VERSION ""

NS_ :

BS_:

BU_: FBD_HL IPB_App1 FBD_HM FBD_HR FBD_Miko FBD_MM FBD_Trunk FBD_VL FBD_VM FBD_VR Diagnosetool_CAN_FD_IPB_41

BO_ 900 TPBLEParameter_FBD_VM_FBD_MM: 64 FBD_VM
 SG_ TPBLEParameter_FBD_VM_FBD_MM_Byt : 0|8@1+ (1.0,0) [0|255] "" FBD_MM
 SG_ TPBLEParameter_FBD_VM_FBD_MM_B_2 : 8|8@1+ (1.0,0) [0|255] "" FBD_MM
 SG_ TPBLEParameter_FBD_VM_FBD_MM_B_3 : 16|8@1+ (1.0,0) [0|255] "" FBD_MM
 SG_ TPBLEParameter_FBD_VM_FBD_MM_B_4 : 24|8@1+ (1.0,0) [0|255] "" FBD_MM
 SG_ TPBLEParameter_FBD_VM_FBD_MM_B_5 : 32|8@1+ (1.0,0) [0|255] "" FBD_MM
 SG_ TPBLEParameter_FBD_VM_FBD_MM_B_6 : 40|8@1+ (1.0,0) [0|255] "" FBD_MM
 SG_ TPBLEParameter_FBD_VM_FBD_MM_B_7 : 48|8@1+ (1.0,0) [0|255] "" FBD_MM
 SG_ TPBLEParameter_FBD_VM_FBD_MM_B_8 : 56|8@1+ (1.0,0) [0|255] "" FBD_MM
 SG_ TPBLEParameter_FBD_VM_FBD_MM_B_9 : 64|8@1+ (1.0,0) [0|255] "" FBD_MM
 SG_ TPBLEParameter_FBD_VM_FBD_MM__10 : 72|8@1+ (1.0,0) [0|255] "" FBD_MM
 SG_ TPBLEParameter_FBD_VM_FBD_MM__11 : 80|8@1+ (1.0,0) [0|255] "" FBD_MM
 SG_ TPBLEParameter_FBD_VM_FBD_MM__12 : 88|8@1+ (1.0,0) [0|255] "" FBD_MM
 SG_ TPBLEParameter_FBD_VM_FBD_MM__13 : 96|8@1+ (1.0,0) [0|255] "" FBD_MM
 SG_ TPBLEParameter_FBD_VM_FBD_MM__14 : 104|8@1+ (1.0,0) [0|255] "" FBD_MM
 SG_ TPBLEParameter_FBD_VM_FBD_MM__15 : 112|8@1+ (1.0,0) [0|255] "" FBD_MM
 SG_ TPBLEParameter_FBD_VM_FBD_MM__16 : 120|8@1+ (1.0,0) [0|255] "" FBD_MM
 SG_ TPBLEParameter_FBD_VM_FBD_MM__17 : 128|8@1+ (1.0,0) [0|255] "" FBD_MM
 SG_ TPBLEParameter_FBD_VM_FBD_MM__18 : 136|8@1+ (1.0,0) [0|255] "" FBD_MM
 SG_ TPBLEParameter_FBD_VM_FBD_MM__19 : 144|8@1+ (1.0,0) [0|255] "" FBD_MM
 SG_ TPBLEParameter_FBD_VM_FBD_MM__20 : 152|8@1+ (1.0,0) [0|255] "" FBD_MM
 SG_ TPBLEParameter_FBD_VM_FBD_MM__21 : 160|8@1+ (1.0,0) [0|255] "" FBD_MM
 SG_ TPBLEParameter_FBD_VM_FBD_MM__22 : 168|8@1+ (1.0,0) [0|255] "" FBD_MM
 SG_ TPBLEParameter_FBD_VM_FBD_MM__23 : 176|8@1+ (1.0,0) [0|255] "" FBD_MM
 SG_ TPBLEParameter_FBD_VM_FBD_MM__24 : 184|8@1+ (1.0,0) [0|255] "" FBD_MM
 SG_ TPBLEParameter_FBD_VM_FBD_MM__25 : 192|8@1+ (1.0,0) [0|255] "" FBD_MM
 SG_ TPBLEParameter_FBD_VM_FBD_MM__26 : 200|8@1+ (1.0,0) [0|255] "" FBD_MM
 SG_ TPBLEParameter_FBD_VM_FBD_MM__27 : 208|8@1+ (1.0,0) [0|255] "" FBD_MM
 SG_ TPBLEParameter_FBD_VM_FBD_MM__28 : 216|8@1+ (1.0,0) [0|255] "" FBD_MM
 SG_ TPBLEParameter_FBD_VM_FBD_MM__29 : 224|8@1+ (1.0,0) [0|255] "" FBD_MM
 SG_ TPBLEParameter_FBD_VM_FBD_MM__30 : 232|8@1+ (1.0,0) [0|255] "" FBD_MM
 SG_ TPBLEParameter_FBD_VM_FBD_MM__31 : 240|8@1+ (1.0,0) [0|255] "" FBD_MM
 SG_ TPBLEParameter_FBD_VM_FBD_MM__32 : 248|8@1+ (1.0,0) [0|255] "" FBD_MM
 SG_ TPBLEParameter_FBD_VM_FBD_MM__33 : 256|8@1+ (1.0,0) [0|255] "" FBD_MM
 SG_ TPBLEParameter_FBD_VM_FBD_MM__34 : 264|8@1+ (1.0,0) [0|255] "" FBD_MM
 SG_ TPBLEParameter_FBD_VM_FBD_MM__35 : 272|8@1+ (1.0,0) [0|255] "" FBD_MM
 SG_ TPBLEParameter_FBD_VM_FBD_MM__36 : 280|8@1+ (1.0,0) [0|255] "" FBD_MM
 SG_ TPBLEParameter_FBD_VM_FBD_MM__37 : 288|8@1+ (1.0,0) [0|255] "" FBD_MM
 SG_ TPBLEParameter_FBD_VM_FBD_MM__38 : 296|8@1+ (1.0,0) [0|255] "" FBD_MM
 SG_ TPBLEParameter_FBD_VM_FBD_MM__39 : 304|8@1+ (1.0,0) [0|255] "" FBD_MM
 SG_ TPBLEParameter_FBD_VM_FBD_MM__40 : 312|8@1+ (1.0,0) [0|255] "" FBD_MM
 SG_ TPBLEParameter_FBD_VM_FBD_MM__41 : 320|8@1+ (1.0,0) [0|255] "" FBD_MM
 SG_ TPBLEParameter_FBD_VM_FBD_MM__42 : 328|8@1+ (1.0,0) [0|255] "" FBD_MM
 SG_ TPBLEParameter_FBD_VM_FBD_MM__43 : 336|8@1+ (1.0,0) [0|255] "" FBD_MM
 SG_ TPBLEParameter_FBD_VM_FBD_MM__44 : 344|8@1+ (1.0,0) [0|255] "" FBD_MM
 SG_ TPBLEParameter_FBD_VM_FBD_MM__45 : 352|8@1+ (1.0,0) [0|255] "" FBD_MM
 SG_ TPBLEParameter_FBD_VM_FBD_MM__46 : 360|8@1+ (1.0,0) [0|255] "" FBD_MM
 SG_ TPBLEParameter_FBD_VM_FBD_MM__47 : 368|8@1+ (1.0,0) [0|255] "" FBD_MM
 SG_ TPBLEParameter_FBD_VM_FBD_MM__48 : 376|8@1+ (1.0,0) [0|255] "" FBD_MM
 SG_ TPBLEParameter_FBD_VM_FBD_MM__49 : 384|8@1+ (1.0,0) [0|255] "" FBD_MM
 SG_ TPBLEParameter_FBD_VM_FBD_MM__50 : 392|8@1+ (1.0,0) [0|255] "" FBD_MM
 SG_ TPBLEParameter_FBD_VM_FBD_MM__51 : 400|8@1+ (1.0,0) [0|255] "" FBD_MM
 SG_ TPBLEParameter_FBD_VM_FBD_MM__52 : 408|8@1+ (1.0,0) [0|255] "" FBD_MM
 SG_ TPBLEParameter_FBD_VM_FBD_MM__53 : 416|8@1+ (1.0,0) [0|255] "" FBD_MM
 SG_ TPBLEParameter_FBD_VM_FBD_MM__54 : 424|8@1+ (1.0,0) [0|255] "" FBD_MM
 SG_ TPBLEParameter_FBD_VM_FBD_MM__55 : 432|8@1+ (1.0,0) [0|255] "" FBD_MM
 SG_ TPBLEParameter_FBD_VM_FBD_MM__56 : 440|8@1+ (1.0,0) [0|255] "" FBD_MM
 SG_ TPBLEParameter_FBD_VM_FBD_MM__57 : 448|8@1+ (1.0,0) [0|255] "" FBD_MM
 SG_ TPBLEParameter_FBD_VM_FBD_MM__58 : 456|8@1+ (1.0,0) [0|255] "" FBD_MM
 SG_ TPBLEParameter_FBD_VM_FBD_MM__59 : 464|8@1+ (1.0,0) [0|255] "" FBD_MM
 SG_ TPBLEParameter_FBD_VM_FBD_MM__60 : 472|8@1+ (1.0,0) [0|255] "" FBD_MM
 SG_ TPBLEParameter_FBD_VM_FBD_MM__61 : 480|8@1+ (1.0,0) [0|255] "" FBD_MM
 SG_ TPBLEParameter_FBD_VM_FBD_MM__62 : 488|8@1+ (1.0,0) [0|255] "" FBD_MM
 SG_ TPBLEParameter_FBD_VM_FBD_MM__63 : 496|8@1+ (1.0,0) [0|255] "" FBD_MM
 SG_ TPBLEParameter_FBD_VM_FBD_MM__64 : 504|8@1+ (1.0,0) [0|255] "" FBD_MM

BO_ 903 TPBLEParameter_FBD_VM_FBD_Trunk: 64 FBD_VM
 SG_ TPBLEParameter_FBD_VM_FBD_Trunk_ : 0|8@1+ (1.0,0) [0|255] "" FBD_Trunk
 SG_ TPBLEParameter_FBD_VM_FBD_Trun_2 : 8|8@1+ (1.0,0) [0|255] "" FBD_Trunk
 SG_ TPBLEParameter_FBD_VM_FBD_Trun_3 : 16|8@1+ (1.0,0) [0|255] "" FBD_Trunk
 SG_ TPBLEParameter_FBD_VM_FBD_Trun_4 : 24|8@1+ (1.0,0) [0|255] "" FBD_Trunk
 SG_ TPBLEParameter_FBD_VM_FBD_Trun_5 : 32|8@1+ (1.0,0) [0|255] "" FBD_Trunk
 SG_ TPBLEParameter_FBD_VM_FBD_Trun_6 : 40|8@1+ (1.0,0) [0|255] "" FBD_Trunk
 SG_ TPBLEParameter_FBD_VM_FBD_Trun_7 : 48|8@1+ (1.0,0) [0|255] "" FBD_Trunk
 SG_ TPBLEParameter_FBD_VM_FBD_Trun_8 : 56|8@1+ (1.0,0) [0|255] "" FBD_Trunk
 SG_ TPBLEParameter_FBD_VM_FBD_Trun_9 : 64|8@1+ (1.0,0) [0|255] "" FBD_Trunk
 SG_ TPBLEParameter_FBD_VM_FBD_Tru_10 : 72|8@1+ (1.0,0) [0|255] "" FBD_Trunk
 SG_ TPBLEParameter_FBD_VM_FBD_Tru_11 : 80|8@1+ (1.0,0) [0|255] "" FBD_Trunk
 SG_ TPBLEParameter_FBD_VM_FBD_Tru_12 : 88|8@1+ (1.0,0) [0|255] "" FBD_Trunk
 SG_ TPBLEParameter_FBD_VM_FBD_Tru_13 : 96|8@1+ (1.0,0) [0|255] "" FBD_Trunk
 SG_ TPBLEParameter_FBD_VM_FBD_Tru_14 : 104|8@1+ (1.0,0) [0|255] "" FBD_Trunk
 SG_ TPBLEParameter_FBD_VM_FBD_Tru_15 : 112|8@1+ (1.0,0) [0|255] "" FBD_Trunk
 SG_ TPBLEParameter_FBD_VM_FBD_Tru_16 : 120|8@1+ (1.0,0) [0|255] "" FBD_Trunk
 SG_ TPBLEParameter_FBD_VM_FBD_Tru_17 : 128|8@1+ (1.0,0) [0|255] "" FBD_Trunk
 SG_ TPBLEParameter_FBD_VM_FBD_Tru_18 : 136|8@1+ (1.0,0) [0|255] "" FBD_Trunk
 SG_ TPBLEParameter_FBD_VM_FBD_Tru_19 : 144|8@1+ (1.0,0) [0|255] "" FBD_Trunk
 SG_ TPBLEParameter_FBD_VM_FBD_Tru_20 : 152|8@1+ (1.0,0) [0|255] "" FBD_Trunk
 SG_ TPBLEParameter_FBD_VM_FBD_Tru_21 : 160|8@1+ (1.0,0) [0|255] "" FBD_Trunk
 SG_ TPBLEParameter_FBD_VM_FBD_Tru_22 : 168|8@1+ (1.0,0) [0|255] "" FBD_Trunk
 SG_ TPBLEParameter_FBD_VM_FBD_Tru_23 : 176|8@1+ (1.0,0) [0|255] "" FBD_Trunk
 SG_ TPBLEParameter_FBD_VM_FBD_Tru_24 : 184|8@1+ (1.0,0) [0|255] "" FBD_Trunk
 SG_ TPBLEParameter_FBD_VM_FBD_Tru_25 : 192|8@1+ (1.0,0) [0|255] "" FBD_Trunk
 SG_ TPBLEParameter_FBD_VM_FBD_Tru_26 : 200|8@1+ (1.0,0) [0|255] "" FBD_Trunk
 SG_ TPBLEParameter_FBD_VM_FBD_Tru_27 : 208|8@1+ (1.0,0) [0|255] "" FBD_Trunk
 SG_ TPBLEParameter_FBD_VM_FBD_Tru_28 : 216|8@1+ (1.0,0) [0|255] "" FBD_Trunk
 SG_ TPBLEParameter_FBD_VM_FBD_Tru_29 : 224|8@1+ (1.0,0) [0|255] "" FBD_Trunk
 SG_ TPBLEParameter_FBD_VM_FBD_Tru_30 : 232|8@1+ (1.0,0) [0|255] "" FBD_Trunk
 SG_ TPBLEParameter_FBD_VM_FBD_Tru_31 : 240|8@1+ (1.0,0) [0|255] "" FBD_Trunk
 SG_ TPBLEParameter_FBD_VM_FBD_Tru_32 : 248|8@1+ (1.0,0) [0|255] "" FBD_Trunk
 SG_ TPBLEParameter_FBD_VM_FBD_Tru_33 : 256|8@1+ (1.0,0) [0|255] "" FBD_Trunk
 SG_ TPBLEParameter_FBD_VM_FBD_Tru_34 : 264|8@1+ (1.0,0) [0|255] "" FBD_Trunk
 SG_ TPBLEParameter_FBD_VM_FBD_Tru_35 : 272|8@1+ (1.0,0) [0|255] "" FBD_Trunk
 SG_ TPBLEParameter_FBD_VM_FBD_Tru_36 : 280|8@1+ (1.0,0) [0|255] "" FBD_Trunk
 SG_ TPBLEParameter_FBD_VM_FBD_Tru_37 : 288|8@1+ (1.0,0) [0|255] "" FBD_Trunk
 SG_ TPBLEParameter_FBD_VM_FBD_Tru_38 : 296|8@1+ (1.0,0) [0|255] "" FBD_Trunk
 SG_ TPBLEParameter_FBD_VM_FBD_Tru_39 : 304|8@1+ (1.0,0) [0|255] "" FBD_Trunk
 SG_ TPBLEParameter_FBD_VM_FBD_Tru_40 : 312|8@1+ (1.0,0) [0|255] "" FBD_Trunk
 SG_ TPBLEParameter_FBD_VM_FBD_Tru_41 : 320|8@1+ (1.0,0) [0|255] "" FBD_Trunk
 SG_ TPBLEParameter_FBD_VM_FBD_Tru_42 : 328|8@1+ (1.0,0) [0|255] "" FBD_Trunk
 SG_ TPBLEParameter_FBD_VM_FBD_Tru_43 : 336|8@1+ (1.0,0) [0|255] "" FBD_Trunk
 SG_ TPBLEParameter_FBD_VM_FBD_Tru_44 : 344|8@1+ (1.0,0) [0|255] "" FBD_Trunk
 SG_ TPBLEParameter_FBD_VM_FBD_Tru_45 : 352|8@1+ (1.0,0) [0|255] "" FBD_Trunk
 SG_ TPBLEParameter_FBD_VM_FBD_Tru_46 : 360|8@1+ (1.0,0) [0|255] "" FBD_Trunk
 SG_ TPBLEParameter_FBD_VM_FBD_Tru_47 : 368|8@1+ (1.0,0) [0|255] "" FBD_Trunk
 SG_ TPBLEParameter_FBD_VM_FBD_Tru_48 : 376|8@1+ (1.0,0) [0|255] "" FBD_Trunk
 SG_ TPBLEParameter_FBD_VM_FBD_Tru_49 : 384|8@1+ (1.0,0) [0|255] "" FBD_Trunk
 SG_ TPBLEParameter_FBD_VM_FBD_Tru_50 : 392|8@1+ (1.0,0) [0|255] "" FBD_Trunk
 SG_ TPBLEParameter_FBD_VM_FBD_Tru_51 : 400|8@1+ (1.0,0) [0|255] "" FBD_Trunk
 SG_ TPBLEParameter_FBD_VM_FBD_Tru_52 : 408|8@1+ (1.0,0) [0|255] "" FBD_Trunk
 SG_ TPBLEParameter_FBD_VM_FBD_Tru_53 : 416|8@1+ (1.0,0) [0|255] "" FBD_Trunk
 SG_ TPBLEParameter_FBD_VM_FBD_Tru_54 : 424|8@1+ (1.0,0) [0|255] "" FBD_Trunk
 SG_ TPBLEParameter_FBD_VM_FBD_Tru_55 : 432|8@1+ (1.0,0) [0|255] "" FBD_Trunk
 SG_ TPBLEParameter_FBD_VM_FBD_Tru_56 : 440|8@1+ (1.0,0) [0|255] "" FBD_Trunk
 SG_ TPBLEParameter_FBD_VM_FBD_Tru_57 : 448|8@1+ (1.0,0) [0|255] "" FBD_Trunk
 SG_ TPBLEParameter_FBD_VM_FBD_Tru_58 : 456|8@1+ (1.0,0) [0|255] "" FBD_Trunk
 SG_ TPBLEParameter_FBD_VM_FBD_Tru_59 : 464|8@1+ (1.0,0) [0|255] "" FBD_Trunk
 SG_ TPBLEParameter_FBD_VM_FBD_Tru_60 : 472|8@1+ (1.0,0) [0|255] "" FBD_Trunk
 SG_ TPBLEParameter_FBD_VM_FBD_Tru_61 : 480|8@1+ (1.0,0) [0|255] "" FBD_Trunk
 SG_ TPBLEParameter_FBD_VM_FBD_Tru_62 : 488|8@1+ (1.0,0) [0|255] "" FBD_Trunk
 SG_ TPBLEParameter_FBD_VM_FBD_Tru_63 : 496|8@1+ (1.0,0) [0|255] "" FBD_Trunk
 SG_ TPBLEParameter_FBD_VM_FBD_Tru_64 : 504|8@1+ (1.0,0) [0|255] "" FBD_Trunk

BO_ 904 TPBLEParameter_FBD_VM_FBD_VL: 64 FBD_VM
 SG_ TPBLEParameter_FBD_VM_FBD_VL_Byt : 0|8@1+ (1.0,0) [0|255] "" FBD_VL
 SG_ TPBLEParameter_FBD_VM_FBD_VL_B_2 : 8|8@1+ (1.0,0) [0|255] "" FBD_VL
 SG_ TPBLEParameter_FBD_VM_FBD_VL_B_3 : 16|8@1+ (1.0,0) [0|255] "" FBD_VL
 SG_ TPBLEParameter_FBD_VM_FBD_VL_B_4 : 24|8@1+ (1.0,0) [0|255] "" FBD_VL
 SG_ TPBLEParameter_FBD_VM_FBD_VL_B_5 : 32|8@1+ (1.0,0) [0|255] "" FBD_VL
 SG_ TPBLEParameter_FBD_VM_FBD_VL_B_6 : 40|8@1+ (1.0,0) [0|255] "" FBD_VL
 SG_ TPBLEParameter_FBD_VM_FBD_VL_B_7 : 48|8@1+ (1.0,0) [0|255] "" FBD_VL
 SG_ TPBLEParameter_FBD_VM_FBD_VL_B_8 : 56|8@1+ (1.0,0) [0|255] "" FBD_VL
 SG_ TPBLEParameter_FBD_VM_FBD_VL_B_9 : 64|8@1+ (1.0,0) [0|255] "" FBD_VL
 SG_ TPBLEParameter_FBD_VM_FBD_VL__10 : 72|8@1+ (1.0,0) [0|255] "" FBD_VL
 SG_ TPBLEParameter_FBD_VM_FBD_VL__11 : 80|8@1+ (1.0,0) [0|255] "" FBD_VL
 SG_ TPBLEParameter_FBD_VM_FBD_VL__12 : 88|8@1+ (1.0,0) [0|255] "" FBD_VL
 SG_ TPBLEParameter_FBD_VM_FBD_VL__13 : 96|8@1+ (1.0,0) [0|255] "" FBD_VL
 SG_ TPBLEParameter_FBD_VM_FBD_VL__14 : 104|8@1+ (1.0,0) [0|255] "" FBD_VL
 SG_ TPBLEParameter_FBD_VM_FBD_VL__15 : 112|8@1+ (1.0,0) [0|255] "" FBD_VL
 SG_ TPBLEParameter_FBD_VM_FBD_VL__16 : 120|8@1+ (1.0,0) [0|255] "" FBD_VL
 SG_ TPBLEParameter_FBD_VM_FBD_VL__17 : 128|8@1+ (1.0,0) [0|255] "" FBD_VL
 SG_ TPBLEParameter_FBD_VM_FBD_VL__18 : 136|8@1+ (1.0,0) [0|255] "" FBD_VL
 SG_ TPBLEParameter_FBD_VM_FBD_VL__19 : 144|8@1+ (1.0,0) [0|255] "" FBD_VL
 SG_ TPBLEParameter_FBD_VM_FBD_VL__20 : 152|8@1+ (1.0,0) [0|255] "" FBD_VL
 SG_ TPBLEParameter_FBD_VM_FBD_VL__21 : 160|8@1+ (1.0,0) [0|255] "" FBD_VL
 SG_ TPBLEParameter_FBD_VM_FBD_VL__22 : 168|8@1+ (1.0,0) [0|255] "" FBD_VL
 SG_ TPBLEParameter_FBD_VM_FBD_VL__23 : 176|8@1+ (1.0,0) [0|255] "" FBD_VL
 SG_ TPBLEParameter_FBD_VM_FBD_VL__24 : 184|8@1+ (1.0,0) [0|255] "" FBD_VL
 SG_ TPBLEParameter_FBD_VM_FBD_VL__25 : 192|8@1+ (1.0,0) [0|255] "" FBD_VL
 SG_ TPBLEParameter_FBD_VM_FBD_VL__26 : 200|8@1+ (1.0,0) [0|255] "" FBD_VL
 SG_ TPBLEParameter_FBD_VM_FBD_VL__27 : 208|8@1+ (1.0,0) [0|255] "" FBD_VL
 SG_ TPBLEParameter_FBD_VM_FBD_VL__28 : 216|8@1+ (1.0,0) [0|255] "" FBD_VL
 SG_ TPBLEParameter_FBD_VM_FBD_VL__29 : 224|8@1+ (1.0,0) [0|255] "" FBD_VL
 SG_ TPBLEParameter_FBD_VM_FBD_VL__30 : 232|8@1+ (1.0,0) [0|255] "" FBD_VL
 SG_ TPBLEParameter_FBD_VM_FBD_VL__31 : 240|8@1+ (1.0,0) [0|255] "" FBD_VL
 SG_ TPBLEParameter_FBD_VM_FBD_VL__32 : 248|8@1+ (1.0,0) [0|255] "" FBD_VL
 SG_ TPBLEParameter_FBD_VM_FBD_VL__33 : 256|8@1+ (1.0,0) [0|255] "" FBD_VL
 SG_ TPBLEParameter_FBD_VM_FBD_VL__34 : 264|8@1+ (1.0,0) [0|255] "" FBD_VL
 SG_ TPBLEParameter_FBD_VM_FBD_VL__35 : 272|8@1+ (1.0,0) [0|255] "" FBD_VL
 SG_ TPBLEParameter_FBD_VM_FBD_VL__36 : 280|8@1+ (1.0,0) [0|255] "" FBD_VL
 SG_ TPBLEParameter_FBD_VM_FBD_VL__37 : 288|8@1+ (1.0,0) [0|255] "" FBD_VL
 SG_ TPBLEParameter_FBD_VM_FBD_VL__38 : 296|8@1+ (1.0,0) [0|255] "" FBD_VL
 SG_ TPBLEParameter_FBD_VM_FBD_VL__39 : 304|8@1+ (1.0,0) [0|255] "" FBD_VL
 SG_ TPBLEParameter_FBD_VM_FBD_VL__40 : 312|8@1+ (1.0,0) [0|255] "" FBD_VL
 SG_ TPBLEParameter_FBD_VM_FBD_VL__41 : 320|8@1+ (1.0,0) [0|255] "" FBD_VL
 SG_ TPBLEParameter_FBD_VM_FBD_VL__42 : 328|8@1+ (1.0,0) [0|255] "" FBD_VL
 SG_ TPBLEParameter_FBD_VM_FBD_VL__43 : 336|8@1+ (1.0,0) [0|255] "" FBD_VL
 SG_ TPBLEParameter_FBD_VM_FBD_VL__44 : 344|8@1+ (1.0,0) [0|255] "" FBD_VL
 SG_ TPBLEParameter_FBD_VM_FBD_VL__45 : 352|8@1+ (1.0,0) [0|255] "" FBD_VL
 SG_ TPBLEParameter_FBD_VM_FBD_VL__46 : 360|8@1+ (1.0,0) [0|255] "" FBD_VL
 SG_ TPBLEParameter_FBD_VM_FBD_VL__47 : 368|8@1+ (1.0,0) [0|255] "" FBD_VL
 SG_ TPBLEParameter_FBD_VM_FBD_VL__48 : 376|8@1+ (1.0,0) [0|255] "" FBD_VL
 SG_ TPBLEParameter_FBD_VM_FBD_VL__49 : 384|8@1+ (1.0,0) [0|255] "" FBD_VL
 SG_ TPBLEParameter_FBD_VM_FBD_VL__50 : 392|8@1+ (1.0,0) [0|255] "" FBD_VL
 SG_ TPBLEParameter_FBD_VM_FBD_VL__51 : 400|8@1+ (1.0,0) [0|255] "" FBD_VL
 SG_ TPBLEParameter_FBD_VM_FBD_VL__52 : 408|8@1+ (1.0,0) [0|255] "" FBD_VL
 SG_ TPBLEParameter_FBD_VM_FBD_VL__53 : 416|8@1+ (1.0,0) [0|255] "" FBD_VL
 SG_ TPBLEParameter_FBD_VM_FBD_VL__54 : 424|8@1+ (1.0,0) [0|255] "" FBD_VL
 SG_ TPBLEParameter_FBD_VM_FBD_VL__55 : 432|8@1+ (1.0,0) [0|255] "" FBD_VL
 SG_ TPBLEParameter_FBD_VM_FBD_VL__56 : 440|8@1+ (1.0,0) [0|255] "" FBD_VL
 SG_ TPBLEParameter_FBD_VM_FBD_VL__57 : 448|8@1+ (1.0,0) [0|255] "" FBD_VL
 SG_ TPBLEParameter_FBD_VM_FBD_VL__58 : 456|8@1+ (1.0,0) [0|255] "" FBD_VL
 SG_ TPBLEParameter_FBD_VM_FBD_VL__59 : 464|8@1+ (1.0,0) [0|255] "" FBD_VL
 SG_ TPBLEParameter_FBD_VM_FBD_VL__60 : 472|8@1+ (1.0,0) [0|255] "" FBD_VL
 SG_ TPBLEParameter_FBD_VM_FBD_VL__61 : 480|8@1+ (1.0,0) [0|255] "" FBD_VL
 SG_ TPBLEParameter_FBD_VM_FBD_VL__62 : 488|8@1+ (1.0,0) [0|255] "" FBD_VL
 SG_ TPBLEParameter_FBD_VM_FBD_VL__63 : 496|8@1+ (1.0,0) [0|255] "" FBD_VL
 SG_ TPBLEParameter_FBD_VM_FBD_VL__64 : 504|8@1+ (1.0,0) [0|255] "" FBD_VL

BO_ 905 TPBLEParameter_FBD_VM_FBD_VR: 64 FBD_VM
 SG_ TPBLEParameter_FBD_VM_FBD_VR_Byt : 0|8@1+ (1.0,0) [0|255] "" FBD_VR
 SG_ TPBLEParameter_FBD_VM_FBD_VR_B_2 : 8|8@1+ (1.0,0) [0|255] "" FBD_VR
 SG_ TPBLEParameter_FBD_VM_FBD_VR_B_3 : 16|8@1+ (1.0,0) [0|255] "" FBD_VR
 SG_ TPBLEParameter_FBD_VM_FBD_VR_B_4 : 24|8@1+ (1.0,0) [0|255] "" FBD_VR
 SG_ TPBLEParameter_FBD_VM_FBD_VR_B_5 : 32|8@1+ (1.0,0) [0|255] "" FBD_VR
 SG_ TPBLEParameter_FBD_VM_FBD_VR_B_6 : 40|8@1+ (1.0,0) [0|255] "" FBD_VR
 SG_ TPBLEParameter_FBD_VM_FBD_VR_B_7 : 48|8@1+ (1.0,0) [0|255] "" FBD_VR
 SG_ TPBLEParameter_FBD_VM_FBD_VR_B_8 : 56|8@1+ (1.0,0) [0|255] "" FBD_VR
 SG_ TPBLEParameter_FBD_VM_FBD_VR_B_9 : 64|8@1+ (1.0,0) [0|255] "" FBD_VR
 SG_ TPBLEParameter_FBD_VM_FBD_VR__10 : 72|8@1+ (1.0,0) [0|255] "" FBD_VR
 SG_ TPBLEParameter_FBD_VM_FBD_VR__11 : 80|8@1+ (1.0,0) [0|255] "" FBD_VR
 SG_ TPBLEParameter_FBD_VM_FBD_VR__12 : 88|8@1+ (1.0,0) [0|255] "" FBD_VR
 SG_ TPBLEParameter_FBD_VM_FBD_VR__13 : 96|8@1+ (1.0,0) [0|255] "" FBD_VR
 SG_ TPBLEParameter_FBD_VM_FBD_VR__14 : 104|8@1+ (1.0,0) [0|255] "" FBD_VR
 SG_ TPBLEParameter_FBD_VM_FBD_VR__15 : 112|8@1+ (1.0,0) [0|255] "" FBD_VR
 SG_ TPBLEParameter_FBD_VM_FBD_VR__16 : 120|8@1+ (1.0,0) [0|255] "" FBD_VR
 SG_ TPBLEParameter_FBD_VM_FBD_VR__17 : 128|8@1+ (1.0,0) [0|255] "" FBD_VR
 SG_ TPBLEParameter_FBD_VM_FBD_VR__18 : 136|8@1+ (1.0,0) [0|255] "" FBD_VR
 SG_ TPBLEParameter_FBD_VM_FBD_VR__19 : 144|8@1+ (1.0,0) [0|255] "" FBD_VR
 SG_ TPBLEParameter_FBD_VM_FBD_VR__20 : 152|8@1+ (1.0,0) [0|255] "" FBD_VR
 SG_ TPBLEParameter_FBD_VM_FBD_VR__21 : 160|8@1+ (1.0,0) [0|255] "" FBD_VR
 SG_ TPBLEParameter_FBD_VM_FBD_VR__22 : 168|8@1+ (1.0,0) [0|255] "" FBD_VR
 SG_ TPBLEParameter_FBD_VM_FBD_VR__23 : 176|8@1+ (1.0,0) [0|255] "" FBD_VR
 SG_ TPBLEParameter_FBD_VM_FBD_VR__24 : 184|8@1+ (1.0,0) [0|255] "" FBD_VR
 SG_ TPBLEParameter_FBD_VM_FBD_VR__25 : 192|8@1+ (1.0,0) [0|255] "" FBD_VR
 SG_ TPBLEParameter_FBD_VM_FBD_VR__26 : 200|8@1+ (1.0,0) [0|255] "" FBD_VR
 SG_ TPBLEParameter_FBD_VM_FBD_VR__27 : 208|8@1+ (1.0,0) [0|255] "" FBD_VR
 SG_ TPBLEParameter_FBD_VM_FBD_VR__28 : 216|8@1+ (1.0,0) [0|255] "" FBD_VR
 SG_ TPBLEParameter_FBD_VM_FBD_VR__29 : 224|8@1+ (1.0,0) [0|255] "" FBD_VR
 SG_ TPBLEParameter_FBD_VM_FBD_VR__30 : 232|8@1+ (1.0,0) [0|255] "" FBD_VR
 SG_ TPBLEParameter_FBD_VM_FBD_VR__31 : 240|8@1+ (1.0,0) [0|255] "" FBD_VR
 SG_ TPBLEParameter_FBD_VM_FBD_VR__32 : 248|8@1+ (1.0,0) [0|255] "" FBD_VR
 SG_ TPBLEParameter_FBD_VM_FBD_VR__33 : 256|8@1+ (1.0,0) [0|255] "" FBD_VR
 SG_ TPBLEParameter_FBD_VM_FBD_VR__34 : 264|8@1+ (1.0,0) [0|255] "" FBD_VR
 SG_ TPBLEParameter_FBD_VM_FBD_VR__35 : 272|8@1+ (1.0,0) [0|255] "" FBD_VR
 SG_ TPBLEParameter_FBD_VM_FBD_VR__36 : 280|8@1+ (1.0,0) [0|255] "" FBD_VR
 SG_ TPBLEParameter_FBD_VM_FBD_VR__37 : 288|8@1+ (1.0,0) [0|255] "" FBD_VR
 SG_ TPBLEParameter_FBD_VM_FBD_VR__38 : 296|8@1+ (1.0,0) [0|255] "" FBD_VR
 SG_ TPBLEParameter_FBD_VM_FBD_VR__39 : 304|8@1+ (1.0,0) [0|255] "" FBD_VR
 SG_ TPBLEParameter_FBD_VM_FBD_VR__40 : 312|8@1+ (1.0,0) [0|255] "" FBD_VR
 SG_ TPBLEParameter_FBD_VM_FBD_VR__41 : 320|8@1+ (1.0,0) [0|255] "" FBD_VR
 SG_ TPBLEParameter_FBD_VM_FBD_VR__42 : 328|8@1+ (1.0,0) [0|255] "" FBD_VR
 SG_ TPBLEParameter_FBD_VM_FBD_VR__43 : 336|8@1+ (1.0,0) [0|255] "" FBD_VR
 SG_ TPBLEParameter_FBD_VM_FBD_VR__44 : 344|8@1+ (1.0,0) [0|255] "" FBD_VR
 SG_ TPBLEParameter_FBD_VM_FBD_VR__45 : 352|8@1+ (1.0,0) [0|255] "" FBD_VR
 SG_ TPBLEParameter_FBD_VM_FBD_VR__46 : 360|8@1+ (1.0,0) [0|255] "" FBD_VR
 SG_ TPBLEParameter_FBD_VM_FBD_VR__47 : 368|8@1+ (1.0,0) [0|255] "" FBD_VR
 SG_ TPBLEParameter_FBD_VM_FBD_VR__48 : 376|8@1+ (1.0,0) [0|255] "" FBD_VR
 SG_ TPBLEParameter_FBD_VM_FBD_VR__49 : 384|8@1+ (1.0,0) [0|255] "" FBD_VR
 SG_ TPBLEParameter_FBD_VM_FBD_VR__50 : 392|8@1+ (1.0,0) [0|255] "" FBD_VR
 SG_ TPBLEParameter_FBD_VM_FBD_VR__51 : 400|8@1+ (1.0,0) [0|255] "" FBD_VR
 SG_ TPBLEParameter_FBD_VM_FBD_VR__52 : 408|8@1+ (1.0,0) [0|255] "" FBD_VR
 SG_ TPBLEParameter_FBD_VM_FBD_VR__53 : 416|8@1+ (1.0,0) [0|255] "" FBD_VR
 SG_ TPBLEParameter_FBD_VM_FBD_VR__54 : 424|8@1+ (1.0,0) [0|255] "" FBD_VR
 SG_ TPBLEParameter_FBD_VM_FBD_VR__55 : 432|8@1+ (1.0,0) [0|255] "" FBD_VR
 SG_ TPBLEParameter_FBD_VM_FBD_VR__56 : 440|8@1+ (1.0,0) [0|255] "" FBD_VR
 SG_ TPBLEParameter_FBD_VM_FBD_VR__57 : 448|8@1+ (1.0,0) [0|255] "" FBD_VR
 SG_ TPBLEParameter_FBD_VM_FBD_VR__58 : 456|8@1+ (1.0,0) [0|255] "" FBD_VR
 SG_ TPBLEParameter_FBD_VM_FBD_VR__59 : 464|8@1+ (1.0,0) [0|255] "" FBD_VR
 SG_ TPBLEParameter_FBD_VM_FBD_VR__60 : 472|8@1+ (1.0,0) [0|255] "" FBD_VR
 SG_ TPBLEParameter_FBD_VM_FBD_VR__61 : 480|8@1+ (1.0,0) [0|255] "" FBD_VR
 SG_ TPBLEParameter_FBD_VM_FBD_VR__62 : 488|8@1+ (1.0,0) [0|255] "" FBD_VR
 SG_ TPBLEParameter_FBD_VM_FBD_VR__63 : 496|8@1+ (1.0,0) [0|255] "" FBD_VR
 SG_ TPBLEParameter_FBD_VM_FBD_VR__64 : 504|8@1+ (1.0,0) [0|255] "" FBD_VR

BO_ 915 TPBLEParameter_FBD_VR_FBD_VM: 64 FBD_VR
 SG_ TPBLEParameter_FBD_VR_FBD_VM_Byt : 0|8@1+ (1.0,0) [0|255] "" FBD_VM
 SG_ TPBLEParameter_FBD_VR_FBD_VM_B_2 : 8|8@1+ (1.0,0) [0|255] "" FBD_VM
 SG_ TPBLEParameter_FBD_VR_FBD_VM_B_3 : 16|8@1+ (1.0,0) [0|255] "" FBD_VM
 SG_ TPBLEParameter_FBD_VR_FBD_VM_B_4 : 24|8@1+ (1.0,0) [0|255] "" FBD_VM
 SG_ TPBLEParameter_FBD_VR_FBD_VM_B_5 : 32|8@1+ (1.0,0) [0|255] "" FBD_VM
 SG_ TPBLEParameter_FBD_VR_FBD_VM_B_6 : 40|8@1+ (1.0,0) [0|255] "" FBD_VM
 SG_ TPBLEParameter_FBD_VR_FBD_VM_B_7 : 48|8@1+ (1.0,0) [0|255] "" FBD_VM
 SG_ TPBLEParameter_FBD_VR_FBD_VM_B_8 : 56|8@1+ (1.0,0) [0|255] "" FBD_VM
 SG_ TPBLEParameter_FBD_VR_FBD_VM_B_9 : 64|8@1+ (1.0,0) [0|255] "" FBD_VM
 SG_ TPBLEParameter_FBD_VR_FBD_VM__10 : 72|8@1+ (1.0,0) [0|255] "" FBD_VM
 SG_ TPBLEParameter_FBD_VR_FBD_VM__11 : 80|8@1+ (1.0,0) [0|255] "" FBD_VM
 SG_ TPBLEParameter_FBD_VR_FBD_VM__12 : 88|8@1+ (1.0,0) [0|255] "" FBD_VM
 SG_ TPBLEParameter_FBD_VR_FBD_VM__13 : 96|8@1+ (1.0,0) [0|255] "" FBD_VM
 SG_ TPBLEParameter_FBD_VR_FBD_VM__14 : 104|8@1+ (1.0,0) [0|255] "" FBD_VM
 SG_ TPBLEParameter_FBD_VR_FBD_VM__15 : 112|8@1+ (1.0,0) [0|255] "" FBD_VM
 SG_ TPBLEParameter_FBD_VR_FBD_VM__16 : 120|8@1+ (1.0,0) [0|255] "" FBD_VM
 SG_ TPBLEParameter_FBD_VR_FBD_VM__17 : 128|8@1+ (1.0,0) [0|255] "" FBD_VM
 SG_ TPBLEParameter_FBD_VR_FBD_VM__18 : 136|8@1+ (1.0,0) [0|255] "" FBD_VM
 SG_ TPBLEParameter_FBD_VR_FBD_VM__19 : 144|8@1+ (1.0,0) [0|255] "" FBD_VM
 SG_ TPBLEParameter_FBD_VR_FBD_VM__20 : 152|8@1+ (1.0,0) [0|255] "" FBD_VM
 SG_ TPBLEParameter_FBD_VR_FBD_VM__21 : 160|8@1+ (1.0,0) [0|255] "" FBD_VM
 SG_ TPBLEParameter_FBD_VR_FBD_VM__22 : 168|8@1+ (1.0,0) [0|255] "" FBD_VM
 SG_ TPBLEParameter_FBD_VR_FBD_VM__23 : 176|8@1+ (1.0,0) [0|255] "" FBD_VM
 SG_ TPBLEParameter_FBD_VR_FBD_VM__24 : 184|8@1+ (1.0,0) [0|255] "" FBD_VM
 SG_ TPBLEParameter_FBD_VR_FBD_VM__25 : 192|8@1+ (1.0,0) [0|255] "" FBD_VM
 SG_ TPBLEParameter_FBD_VR_FBD_VM__26 : 200|8@1+ (1.0,0) [0|255] "" FBD_VM
 SG_ TPBLEParameter_FBD_VR_FBD_VM__27 : 208|8@1+ (1.0,0) [0|255] "" FBD_VM
 SG_ TPBLEParameter_FBD_VR_FBD_VM__28 : 216|8@1+ (1.0,0) [0|255] "" FBD_VM
 SG_ TPBLEParameter_FBD_VR_FBD_VM__29 : 224|8@1+ (1.0,0) [0|255] "" FBD_VM
 SG_ TPBLEParameter_FBD_VR_FBD_VM__30 : 232|8@1+ (1.0,0) [0|255] "" FBD_VM
 SG_ TPBLEParameter_FBD_VR_FBD_VM__31 : 240|8@1+ (1.0,0) [0|255] "" FBD_VM
 SG_ TPBLEParameter_FBD_VR_FBD_VM__32 : 248|8@1+ (1.0,0) [0|255] "" FBD_VM
 SG_ TPBLEParameter_FBD_VR_FBD_VM__33 : 256|8@1+ (1.0,0) [0|255] "" FBD_VM
 SG_ TPBLEParameter_FBD_VR_FBD_VM__34 : 264|8@1+ (1.0,0) [0|255] "" FBD_VM
 SG_ TPBLEParameter_FBD_VR_FBD_VM__35 : 272|8@1+ (1.0,0) [0|255] "" FBD_VM
 SG_ TPBLEParameter_FBD_VR_FBD_VM__36 : 280|8@1+ (1.0,0) [0|255] "" FBD_VM
 SG_ TPBLEParameter_FBD_VR_FBD_VM__37 : 288|8@1+ (1.0,0) [0|255] "" FBD_VM
 SG_ TPBLEParameter_FBD_VR_FBD_VM__38 : 296|8@1+ (1.0,0) [0|255] "" FBD_VM
 SG_ TPBLEParameter_FBD_VR_FBD_VM__39 : 304|8@1+ (1.0,0) [0|255] "" FBD_VM
 SG_ TPBLEParameter_FBD_VR_FBD_VM__40 : 312|8@1+ (1.0,0) [0|255] "" FBD_VM
 SG_ TPBLEParameter_FBD_VR_FBD_VM__41 : 320|8@1+ (1.0,0) [0|255] "" FBD_VM
 SG_ TPBLEParameter_FBD_VR_FBD_VM__42 : 328|8@1+ (1.0,0) [0|255] "" FBD_VM
 SG_ TPBLEParameter_FBD_VR_FBD_VM__43 : 336|8@1+ (1.0,0) [0|255] "" FBD_VM
 SG_ TPBLEParameter_FBD_VR_FBD_VM__44 : 344|8@1+ (1.0,0) [0|255] "" FBD_VM
 SG_ TPBLEParameter_FBD_VR_FBD_VM__45 : 352|8@1+ (1.0,0) [0|255] "" FBD_VM
 SG_ TPBLEParameter_FBD_VR_FBD_VM__46 : 360|8@1+ (1.0,0) [0|255] "" FBD_VM
 SG_ TPBLEParameter_FBD_VR_FBD_VM__47 : 368|8@1+ (1.0,0) [0|255] "" FBD_VM
 SG_ TPBLEParameter_FBD_VR_FBD_VM__48 : 376|8@1+ (1.0,0) [0|255] "" FBD_VM
 SG_ TPBLEParameter_FBD_VR_FBD_VM__49 : 384|8@1+ (1.0,0) [0|255] "" FBD_VM
 SG_ TPBLEParameter_FBD_VR_FBD_VM__50 : 392|8@1+ (1.0,0) [0|255] "" FBD_VM
 SG_ TPBLEParameter_FBD_VR_FBD_VM__51 : 400|8@1+ (1.0,0) [0|255] "" FBD_VM
 SG_ TPBLEParameter_FBD_VR_FBD_VM__52 : 408|8@1+ (1.0,0) [0|255] "" FBD_VM
 SG_ TPBLEParameter_FBD_VR_FBD_VM__53 : 416|8@1+ (1.0,0) [0|255] "" FBD_VM
 SG_ TPBLEParameter_FBD_VR_FBD_VM__54 : 424|8@1+ (1.0,0) [0|255] "" FBD_VM
 SG_ TPBLEParameter_FBD_VR_FBD_VM__55 : 432|8@1+ (1.0,0) [0|255] "" FBD_VM
 SG_ TPBLEParameter_FBD_VR_FBD_VM__56 : 440|8@1+ (1.0,0) [0|255] "" FBD_VM
 SG_ TPBLEParameter_FBD_VR_FBD_VM__57 : 448|8@1+ (1.0,0) [0|255] "" FBD_VM
 SG_ TPBLEParameter_FBD_VR_FBD_VM__58 : 456|8@1+ (1.0,0) [0|255] "" FBD_VM
 SG_ TPBLEParameter_FBD_VR_FBD_VM__59 : 464|8@1+ (1.0,0) [0|255] "" FBD_VM
 SG_ TPBLEParameter_FBD_VR_FBD_VM__60 : 472|8@1+ (1.0,0) [0|255] "" FBD_VM
 SG_ TPBLEParameter_FBD_VR_FBD_VM__61 : 480|8@1+ (1.0,0) [0|255] "" FBD_VM
 SG_ TPBLEParameter_FBD_VR_FBD_VM__62 : 488|8@1+ (1.0,0) [0|255] "" FBD_VM
 SG_ TPBLEParameter_FBD_VR_FBD_VM__63 : 496|8@1+ (1.0,0) [0|255] "" FBD_VM
 SG_ TPBLEParameter_FBD_VR_FBD_VM__64 : 504|8@1+ (1.0,0) [0|255] "" FBD_VM

BO_ 716 TPDiagnosisFlash_FBD_HL_IPB: 64 FBD_HL
 SG_ TPDiagnosisFlashFBD_HLIPB_Byte00 : 0|8@1+ (1.0,0) [0|252] "" IPB_App1
 SG_ TPDiagnosisFlashFBD_HLIPB_Byte01 : 8|8@1+ (1.0,0) [0|252] "" IPB_App1
 SG_ TPDiagnosisFlashFBD_HLIPB_Byte02 : 16|8@1+ (1.0,0) [0|252] "" IPB_App1
 SG_ TPDiagnosisFlashFBD_HLIPB_Byte03 : 24|8@1+ (1.0,0) [0|252] "" IPB_App1
 SG_ TPDiagnosisFlashFBD_HLIPB_Byte04 : 32|8@1+ (1.0,0) [0|252] "" IPB_App1
 SG_ TPDiagnosisFlashFBD_HLIPB_Byte05 : 40|8@1+ (1.0,0) [0|252] "" IPB_App1
 SG_ TPDiagnosisFlashFBD_HLIPB_Byte06 : 48|8@1+ (1.0,0) [0|252] "" IPB_App1
 SG_ TPDiagnosisFlashFBD_HLIPB_Byte07 : 56|8@1+ (1.0,0) [0|252] "" IPB_App1
 SG_ TPDiagnosisFlashFBD_HLIPB_Byte08 : 64|8@1+ (1.0,0) [0|252] "" IPB_App1
 SG_ TPDiagnosisFlashFBD_HLIPB_Byte09 : 72|8@1+ (1.0,0) [0|252] "" IPB_App1
 SG_ TPDiagnosisFlashFBD_HLIPB_Byte10 : 80|8@1+ (1.0,0) [0|252] "" IPB_App1
 SG_ TPDiagnosisFlashFBD_HLIPB_Byte11 : 88|8@1+ (1.0,0) [0|252] "" IPB_App1
 SG_ TPDiagnosisFlashFBD_HLIPB_Byte12 : 96|8@1+ (1.0,0) [0|252] "" IPB_App1
 SG_ TPDiagnosisFlashFBD_HLIPB_Byte13 : 104|8@1+ (1.0,0) [0|252] "" IPB_App1
 SG_ TPDiagnosisFlashFBD_HLIPB_Byte14 : 112|8@1+ (1.0,0) [0|252] "" IPB_App1
 SG_ TPDiagnosisFlashFBD_HLIPB_Byte15 : 120|8@1+ (1.0,0) [0|252] "" IPB_App1
 SG_ TPDiagnosisFlashFBD_HLIPB_Byte16 : 128|8@1+ (1.0,0) [0|252] "" IPB_App1
 SG_ TPDiagnosisFlashFBD_HLIPB_Byte17 : 136|8@1+ (1.0,0) [0|252] "" IPB_App1
 SG_ TPDiagnosisFlashFBD_HLIPB_Byte18 : 144|8@1+ (1.0,0) [0|252] "" IPB_App1
 SG_ TPDiagnosisFlashFBD_HLIPB_Byte19 : 152|8@1+ (1.0,0) [0|252] "" IPB_App1
 SG_ TPDiagnosisFlashFBD_HLIPB_Byte20 : 160|8@1+ (1.0,0) [0|252] "" IPB_App1
 SG_ TPDiagnosisFlashFBD_HLIPB_Byte21 : 168|8@1+ (1.0,0) [0|252] "" IPB_App1
 SG_ TPDiagnosisFlashFBD_HLIPB_Byte22 : 176|8@1+ (1.0,0) [0|252] "" IPB_App1
 SG_ TPDiagnosisFlashFBD_HLIPB_Byte23 : 184|8@1+ (1.0,0) [0|252] "" IPB_App1
 SG_ TPDiagnosisFlashFBD_HLIPB_Byte24 : 192|8@1+ (1.0,0) [0|252] "" IPB_App1
 SG_ TPDiagnosisFlashFBD_HLIPB_Byte25 : 200|8@1+ (1.0,0) [0|252] "" IPB_App1
 SG_ TPDiagnosisFlashFBD_HLIPB_Byte26 : 208|8@1+ (1.0,0) [0|252] "" IPB_App1
 SG_ TPDiagnosisFlashFBD_HLIPB_Byte27 : 216|8@1+ (1.0,0) [0|252] "" IPB_App1
 SG_ TPDiagnosisFlashFBD_HLIPB_Byte28 : 224|8@1+ (1.0,0) [0|252] "" IPB_App1
 SG_ TPDiagnosisFlashFBD_HLIPB_Byte29 : 232|8@1+ (1.0,0) [0|252] "" IPB_App1
 SG_ TPDiagnosisFlashFBD_HLIPB_Byte30 : 240|8@1+ (1.0,0) [0|252] "" IPB_App1
 SG_ TPDiagnosisFlashFBD_HLIPB_Byte31 : 248|8@1+ (1.0,0) [0|252] "" IPB_App1
 SG_ TPDiagnosisFlashFBD_HLIPB_Byte32 : 256|8@1+ (1.0,0) [0|252] "" IPB_App1
 SG_ TPDiagnosisFlashFBD_HLIPB_Byte33 : 264|8@1+ (1.0,0) [0|252] "" IPB_App1
 SG_ TPDiagnosisFlashFBD_HLIPB_Byte34 : 272|8@1+ (1.0,0) [0|252] "" IPB_App1
 SG_ TPDiagnosisFlashFBD_HLIPB_Byte35 : 280|8@1+ (1.0,0) [0|252] "" IPB_App1
 SG_ TPDiagnosisFlashFBD_HLIPB_Byte36 : 288|8@1+ (1.0,0) [0|252] "" IPB_App1
 SG_ TPDiagnosisFlashFBD_HLIPB_Byte37 : 296|8@1+ (1.0,0) [0|252] "" IPB_App1
 SG_ TPDiagnosisFlashFBD_HLIPB_Byte38 : 304|8@1+ (1.0,0) [0|252] "" IPB_App1
 SG_ TPDiagnosisFlashFBD_HLIPB_Byte39 : 312|8@1+ (1.0,0) [0|252] "" IPB_App1
 SG_ TPDiagnosisFlashFBD_HLIPB_Byte40 : 320|8@1+ (1.0,0) [0|252] "" IPB_App1
 SG_ TPDiagnosisFlashFBD_HLIPB_Byte41 : 328|8@1+ (1.0,0) [0|252] "" IPB_App1
 SG_ TPDiagnosisFlashFBD_HLIPB_Byte42 : 336|8@1+ (1.0,0) [0|252] "" IPB_App1
 SG_ TPDiagnosisFlashFBD_HLIPB_Byte43 : 344|8@1+ (1.0,0) [0|252] "" IPB_App1
 SG_ TPDiagnosisFlashFBD_HLIPB_Byte44 : 352|8@1+ (1.0,0) [0|252] "" IPB_App1
 SG_ TPDiagnosisFlashFBD_HLIPB_Byte45 : 360|8@1+ (1.0,0) [0|252] "" IPB_App1
 SG_ TPDiagnosisFlashFBD_HLIPB_Byte46 : 368|8@1+ (1.0,0) [0|252] "" IPB_App1
 SG_ TPDiagnosisFlashFBD_HLIPB_Byte47 : 376|8@1+ (1.0,0) [0|252] "" IPB_App1
 SG_ TPDiagnosisFlashFBD_HLIPB_Byte48 : 384|8@1+ (1.0,0) [0|252] "" IPB_App1
 SG_ TPDiagnosisFlashFBD_HLIPB_Byte49 : 392|8@1+ (1.0,0) [0|252] "" IPB_App1
 SG_ TPDiagnosisFlashFBD_HLIPB_Byte50 : 400|8@1+ (1.0,0) [0|252] "" IPB_App1
 SG_ TPDiagnosisFlashFBD_HLIPB_Byte51 : 408|8@1+ (1.0,0) [0|252] "" IPB_App1
 SG_ TPDiagnosisFlashFBD_HLIPB_Byte52 : 416|8@1+ (1.0,0) [0|252] "" IPB_App1
 SG_ TPDiagnosisFlashFBD_HLIPB_Byte53 : 424|8@1+ (1.0,0) [0|252] "" IPB_App1
 SG_ TPDiagnosisFlashFBD_HLIPB_Byte54 : 432|8@1+ (1.0,0) [0|252] "" IPB_App1
 SG_ TPDiagnosisFlashFBD_HLIPB_Byte55 : 440|8@1+ (1.0,0) [0|252] "" IPB_App1
 SG_ TPDiagnosisFlashFBD_HLIPB_Byte56 : 448|8@1+ (1.0,0) [0|252] "" IPB_App1
 SG_ TPDiagnosisFlashFBD_HLIPB_Byte57 : 456|8@1+ (1.0,0) [0|252] "" IPB_App1
 SG_ TPDiagnosisFlashFBD_HLIPB_Byte58 : 464|8@1+ (1.0,0) [0|252] "" IPB_App1
 SG_ TPDiagnosisFlashFBD_HLIPB_Byte59 : 472|8@1+ (1.0,0) [0|252] "" IPB_App1
 SG_ TPDiagnosisFlashFBD_HLIPB_Byte60 : 480|8@1+ (1.0,0) [0|252] "" IPB_App1
 SG_ TPDiagnosisFlashFBD_HLIPB_Byte61 : 488|8@1+ (1.0,0) [0|252] "" IPB_App1
 SG_ TPDiagnosisFlashFBD_HLIPB_Byte62 : 496|8@1+ (1.0,0) [0|252] "" IPB_App1
 SG_ TPDiagnosisFlashFBD_HLIPB_Byte63 : 504|8@1+ (1.0,0) [0|252] "" IPB_App1

BO_ 711 TPDiagnosisFlash_FBD_HM_IPB: 64 FBD_HM
 SG_ TPDiagnosisFlashFBD_HMIPB_Byte00 : 0|8@1+ (1.0,0) [0|252] "" IPB_App1
 SG_ TPDiagnosisFlashFBD_HMIPB_Byte01 : 8|8@1+ (1.0,0) [0|252] "" IPB_App1
 SG_ TPDiagnosisFlashFBD_HMIPB_Byte02 : 16|8@1+ (1.0,0) [0|252] "" IPB_App1
 SG_ TPDiagnosisFlashFBD_HMIPB_Byte03 : 24|8@1+ (1.0,0) [0|252] "" IPB_App1
 SG_ TPDiagnosisFlashFBD_HMIPB_Byte04 : 32|8@1+ (1.0,0) [0|252] "" IPB_App1
 SG_ TPDiagnosisFlashFBD_HMIPB_Byte05 : 40|8@1+ (1.0,0) [0|252] "" IPB_App1
 SG_ TPDiagnosisFlashFBD_HMIPB_Byte06 : 48|8@1+ (1.0,0) [0|252] "" IPB_App1
 SG_ TPDiagnosisFlashFBD_HMIPB_Byte07 : 56|8@1+ (1.0,0) [0|252] "" IPB_App1
 SG_ TPDiagnosisFlashFBD_HMIPB_Byte08 : 64|8@1+ (1.0,0) [0|252] "" IPB_App1
 SG_ TPDiagnosisFlashFBD_HMIPB_Byte09 : 72|8@1+ (1.0,0) [0|252] "" IPB_App1
 SG_ TPDiagnosisFlashFBD_HMIPB_Byte10 : 80|8@1+ (1.0,0) [0|252] "" IPB_App1
 SG_ TPDiagnosisFlashFBD_HMIPB_Byte11 : 88|8@1+ (1.0,0) [0|252] "" IPB_App1
 SG_ TPDiagnosisFlashFBD_HMIPB_Byte12 : 96|8@1+ (1.0,0) [0|252] "" IPB_App1
 SG_ TPDiagnosisFlashFBD_HMIPB_Byte13 : 104|8@1+ (1.0,0) [0|252] "" IPB_App1
 SG_ TPDiagnosisFlashFBD_HMIPB_Byte14 : 112|8@1+ (1.0,0) [0|252] "" IPB_App1
 SG_ TPDiagnosisFlashFBD_HMIPB_Byte15 : 120|8@1+ (1.0,0) [0|252] "" IPB_App1
 SG_ TPDiagnosisFlashFBD_HMIPB_Byte16 : 128|8@1+ (1.0,0) [0|252] "" IPB_App1
 SG_ TPDiagnosisFlashFBD_HMIPB_Byte17 : 136|8@1+ (1.0,0) [0|252] "" IPB_App1
 SG_ TPDiagnosisFlashFBD_HMIPB_Byte18 : 144|8@1+ (1.0,0) [0|252] "" IPB_App1
 SG_ TPDiagnosisFlashFBD_HMIPB_Byte19 : 152|8@1+ (1.0,0) [0|252] "" IPB_App1
 SG_ TPDiagnosisFlashFBD_HMIPB_Byte20 : 160|8@1+ (1.0,0) [0|252] "" IPB_App1
 SG_ TPDiagnosisFlashFBD_HMIPB_Byte21 : 168|8@1+ (1.0,0) [0|252] "" IPB_App1
 SG_ TPDiagnosisFlashFBD_HMIPB_Byte22 : 176|8@1+ (1.0,0) [0|252] "" IPB_App1
 SG_ TPDiagnosisFlashFBD_HMIPB_Byte23 : 184|8@1+ (1.0,0) [0|252] "" IPB_App1
 SG_ TPDiagnosisFlashFBD_HMIPB_Byte24 : 192|8@1+ (1.0,0) [0|252] "" IPB_App1
 SG_ TPDiagnosisFlashFBD_HMIPB_Byte25 : 200|8@1+ (1.0,0) [0|252] "" IPB_App1
 SG_ TPDiagnosisFlashFBD_HMIPB_Byte26 : 208|8@1+ (1.0,0) [0|252] "" IPB_App1
 SG_ TPDiagnosisFlashFBD_HMIPB_Byte27 : 216|8@1+ (1.0,0) [0|252] "" IPB_App1
 SG_ TPDiagnosisFlashFBD_HMIPB_Byte28 : 224|8@1+ (1.0,0) [0|252] "" IPB_App1
 SG_ TPDiagnosisFlashFBD_HMIPB_Byte29 : 232|8@1+ (1.0,0) [0|252] "" IPB_App1
 SG_ TPDiagnosisFlashFBD_HMIPB_Byte30 : 240|8@1+ (1.0,0) [0|252] "" IPB_App1
 SG_ TPDiagnosisFlashFBD_HMIPB_Byte31 : 248|8@1+ (1.0,0) [0|252] "" IPB_App1
 SG_ TPDiagnosisFlashFBD_HMIPB_Byte32 : 256|8@1+ (1.0,0) [0|252] "" IPB_App1
 SG_ TPDiagnosisFlashFBD_HMIPB_Byte33 : 264|8@1+ (1.0,0) [0|252] "" IPB_App1
 SG_ TPDiagnosisFlashFBD_HMIPB_Byte34 : 272|8@1+ (1.0,0) [0|252] "" IPB_App1
 SG_ TPDiagnosisFlashFBD_HMIPB_Byte35 : 280|8@1+ (1.0,0) [0|252] "" IPB_App1
 SG_ TPDiagnosisFlashFBD_HMIPB_Byte36 : 288|8@1+ (1.0,0) [0|252] "" IPB_App1
 SG_ TPDiagnosisFlashFBD_HMIPB_Byte37 : 296|8@1+ (1.0,0) [0|252] "" IPB_App1
 SG_ TPDiagnosisFlashFBD_HMIPB_Byte38 : 304|8@1+ (1.0,0) [0|252] "" IPB_App1
 SG_ TPDiagnosisFlashFBD_HMIPB_Byte39 : 312|8@1+ (1.0,0) [0|252] "" IPB_App1
 SG_ TPDiagnosisFlashFBD_HMIPB_Byte40 : 320|8@1+ (1.0,0) [0|252] "" IPB_App1
 SG_ TPDiagnosisFlashFBD_HMIPB_Byte41 : 328|8@1+ (1.0,0) [0|252] "" IPB_App1
 SG_ TPDiagnosisFlashFBD_HMIPB_Byte42 : 336|8@1+ (1.0,0) [0|252] "" IPB_App1
 SG_ TPDiagnosisFlashFBD_HMIPB_Byte43 : 344|8@1+ (1.0,0) [0|252] "" IPB_App1
 SG_ TPDiagnosisFlashFBD_HMIPB_Byte44 : 352|8@1+ (1.0,0) [0|252] "" IPB_App1
 SG_ TPDiagnosisFlashFBD_HMIPB_Byte45 : 360|8@1+ (1.0,0) [0|252] "" IPB_App1
 SG_ TPDiagnosisFlashFBD_HMIPB_Byte46 : 368|8@1+ (1.0,0) [0|252] "" IPB_App1
 SG_ TPDiagnosisFlashFBD_HMIPB_Byte47 : 376|8@1+ (1.0,0) [0|252] "" IPB_App1
 SG_ TPDiagnosisFlashFBD_HMIPB_Byte48 : 384|8@1+ (1.0,0) [0|252] "" IPB_App1
 SG_ TPDiagnosisFlashFBD_HMIPB_Byte49 : 392|8@1+ (1.0,0) [0|252] "" IPB_App1
 SG_ TPDiagnosisFlashFBD_HMIPB_Byte50 : 400|8@1+ (1.0,0) [0|252] "" IPB_App1
 SG_ TPDiagnosisFlashFBD_HMIPB_Byte51 : 408|8@1+ (1.0,0) [0|252] "" IPB_App1
 SG_ TPDiagnosisFlashFBD_HMIPB_Byte52 : 416|8@1+ (1.0,0) [0|252] "" IPB_App1
 SG_ TPDiagnosisFlashFBD_HMIPB_Byte53 : 424|8@1+ (1.0,0) [0|252] "" IPB_App1
 SG_ TPDiagnosisFlashFBD_HMIPB_Byte54 : 432|8@1+ (1.0,0) [0|252] "" IPB_App1
 SG_ TPDiagnosisFlashFBD_HMIPB_Byte55 : 440|8@1+ (1.0,0) [0|252] "" IPB_App1
 SG_ TPDiagnosisFlashFBD_HMIPB_Byte56 : 448|8@1+ (1.0,0) [0|252] "" IPB_App1
 SG_ TPDiagnosisFlashFBD_HMIPB_Byte57 : 456|8@1+ (1.0,0) [0|252] "" IPB_App1
 SG_ TPDiagnosisFlashFBD_HMIPB_Byte58 : 464|8@1+ (1.0,0) [0|252] "" IPB_App1
 SG_ TPDiagnosisFlashFBD_HMIPB_Byte59 : 472|8@1+ (1.0,0) [0|252] "" IPB_App1
 SG_ TPDiagnosisFlashFBD_HMIPB_Byte60 : 480|8@1+ (1.0,0) [0|252] "" IPB_App1
 SG_ TPDiagnosisFlashFBD_HMIPB_Byte61 : 488|8@1+ (1.0,0) [0|252] "" IPB_App1
 SG_ TPDiagnosisFlashFBD_HMIPB_Byte62 : 496|8@1+ (1.0,0) [0|252] "" IPB_App1
 SG_ TPDiagnosisFlashFBD_HMIPB_Byte63 : 504|8@1+ (1.0,0) [0|252] "" IPB_App1

BO_ 717 TPDiagnosisFlash_FBD_HR_IPB: 64 FBD_HR
 SG_ TPDiagnosisFlashFBD_HRIPB_Byte00 : 0|8@1+ (1.0,0) [0|252] "" IPB_App1
 SG_ TPDiagnosisFlashFBD_HRIPB_Byte01 : 8|8@1+ (1.0,0) [0|252] "" IPB_App1
 SG_ TPDiagnosisFlashFBD_HRIPB_Byte02 : 16|8@1+ (1.0,0) [0|252] "" IPB_App1
 SG_ TPDiagnosisFlashFBD_HRIPB_Byte03 : 24|8@1+ (1.0,0) [0|252] "" IPB_App1
 SG_ TPDiagnosisFlashFBD_HRIPB_Byte04 : 32|8@1+ (1.0,0) [0|252] "" IPB_App1
 SG_ TPDiagnosisFlashFBD_HRIPB_Byte05 : 40|8@1+ (1.0,0) [0|252] "" IPB_App1
 SG_ TPDiagnosisFlashFBD_HRIPB_Byte06 : 48|8@1+ (1.0,0) [0|252] "" IPB_App1
 SG_ TPDiagnosisFlashFBD_HRIPB_Byte07 : 56|8@1+ (1.0,0) [0|252] "" IPB_App1
 SG_ TPDiagnosisFlashFBD_HRIPB_Byte08 : 64|8@1+ (1.0,0) [0|252] "" IPB_App1
 SG_ TPDiagnosisFlashFBD_HRIPB_Byte09 : 72|8@1+ (1.0,0) [0|252] "" IPB_App1
 SG_ TPDiagnosisFlashFBD_HRIPB_Byte10 : 80|8@1+ (1.0,0) [0|252] "" IPB_App1
 SG_ TPDiagnosisFlashFBD_HRIPB_Byte11 : 88|8@1+ (1.0,0) [0|252] "" IPB_App1
 SG_ TPDiagnosisFlashFBD_HRIPB_Byte12 : 96|8@1+ (1.0,0) [0|252] "" IPB_App1
 SG_ TPDiagnosisFlashFBD_HRIPB_Byte13 : 104|8@1+ (1.0,0) [0|252] "" IPB_App1
 SG_ TPDiagnosisFlashFBD_HRIPB_Byte14 : 112|8@1+ (1.0,0) [0|252] "" IPB_App1
 SG_ TPDiagnosisFlashFBD_HRIPB_Byte15 : 120|8@1+ (1.0,0) [0|252] "" IPB_App1
 SG_ TPDiagnosisFlashFBD_HRIPB_Byte16 : 128|8@1+ (1.0,0) [0|252] "" IPB_App1
 SG_ TPDiagnosisFlashFBD_HRIPB_Byte17 : 136|8@1+ (1.0,0) [0|252] "" IPB_App1
 SG_ TPDiagnosisFlashFBD_HRIPB_Byte18 : 144|8@1+ (1.0,0) [0|252] "" IPB_App1
 SG_ TPDiagnosisFlashFBD_HRIPB_Byte19 : 152|8@1+ (1.0,0) [0|252] "" IPB_App1
 SG_ TPDiagnosisFlashFBD_HRIPB_Byte20 : 160|8@1+ (1.0,0) [0|252] "" IPB_App1
 SG_ TPDiagnosisFlashFBD_HRIPB_Byte21 : 168|8@1+ (1.0,0) [0|252] "" IPB_App1
 SG_ TPDiagnosisFlashFBD_HRIPB_Byte22 : 176|8@1+ (1.0,0) [0|252] "" IPB_App1
 SG_ TPDiagnosisFlashFBD_HRIPB_Byte23 : 184|8@1+ (1.0,0) [0|252] "" IPB_App1
 SG_ TPDiagnosisFlashFBD_HRIPB_Byte24 : 192|8@1+ (1.0,0) [0|252] "" IPB_App1
 SG_ TPDiagnosisFlashFBD_HRIPB_Byte25 : 200|8@1+ (1.0,0) [0|252] "" IPB_App1
 SG_ TPDiagnosisFlashFBD_HRIPB_Byte26 : 208|8@1+ (1.0,0) [0|252] "" IPB_App1
 SG_ TPDiagnosisFlashFBD_HRIPB_Byte27 : 216|8@1+ (1.0,0) [0|252] "" IPB_App1
 SG_ TPDiagnosisFlashFBD_HRIPB_Byte28 : 224|8@1+ (1.0,0) [0|252] "" IPB_App1
 SG_ TPDiagnosisFlashFBD_HRIPB_Byte29 : 232|8@1+ (1.0,0) [0|252] "" IPB_App1
 SG_ TPDiagnosisFlashFBD_HRIPB_Byte30 : 240|8@1+ (1.0,0) [0|252] "" IPB_App1
 SG_ TPDiagnosisFlashFBD_HRIPB_Byte31 : 248|8@1+ (1.0,0) [0|252] "" IPB_App1
 SG_ TPDiagnosisFlashFBD_HRIPB_Byte32 : 256|8@1+ (1.0,0) [0|252] "" IPB_App1
 SG_ TPDiagnosisFlashFBD_HRIPB_Byte33 : 264|8@1+ (1.0,0) [0|252] "" IPB_App1
 SG_ TPDiagnosisFlashFBD_HRIPB_Byte34 : 272|8@1+ (1.0,0) [0|252] "" IPB_App1
 SG_ TPDiagnosisFlashFBD_HRIPB_Byte35 : 280|8@1+ (1.0,0) [0|252] "" IPB_App1
 SG_ TPDiagnosisFlashFBD_HRIPB_Byte36 : 288|8@1+ (1.0,0) [0|252] "" IPB_App1
 SG_ TPDiagnosisFlashFBD_HRIPB_Byte37 : 296|8@1+ (1.0,0) [0|252] "" IPB_App1
 SG_ TPDiagnosisFlashFBD_HRIPB_Byte38 : 304|8@1+ (1.0,0) [0|252] "" IPB_App1
 SG_ TPDiagnosisFlashFBD_HRIPB_Byte39 : 312|8@1+ (1.0,0) [0|252] "" IPB_App1
 SG_ TPDiagnosisFlashFBD_HRIPB_Byte40 : 320|8@1+ (1.0,0) [0|252] "" IPB_App1
 SG_ TPDiagnosisFlashFBD_HRIPB_Byte41 : 328|8@1+ (1.0,0) [0|252] "" IPB_App1
 SG_ TPDiagnosisFlashFBD_HRIPB_Byte42 : 336|8@1+ (1.0,0) [0|252] "" IPB_App1
 SG_ TPDiagnosisFlashFBD_HRIPB_Byte43 : 344|8@1+ (1.0,0) [0|252] "" IPB_App1
 SG_ TPDiagnosisFlashFBD_HRIPB_Byte44 : 352|8@1+ (1.0,0) [0|252] "" IPB_App1
 SG_ TPDiagnosisFlashFBD_HRIPB_Byte45 : 360|8@1+ (1.0,0) [0|252] "" IPB_App1
 SG_ TPDiagnosisFlashFBD_HRIPB_Byte46 : 368|8@1+ (1.0,0) [0|252] "" IPB_App1
 SG_ TPDiagnosisFlashFBD_HRIPB_Byte47 : 376|8@1+ (1.0,0) [0|252] "" IPB_App1
 SG_ TPDiagnosisFlashFBD_HRIPB_Byte48 : 384|8@1+ (1.0,0) [0|252] "" IPB_App1
 SG_ TPDiagnosisFlashFBD_HRIPB_Byte49 : 392|8@1+ (1.0,0) [0|252] "" IPB_App1
 SG_ TPDiagnosisFlashFBD_HRIPB_Byte50 : 400|8@1+ (1.0,0) [0|252] "" IPB_App1
 SG_ TPDiagnosisFlashFBD_HRIPB_Byte51 : 408|8@1+ (1.0,0) [0|252] "" IPB_App1
 SG_ TPDiagnosisFlashFBD_HRIPB_Byte52 : 416|8@1+ (1.0,0) [0|252] "" IPB_App1
 SG_ TPDiagnosisFlashFBD_HRIPB_Byte53 : 424|8@1+ (1.0,0) [0|252] "" IPB_App1
 SG_ TPDiagnosisFlashFBD_HRIPB_Byte54 : 432|8@1+ (1.0,0) [0|252] "" IPB_App1
 SG_ TPDiagnosisFlashFBD_HRIPB_Byte55 : 440|8@1+ (1.0,0) [0|252] "" IPB_App1
 SG_ TPDiagnosisFlashFBD_HRIPB_Byte56 : 448|8@1+ (1.0,0) [0|252] "" IPB_App1
 SG_ TPDiagnosisFlashFBD_HRIPB_Byte57 : 456|8@1+ (1.0,0) [0|252] "" IPB_App1
 SG_ TPDiagnosisFlashFBD_HRIPB_Byte58 : 464|8@1+ (1.0,0) [0|252] "" IPB_App1
 SG_ TPDiagnosisFlashFBD_HRIPB_Byte59 : 472|8@1+ (1.0,0) [0|252] "" IPB_App1
 SG_ TPDiagnosisFlashFBD_HRIPB_Byte60 : 480|8@1+ (1.0,0) [0|252] "" IPB_App1
 SG_ TPDiagnosisFlashFBD_HRIPB_Byte61 : 488|8@1+ (1.0,0) [0|252] "" IPB_App1
 SG_ TPDiagnosisFlashFBD_HRIPB_Byte62 : 496|8@1+ (1.0,0) [0|252] "" IPB_App1
 SG_ TPDiagnosisFlashFBD_HRIPB_Byte63 : 504|8@1+ (1.0,0) [0|252] "" IPB_App1

BO_ 712 TPDiagnosisFlash_FBD_Miko_IPB: 64 FBD_Miko
 SG_ TPDiagnosisFlashFBD_MikoIPB_Byte : 0|8@1+ (1.0,0) [0|252] "" IPB_App1
 SG_ TPDiagnosisFlashFBD_MikoIPB_By_2 : 8|8@1+ (1.0,0) [0|252] "" IPB_App1
 SG_ TPDiagnosisFlashFBD_MikoIPB_By_3 : 16|8@1+ (1.0,0) [0|252] "" IPB_App1
 SG_ TPDiagnosisFlashFBD_MikoIPB_By_4 : 24|8@1+ (1.0,0) [0|252] "" IPB_App1
 SG_ TPDiagnosisFlashFBD_MikoIPB_By_5 : 32|8@1+ (1.0,0) [0|252] "" IPB_App1
 SG_ TPDiagnosisFlashFBD_MikoIPB_By_6 : 40|8@1+ (1.0,0) [0|252] "" IPB_App1
 SG_ TPDiagnosisFlashFBD_MikoIPB_By_7 : 48|8@1+ (1.0,0) [0|252] "" IPB_App1
 SG_ TPDiagnosisFlashFBD_MikoIPB_By_8 : 56|8@1+ (1.0,0) [0|252] "" IPB_App1
 SG_ TPDiagnosisFlashFBD_MikoIPB_By_9 : 64|8@1+ (1.0,0) [0|252] "" IPB_App1
 SG_ TPDiagnosisFlashFBD_MikoIPB_B_10 : 72|8@1+ (1.0,0) [0|252] "" IPB_App1
 SG_ TPDiagnosisFlashFBD_MikoIPB_B_11 : 80|8@1+ (1.0,0) [0|252] "" IPB_App1
 SG_ TPDiagnosisFlashFBD_MikoIPB_B_12 : 88|8@1+ (1.0,0) [0|252] "" IPB_App1
 SG_ TPDiagnosisFlashFBD_MikoIPB_B_13 : 96|8@1+ (1.0,0) [0|252] "" IPB_App1
 SG_ TPDiagnosisFlashFBD_MikoIPB_B_14 : 104|8@1+ (1.0,0) [0|252] "" IPB_App1
 SG_ TPDiagnosisFlashFBD_MikoIPB_B_15 : 112|8@1+ (1.0,0) [0|252] "" IPB_App1
 SG_ TPDiagnosisFlashFBD_MikoIPB_B_16 : 120|8@1+ (1.0,0) [0|252] "" IPB_App1
 SG_ TPDiagnosisFlashFBD_MikoIPB_B_17 : 128|8@1+ (1.0,0) [0|252] "" IPB_App1
 SG_ TPDiagnosisFlashFBD_MikoIPB_B_18 : 136|8@1+ (1.0,0) [0|252] "" IPB_App1
 SG_ TPDiagnosisFlashFBD_MikoIPB_B_19 : 144|8@1+ (1.0,0) [0|252] "" IPB_App1
 SG_ TPDiagnosisFlashFBD_MikoIPB_B_20 : 152|8@1+ (1.0,0) [0|252] "" IPB_App1
 SG_ TPDiagnosisFlashFBD_MikoIPB_B_21 : 160|8@1+ (1.0,0) [0|252] "" IPB_App1
 SG_ TPDiagnosisFlashFBD_MikoIPB_B_22 : 168|8@1+ (1.0,0) [0|252] "" IPB_App1
 SG_ TPDiagnosisFlashFBD_MikoIPB_B_23 : 176|8@1+ (1.0,0) [0|252] "" IPB_App1
 SG_ TPDiagnosisFlashFBD_MikoIPB_B_24 : 184|8@1+ (1.0,0) [0|252] "" IPB_App1
 SG_ TPDiagnosisFlashFBD_MikoIPB_B_25 : 192|8@1+ (1.0,0) [0|252] "" IPB_App1
 SG_ TPDiagnosisFlashFBD_MikoIPB_B_26 : 200|8@1+ (1.0,0) [0|252] "" IPB_App1
 SG_ TPDiagnosisFlashFBD_MikoIPB_B_27 : 208|8@1+ (1.0,0) [0|252] "" IPB_App1
 SG_ TPDiagnosisFlashFBD_MikoIPB_B_28 : 216|8@1+ (1.0,0) [0|252] "" IPB_App1
 SG_ TPDiagnosisFlashFBD_MikoIPB_B_29 : 224|8@1+ (1.0,0) [0|252] "" IPB_App1
 SG_ TPDiagnosisFlashFBD_MikoIPB_B_30 : 232|8@1+ (1.0,0) [0|252] "" IPB_App1
 SG_ TPDiagnosisFlashFBD_MikoIPB_B_31 : 240|8@1+ (1.0,0) [0|252] "" IPB_App1
 SG_ TPDiagnosisFlashFBD_MikoIPB_B_32 : 248|8@1+ (1.0,0) [0|252] "" IPB_App1
 SG_ TPDiagnosisFlashFBD_MikoIPB_B_33 : 256|8@1+ (1.0,0) [0|252] "" IPB_App1
 SG_ TPDiagnosisFlashFBD_MikoIPB_B_34 : 264|8@1+ (1.0,0) [0|252] "" IPB_App1
 SG_ TPDiagnosisFlashFBD_MikoIPB_B_35 : 272|8@1+ (1.0,0) [0|252] "" IPB_App1
 SG_ TPDiagnosisFlashFBD_MikoIPB_B_36 : 280|8@1+ (1.0,0) [0|252] "" IPB_App1
 SG_ TPDiagnosisFlashFBD_MikoIPB_B_37 : 288|8@1+ (1.0,0) [0|252] "" IPB_App1
 SG_ TPDiagnosisFlashFBD_MikoIPB_B_38 : 296|8@1+ (1.0,0) [0|252] "" IPB_App1
 SG_ TPDiagnosisFlashFBD_MikoIPB_B_39 : 304|8@1+ (1.0,0) [0|252] "" IPB_App1
 SG_ TPDiagnosisFlashFBD_MikoIPB_B_40 : 312|8@1+ (1.0,0) [0|252] "" IPB_App1
 SG_ TPDiagnosisFlashFBD_MikoIPB_B_41 : 320|8@1+ (1.0,0) [0|252] "" IPB_App1
 SG_ TPDiagnosisFlashFBD_MikoIPB_B_42 : 328|8@1+ (1.0,0) [0|252] "" IPB_App1
 SG_ TPDiagnosisFlashFBD_MikoIPB_B_43 : 336|8@1+ (1.0,0) [0|252] "" IPB_App1
 SG_ TPDiagnosisFlashFBD_MikoIPB_B_44 : 344|8@1+ (1.0,0) [0|252] "" IPB_App1
 SG_ TPDiagnosisFlashFBD_MikoIPB_B_45 : 352|8@1+ (1.0,0) [0|252] "" IPB_App1
 SG_ TPDiagnosisFlashFBD_MikoIPB_B_46 : 360|8@1+ (1.0,0) [0|252] "" IPB_App1
 SG_ TPDiagnosisFlashFBD_MikoIPB_B_47 : 368|8@1+ (1.0,0) [0|252] "" IPB_App1
 SG_ TPDiagnosisFlashFBD_MikoIPB_B_48 : 376|8@1+ (1.0,0) [0|252] "" IPB_App1
 SG_ TPDiagnosisFlashFBD_MikoIPB_B_49 : 384|8@1+ (1.0,0) [0|252] "" IPB_App1
 SG_ TPDiagnosisFlashFBD_MikoIPB_B_50 : 392|8@1+ (1.0,0) [0|252] "" IPB_App1
 SG_ TPDiagnosisFlashFBD_MikoIPB_B_51 : 400|8@1+ (1.0,0) [0|252] "" IPB_App1
 SG_ TPDiagnosisFlashFBD_MikoIPB_B_52 : 408|8@1+ (1.0,0) [0|252] "" IPB_App1
 SG_ TPDiagnosisFlashFBD_MikoIPB_B_53 : 416|8@1+ (1.0,0) [0|252] "" IPB_App1
 SG_ TPDiagnosisFlashFBD_MikoIPB_B_54 : 424|8@1+ (1.0,0) [0|252] "" IPB_App1
 SG_ TPDiagnosisFlashFBD_MikoIPB_B_55 : 432|8@1+ (1.0,0) [0|252] "" IPB_App1
 SG_ TPDiagnosisFlashFBD_MikoIPB_B_56 : 440|8@1+ (1.0,0) [0|252] "" IPB_App1
 SG_ TPDiagnosisFlashFBD_MikoIPB_B_57 : 448|8@1+ (1.0,0) [0|252] "" IPB_App1
 SG_ TPDiagnosisFlashFBD_MikoIPB_B_58 : 456|8@1+ (1.0,0) [0|252] "" IPB_App1
 SG_ TPDiagnosisFlashFBD_MikoIPB_B_59 : 464|8@1+ (1.0,0) [0|252] "" IPB_App1
 SG_ TPDiagnosisFlashFBD_MikoIPB_B_60 : 472|8@1+ (1.0,0) [0|252] "" IPB_App1
 SG_ TPDiagnosisFlashFBD_MikoIPB_B_61 : 480|8@1+ (1.0,0) [0|252] "" IPB_App1
 SG_ TPDiagnosisFlashFBD_MikoIPB_B_62 : 488|8@1+ (1.0,0) [0|252] "" IPB_App1
 SG_ TPDiagnosisFlashFBD_MikoIPB_B_63 : 496|8@1+ (1.0,0) [0|252] "" IPB_App1
 SG_ TPDiagnosisFlashFBD_MikoIPB_B_64 : 504|8@1+ (1.0,0) [0|252] "" IPB_App1

BO_ 870 TPDiagnosisFlash_FBD_MM_IPB: 64 FBD_MM
 SG_ TPDiagnosisFlashFBD_MMIPB_Byte00 : 0|8@1+ (1.0,0) [0|252] "" IPB_App1
 SG_ TPDiagnosisFlashFBD_MMIPB_Byte01 : 8|8@1+ (1.0,0) [0|252] "" IPB_App1
 SG_ TPDiagnosisFlashFBD_MMIPB_Byte02 : 16|8@1+ (1.0,0) [0|252] "" IPB_App1
 SG_ TPDiagnosisFlashFBD_MMIPB_Byte03 : 24|8@1+ (1.0,0) [0|252] "" IPB_App1
 SG_ TPDiagnosisFlashFBD_MMIPB_Byte04 : 32|8@1+ (1.0,0) [0|252] "" IPB_App1
 SG_ TPDiagnosisFlashFBD_MMIPB_Byte05 : 40|8@1+ (1.0,0) [0|252] "" IPB_App1
 SG_ TPDiagnosisFlashFBD_MMIPB_Byte06 : 48|8@1+ (1.0,0) [0|252] "" IPB_App1
 SG_ TPDiagnosisFlashFBD_MMIPB_Byte07 : 56|8@1+ (1.0,0) [0|252] "" IPB_App1
 SG_ TPDiagnosisFlashFBD_MMIPB_Byte08 : 64|8@1+ (1.0,0) [0|252] "" IPB_App1
 SG_ TPDiagnosisFlashFBD_MMIPB_Byte09 : 72|8@1+ (1.0,0) [0|252] "" IPB_App1
 SG_ TPDiagnosisFlashFBD_MMIPB_Byte10 : 80|8@1+ (1.0,0) [0|252] "" IPB_App1
 SG_ TPDiagnosisFlashFBD_MMIPB_Byte11 : 88|8@1+ (1.0,0) [0|252] "" IPB_App1
 SG_ TPDiagnosisFlashFBD_MMIPB_Byte12 : 96|8@1+ (1.0,0) [0|252] "" IPB_App1
 SG_ TPDiagnosisFlashFBD_MMIPB_Byte13 : 104|8@1+ (1.0,0) [0|252] "" IPB_App1
 SG_ TPDiagnosisFlashFBD_MMIPB_Byte14 : 112|8@1+ (1.0,0) [0|252] "" IPB_App1
 SG_ TPDiagnosisFlashFBD_MMIPB_Byte15 : 120|8@1+ (1.0,0) [0|252] "" IPB_App1
 SG_ TPDiagnosisFlashFBD_MMIPB_Byte16 : 128|8@1+ (1.0,0) [0|252] "" IPB_App1
 SG_ TPDiagnosisFlashFBD_MMIPB_Byte17 : 136|8@1+ (1.0,0) [0|252] "" IPB_App1
 SG_ TPDiagnosisFlashFBD_MMIPB_Byte18 : 144|8@1+ (1.0,0) [0|252] "" IPB_App1
 SG_ TPDiagnosisFlashFBD_MMIPB_Byte19 : 152|8@1+ (1.0,0) [0|252] "" IPB_App1
 SG_ TPDiagnosisFlashFBD_MMIPB_Byte20 : 160|8@1+ (1.0,0) [0|252] "" IPB_App1
 SG_ TPDiagnosisFlashFBD_MMIPB_Byte21 : 168|8@1+ (1.0,0) [0|252] "" IPB_App1
 SG_ TPDiagnosisFlashFBD_MMIPB_Byte22 : 176|8@1+ (1.0,0) [0|252] "" IPB_App1
 SG_ TPDiagnosisFlashFBD_MMIPB_Byte23 : 184|8@1+ (1.0,0) [0|252] "" IPB_App1
 SG_ TPDiagnosisFlashFBD_MMIPB_Byte24 : 192|8@1+ (1.0,0) [0|252] "" IPB_App1
 SG_ TPDiagnosisFlashFBD_MMIPB_Byte25 : 200|8@1+ (1.0,0) [0|252] "" IPB_App1
 SG_ TPDiagnosisFlashFBD_MMIPB_Byte26 : 208|8@1+ (1.0,0) [0|252] "" IPB_App1
 SG_ TPDiagnosisFlashFBD_MMIPB_Byte27 : 216|8@1+ (1.0,0) [0|252] "" IPB_App1
 SG_ TPDiagnosisFlashFBD_MMIPB_Byte28 : 224|8@1+ (1.0,0) [0|252] "" IPB_App1
 SG_ TPDiagnosisFlashFBD_MMIPB_Byte29 : 232|8@1+ (1.0,0) [0|252] "" IPB_App1
 SG_ TPDiagnosisFlashFBD_MMIPB_Byte30 : 240|8@1+ (1.0,0) [0|252] "" IPB_App1
 SG_ TPDiagnosisFlashFBD_MMIPB_Byte31 : 248|8@1+ (1.0,0) [0|252] "" IPB_App1
 SG_ TPDiagnosisFlashFBD_MMIPB_Byte32 : 256|8@1+ (1.0,0) [0|252] "" IPB_App1
 SG_ TPDiagnosisFlashFBD_MMIPB_Byte33 : 264|8@1+ (1.0,0) [0|252] "" IPB_App1
 SG_ TPDiagnosisFlashFBD_MMIPB_Byte34 : 272|8@1+ (1.0,0) [0|252] "" IPB_App1
 SG_ TPDiagnosisFlashFBD_MMIPB_Byte35 : 280|8@1+ (1.0,0) [0|252] "" IPB_App1
 SG_ TPDiagnosisFlashFBD_MMIPB_Byte36 : 288|8@1+ (1.0,0) [0|252] "" IPB_App1
 SG_ TPDiagnosisFlashFBD_MMIPB_Byte37 : 296|8@1+ (1.0,0) [0|252] "" IPB_App1
 SG_ TPDiagnosisFlashFBD_MMIPB_Byte38 : 304|8@1+ (1.0,0) [0|252] "" IPB_App1
 SG_ TPDiagnosisFlashFBD_MMIPB_Byte39 : 312|8@1+ (1.0,0) [0|252] "" IPB_App1
 SG_ TPDiagnosisFlashFBD_MMIPB_Byte40 : 320|8@1+ (1.0,0) [0|252] "" IPB_App1
 SG_ TPDiagnosisFlashFBD_MMIPB_Byte41 : 328|8@1+ (1.0,0) [0|252] "" IPB_App1
 SG_ TPDiagnosisFlashFBD_MMIPB_Byte42 : 336|8@1+ (1.0,0) [0|252] "" IPB_App1
 SG_ TPDiagnosisFlashFBD_MMIPB_Byte43 : 344|8@1+ (1.0,0) [0|252] "" IPB_App1
 SG_ TPDiagnosisFlashFBD_MMIPB_Byte44 : 352|8@1+ (1.0,0) [0|252] "" IPB_App1
 SG_ TPDiagnosisFlashFBD_MMIPB_Byte45 : 360|8@1+ (1.0,0) [0|252] "" IPB_App1
 SG_ TPDiagnosisFlashFBD_MMIPB_Byte46 : 368|8@1+ (1.0,0) [0|252] "" IPB_App1
 SG_ TPDiagnosisFlashFBD_MMIPB_Byte47 : 376|8@1+ (1.0,0) [0|252] "" IPB_App1
 SG_ TPDiagnosisFlashFBD_MMIPB_Byte48 : 384|8@1+ (1.0,0) [0|252] "" IPB_App1
 SG_ TPDiagnosisFlashFBD_MMIPB_Byte49 : 392|8@1+ (1.0,0) [0|252] "" IPB_App1
 SG_ TPDiagnosisFlashFBD_MMIPB_Byte50 : 400|8@1+ (1.0,0) [0|252] "" IPB_App1
 SG_ TPDiagnosisFlashFBD_MMIPB_Byte51 : 408|8@1+ (1.0,0) [0|252] "" IPB_App1
 SG_ TPDiagnosisFlashFBD_MMIPB_Byte52 : 416|8@1+ (1.0,0) [0|252] "" IPB_App1
 SG_ TPDiagnosisFlashFBD_MMIPB_Byte53 : 424|8@1+ (1.0,0) [0|252] "" IPB_App1
 SG_ TPDiagnosisFlashFBD_MMIPB_Byte54 : 432|8@1+ (1.0,0) [0|252] "" IPB_App1
 SG_ TPDiagnosisFlashFBD_MMIPB_Byte55 : 440|8@1+ (1.0,0) [0|252] "" IPB_App1
 SG_ TPDiagnosisFlashFBD_MMIPB_Byte56 : 448|8@1+ (1.0,0) [0|252] "" IPB_App1
 SG_ TPDiagnosisFlashFBD_MMIPB_Byte57 : 456|8@1+ (1.0,0) [0|252] "" IPB_App1
 SG_ TPDiagnosisFlashFBD_MMIPB_Byte58 : 464|8@1+ (1.0,0) [0|252] "" IPB_App1
 SG_ TPDiagnosisFlashFBD_MMIPB_Byte59 : 472|8@1+ (1.0,0) [0|252] "" IPB_App1
 SG_ TPDiagnosisFlashFBD_MMIPB_Byte60 : 480|8@1+ (1.0,0) [0|252] "" IPB_App1
 SG_ TPDiagnosisFlashFBD_MMIPB_Byte61 : 488|8@1+ (1.0,0) [0|252] "" IPB_App1
 SG_ TPDiagnosisFlashFBD_MMIPB_Byte62 : 496|8@1+ (1.0,0) [0|252] "" IPB_App1
 SG_ TPDiagnosisFlashFBD_MMIPB_Byte63 : 504|8@1+ (1.0,0) [0|252] "" IPB_App1

BO_ 713 TPDiagnosisFlash_FBD_Trunk_IPB: 64 FBD_Trunk
 SG_ TPDiagnosisFlashFBD_TrunkIPB_Byt : 0|8@1+ (1.0,0) [0|252] "" IPB_App1
 SG_ TPDiagnosisFlashFBD_TrunkIPB_B_2 : 8|8@1+ (1.0,0) [0|252] "" IPB_App1
 SG_ TPDiagnosisFlashFBD_TrunkIPB_B_3 : 16|8@1+ (1.0,0) [0|252] "" IPB_App1
 SG_ TPDiagnosisFlashFBD_TrunkIPB_B_4 : 24|8@1+ (1.0,0) [0|252] "" IPB_App1
 SG_ TPDiagnosisFlashFBD_TrunkIPB_B_5 : 32|8@1+ (1.0,0) [0|252] "" IPB_App1
 SG_ TPDiagnosisFlashFBD_TrunkIPB_B_6 : 40|8@1+ (1.0,0) [0|252] "" IPB_App1
 SG_ TPDiagnosisFlashFBD_TrunkIPB_B_7 : 48|8@1+ (1.0,0) [0|252] "" IPB_App1
 SG_ TPDiagnosisFlashFBD_TrunkIPB_B_8 : 56|8@1+ (1.0,0) [0|252] "" IPB_App1
 SG_ TPDiagnosisFlashFBD_TrunkIPB_B_9 : 64|8@1+ (1.0,0) [0|252] "" IPB_App1
 SG_ TPDiagnosisFlashFBD_TrunkIPB__10 : 72|8@1+ (1.0,0) [0|252] "" IPB_App1
 SG_ TPDiagnosisFlashFBD_TrunkIPB__11 : 80|8@1+ (1.0,0) [0|252] "" IPB_App1
 SG_ TPDiagnosisFlashFBD_TrunkIPB__12 : 88|8@1+ (1.0,0) [0|252] "" IPB_App1
 SG_ TPDiagnosisFlashFBD_TrunkIPB__13 : 96|8@1+ (1.0,0) [0|252] "" IPB_App1
 SG_ TPDiagnosisFlashFBD_TrunkIPB__14 : 104|8@1+ (1.0,0) [0|252] "" IPB_App1
 SG_ TPDiagnosisFlashFBD_TrunkIPB__15 : 112|8@1+ (1.0,0) [0|252] "" IPB_App1
 SG_ TPDiagnosisFlashFBD_TrunkIPB__16 : 120|8@1+ (1.0,0) [0|252] "" IPB_App1
 SG_ TPDiagnosisFlashFBD_TrunkIPB__17 : 128|8@1+ (1.0,0) [0|252] "" IPB_App1
 SG_ TPDiagnosisFlashFBD_TrunkIPB__18 : 136|8@1+ (1.0,0) [0|252] "" IPB_App1
 SG_ TPDiagnosisFlashFBD_TrunkIPB__19 : 144|8@1+ (1.0,0) [0|252] "" IPB_App1
 SG_ TPDiagnosisFlashFBD_TrunkIPB__20 : 152|8@1+ (1.0,0) [0|252] "" IPB_App1
 SG_ TPDiagnosisFlashFBD_TrunkIPB__21 : 160|8@1+ (1.0,0) [0|252] "" IPB_App1
 SG_ TPDiagnosisFlashFBD_TrunkIPB__22 : 168|8@1+ (1.0,0) [0|252] "" IPB_App1
 SG_ TPDiagnosisFlashFBD_TrunkIPB__23 : 176|8@1+ (1.0,0) [0|252] "" IPB_App1
 SG_ TPDiagnosisFlashFBD_TrunkIPB__24 : 184|8@1+ (1.0,0) [0|252] "" IPB_App1
 SG_ TPDiagnosisFlashFBD_TrunkIPB__25 : 192|8@1+ (1.0,0) [0|252] "" IPB_App1
 SG_ TPDiagnosisFlashFBD_TrunkIPB__26 : 200|8@1+ (1.0,0) [0|252] "" IPB_App1
 SG_ TPDiagnosisFlashFBD_TrunkIPB__27 : 208|8@1+ (1.0,0) [0|252] "" IPB_App1
 SG_ TPDiagnosisFlashFBD_TrunkIPB__28 : 216|8@1+ (1.0,0) [0|252] "" IPB_App1
 SG_ TPDiagnosisFlashFBD_TrunkIPB__29 : 224|8@1+ (1.0,0) [0|252] "" IPB_App1
 SG_ TPDiagnosisFlashFBD_TrunkIPB__30 : 232|8@1+ (1.0,0) [0|252] "" IPB_App1
 SG_ TPDiagnosisFlashFBD_TrunkIPB__31 : 240|8@1+ (1.0,0) [0|252] "" IPB_App1
 SG_ TPDiagnosisFlashFBD_TrunkIPB__32 : 248|8@1+ (1.0,0) [0|252] "" IPB_App1
 SG_ TPDiagnosisFlashFBD_TrunkIPB__33 : 256|8@1+ (1.0,0) [0|252] "" IPB_App1
 SG_ TPDiagnosisFlashFBD_TrunkIPB__34 : 264|8@1+ (1.0,0) [0|252] "" IPB_App1
 SG_ TPDiagnosisFlashFBD_TrunkIPB__35 : 272|8@1+ (1.0,0) [0|252] "" IPB_App1
 SG_ TPDiagnosisFlashFBD_TrunkIPB__36 : 280|8@1+ (1.0,0) [0|252] "" IPB_App1
 SG_ TPDiagnosisFlashFBD_TrunkIPB__37 : 288|8@1+ (1.0,0) [0|252] "" IPB_App1
 SG_ TPDiagnosisFlashFBD_TrunkIPB__38 : 296|8@1+ (1.0,0) [0|252] "" IPB_App1
 SG_ TPDiagnosisFlashFBD_TrunkIPB__39 : 304|8@1+ (1.0,0) [0|252] "" IPB_App1
 SG_ TPDiagnosisFlashFBD_TrunkIPB__40 : 312|8@1+ (1.0,0) [0|252] "" IPB_App1
 SG_ TPDiagnosisFlashFBD_TrunkIPB__41 : 320|8@1+ (1.0,0) [0|252] "" IPB_App1
 SG_ TPDiagnosisFlashFBD_TrunkIPB__42 : 328|8@1+ (1.0,0) [0|252] "" IPB_App1
 SG_ TPDiagnosisFlashFBD_TrunkIPB__43 : 336|8@1+ (1.0,0) [0|252] "" IPB_App1
 SG_ TPDiagnosisFlashFBD_TrunkIPB__44 : 344|8@1+ (1.0,0) [0|252] "" IPB_App1
 SG_ TPDiagnosisFlashFBD_TrunkIPB__45 : 352|8@1+ (1.0,0) [0|252] "" IPB_App1
 SG_ TPDiagnosisFlashFBD_TrunkIPB__46 : 360|8@1+ (1.0,0) [0|252] "" IPB_App1
 SG_ TPDiagnosisFlashFBD_TrunkIPB__47 : 368|8@1+ (1.0,0) [0|252] "" IPB_App1
 SG_ TPDiagnosisFlashFBD_TrunkIPB__48 : 376|8@1+ (1.0,0) [0|252] "" IPB_App1
 SG_ TPDiagnosisFlashFBD_TrunkIPB__49 : 384|8@1+ (1.0,0) [0|252] "" IPB_App1
 SG_ TPDiagnosisFlashFBD_TrunkIPB__50 : 392|8@1+ (1.0,0) [0|252] "" IPB_App1
 SG_ TPDiagnosisFlashFBD_TrunkIPB__51 : 400|8@1+ (1.0,0) [0|252] "" IPB_App1
 SG_ TPDiagnosisFlashFBD_TrunkIPB__52 : 408|8@1+ (1.0,0) [0|252] "" IPB_App1
 SG_ TPDiagnosisFlashFBD_TrunkIPB__53 : 416|8@1+ (1.0,0) [0|252] "" IPB_App1
 SG_ TPDiagnosisFlashFBD_TrunkIPB__54 : 424|8@1+ (1.0,0) [0|252] "" IPB_App1
 SG_ TPDiagnosisFlashFBD_TrunkIPB__55 : 432|8@1+ (1.0,0) [0|252] "" IPB_App1
 SG_ TPDiagnosisFlashFBD_TrunkIPB__56 : 440|8@1+ (1.0,0) [0|252] "" IPB_App1
 SG_ TPDiagnosisFlashFBD_TrunkIPB__57 : 448|8@1+ (1.0,0) [0|252] "" IPB_App1
 SG_ TPDiagnosisFlashFBD_TrunkIPB__58 : 456|8@1+ (1.0,0) [0|252] "" IPB_App1
 SG_ TPDiagnosisFlashFBD_TrunkIPB__59 : 464|8@1+ (1.0,0) [0|252] "" IPB_App1
 SG_ TPDiagnosisFlashFBD_TrunkIPB__60 : 472|8@1+ (1.0,0) [0|252] "" IPB_App1
 SG_ TPDiagnosisFlashFBD_TrunkIPB__61 : 480|8@1+ (1.0,0) [0|252] "" IPB_App1
 SG_ TPDiagnosisFlashFBD_TrunkIPB__62 : 488|8@1+ (1.0,0) [0|252] "" IPB_App1
 SG_ TPDiagnosisFlashFBD_TrunkIPB__63 : 496|8@1+ (1.0,0) [0|252] "" IPB_App1
 SG_ TPDiagnosisFlashFBD_TrunkIPB__64 : 504|8@1+ (1.0,0) [0|252] "" IPB_App1

BO_ 714 TPDiagnosisFlash_FBD_VL_IPB: 64 FBD_VL
 SG_ TPDiagnosisFlashFBD_VLIPB_Byte00 : 0|8@1+ (1.0,0) [0|252] "" IPB_App1
 SG_ TPDiagnosisFlashFBD_VLIPB_Byte01 : 8|8@1+ (1.0,0) [0|252] "" IPB_App1
 SG_ TPDiagnosisFlashFBD_VLIPB_Byte02 : 16|8@1+ (1.0,0) [0|252] "" IPB_App1
 SG_ TPDiagnosisFlashFBD_VLIPB_Byte03 : 24|8@1+ (1.0,0) [0|252] "" IPB_App1
 SG_ TPDiagnosisFlashFBD_VLIPB_Byte04 : 32|8@1+ (1.0,0) [0|252] "" IPB_App1
 SG_ TPDiagnosisFlashFBD_VLIPB_Byte05 : 40|8@1+ (1.0,0) [0|252] "" IPB_App1
 SG_ TPDiagnosisFlashFBD_VLIPB_Byte06 : 48|8@1+ (1.0,0) [0|252] "" IPB_App1
 SG_ TPDiagnosisFlashFBD_VLIPB_Byte07 : 56|8@1+ (1.0,0) [0|252] "" IPB_App1
 SG_ TPDiagnosisFlashFBD_VLIPB_Byte08 : 64|8@1+ (1.0,0) [0|252] "" IPB_App1
 SG_ TPDiagnosisFlashFBD_VLIPB_Byte09 : 72|8@1+ (1.0,0) [0|252] "" IPB_App1
 SG_ TPDiagnosisFlashFBD_VLIPB_Byte10 : 80|8@1+ (1.0,0) [0|252] "" IPB_App1
 SG_ TPDiagnosisFlashFBD_VLIPB_Byte11 : 88|8@1+ (1.0,0) [0|252] "" IPB_App1
 SG_ TPDiagnosisFlashFBD_VLIPB_Byte12 : 96|8@1+ (1.0,0) [0|252] "" IPB_App1
 SG_ TPDiagnosisFlashFBD_VLIPB_Byte13 : 104|8@1+ (1.0,0) [0|252] "" IPB_App1
 SG_ TPDiagnosisFlashFBD_VLIPB_Byte14 : 112|8@1+ (1.0,0) [0|252] "" IPB_App1
 SG_ TPDiagnosisFlashFBD_VLIPB_Byte15 : 120|8@1+ (1.0,0) [0|252] "" IPB_App1
 SG_ TPDiagnosisFlashFBD_VLIPB_Byte16 : 128|8@1+ (1.0,0) [0|252] "" IPB_App1
 SG_ TPDiagnosisFlashFBD_VLIPB_Byte17 : 136|8@1+ (1.0,0) [0|252] "" IPB_App1
 SG_ TPDiagnosisFlashFBD_VLIPB_Byte18 : 144|8@1+ (1.0,0) [0|252] "" IPB_App1
 SG_ TPDiagnosisFlashFBD_VLIPB_Byte19 : 152|8@1+ (1.0,0) [0|252] "" IPB_App1
 SG_ TPDiagnosisFlashFBD_VLIPB_Byte20 : 160|8@1+ (1.0,0) [0|252] "" IPB_App1
 SG_ TPDiagnosisFlashFBD_VLIPB_Byte21 : 168|8@1+ (1.0,0) [0|252] "" IPB_App1
 SG_ TPDiagnosisFlashFBD_VLIPB_Byte22 : 176|8@1+ (1.0,0) [0|252] "" IPB_App1
 SG_ TPDiagnosisFlashFBD_VLIPB_Byte23 : 184|8@1+ (1.0,0) [0|252] "" IPB_App1
 SG_ TPDiagnosisFlashFBD_VLIPB_Byte24 : 192|8@1+ (1.0,0) [0|252] "" IPB_App1
 SG_ TPDiagnosisFlashFBD_VLIPB_Byte25 : 200|8@1+ (1.0,0) [0|252] "" IPB_App1
 SG_ TPDiagnosisFlashFBD_VLIPB_Byte26 : 208|8@1+ (1.0,0) [0|252] "" IPB_App1
 SG_ TPDiagnosisFlashFBD_VLIPB_Byte27 : 216|8@1+ (1.0,0) [0|252] "" IPB_App1
 SG_ TPDiagnosisFlashFBD_VLIPB_Byte28 : 224|8@1+ (1.0,0) [0|252] "" IPB_App1
 SG_ TPDiagnosisFlashFBD_VLIPB_Byte29 : 232|8@1+ (1.0,0) [0|252] "" IPB_App1
 SG_ TPDiagnosisFlashFBD_VLIPB_Byte30 : 240|8@1+ (1.0,0) [0|252] "" IPB_App1
 SG_ TPDiagnosisFlashFBD_VLIPB_Byte31 : 248|8@1+ (1.0,0) [0|252] "" IPB_App1
 SG_ TPDiagnosisFlashFBD_VLIPB_Byte32 : 256|8@1+ (1.0,0) [0|252] "" IPB_App1
 SG_ TPDiagnosisFlashFBD_VLIPB_Byte33 : 264|8@1+ (1.0,0) [0|252] "" IPB_App1
 SG_ TPDiagnosisFlashFBD_VLIPB_Byte34 : 272|8@1+ (1.0,0) [0|252] "" IPB_App1
 SG_ TPDiagnosisFlashFBD_VLIPB_Byte35 : 280|8@1+ (1.0,0) [0|252] "" IPB_App1
 SG_ TPDiagnosisFlashFBD_VLIPB_Byte36 : 288|8@1+ (1.0,0) [0|252] "" IPB_App1
 SG_ TPDiagnosisFlashFBD_VLIPB_Byte37 : 296|8@1+ (1.0,0) [0|252] "" IPB_App1
 SG_ TPDiagnosisFlashFBD_VLIPB_Byte38 : 304|8@1+ (1.0,0) [0|252] "" IPB_App1
 SG_ TPDiagnosisFlashFBD_VLIPB_Byte39 : 312|8@1+ (1.0,0) [0|252] "" IPB_App1
 SG_ TPDiagnosisFlashFBD_VLIPB_Byte40 : 320|8@1+ (1.0,0) [0|252] "" IPB_App1
 SG_ TPDiagnosisFlashFBD_VLIPB_Byte41 : 328|8@1+ (1.0,0) [0|252] "" IPB_App1
 SG_ TPDiagnosisFlashFBD_VLIPB_Byte42 : 336|8@1+ (1.0,0) [0|252] "" IPB_App1
 SG_ TPDiagnosisFlashFBD_VLIPB_Byte43 : 344|8@1+ (1.0,0) [0|252] "" IPB_App1
 SG_ TPDiagnosisFlashFBD_VLIPB_Byte44 : 352|8@1+ (1.0,0) [0|252] "" IPB_App1
 SG_ TPDiagnosisFlashFBD_VLIPB_Byte45 : 360|8@1+ (1.0,0) [0|252] "" IPB_App1
 SG_ TPDiagnosisFlashFBD_VLIPB_Byte46 : 368|8@1+ (1.0,0) [0|252] "" IPB_App1
 SG_ TPDiagnosisFlashFBD_VLIPB_Byte47 : 376|8@1+ (1.0,0) [0|252] "" IPB_App1
 SG_ TPDiagnosisFlashFBD_VLIPB_Byte48 : 384|8@1+ (1.0,0) [0|252] "" IPB_App1
 SG_ TPDiagnosisFlashFBD_VLIPB_Byte49 : 392|8@1+ (1.0,0) [0|252] "" IPB_App1
 SG_ TPDiagnosisFlashFBD_VLIPB_Byte50 : 400|8@1+ (1.0,0) [0|252] "" IPB_App1
 SG_ TPDiagnosisFlashFBD_VLIPB_Byte51 : 408|8@1+ (1.0,0) [0|252] "" IPB_App1
 SG_ TPDiagnosisFlashFBD_VLIPB_Byte52 : 416|8@1+ (1.0,0) [0|252] "" IPB_App1
 SG_ TPDiagnosisFlashFBD_VLIPB_Byte53 : 424|8@1+ (1.0,0) [0|252] "" IPB_App1
 SG_ TPDiagnosisFlashFBD_VLIPB_Byte54 : 432|8@1+ (1.0,0) [0|252] "" IPB_App1
 SG_ TPDiagnosisFlashFBD_VLIPB_Byte55 : 440|8@1+ (1.0,0) [0|252] "" IPB_App1
 SG_ TPDiagnosisFlashFBD_VLIPB_Byte56 : 448|8@1+ (1.0,0) [0|252] "" IPB_App1
 SG_ TPDiagnosisFlashFBD_VLIPB_Byte57 : 456|8@1+ (1.0,0) [0|252] "" IPB_App1
 SG_ TPDiagnosisFlashFBD_VLIPB_Byte58 : 464|8@1+ (1.0,0) [0|252] "" IPB_App1
 SG_ TPDiagnosisFlashFBD_VLIPB_Byte59 : 472|8@1+ (1.0,0) [0|252] "" IPB_App1
 SG_ TPDiagnosisFlashFBD_VLIPB_Byte60 : 480|8@1+ (1.0,0) [0|252] "" IPB_App1
 SG_ TPDiagnosisFlashFBD_VLIPB_Byte61 : 488|8@1+ (1.0,0) [0|252] "" IPB_App1
 SG_ TPDiagnosisFlashFBD_VLIPB_Byte62 : 496|8@1+ (1.0,0) [0|252] "" IPB_App1
 SG_ TPDiagnosisFlashFBD_VLIPB_Byte63 : 504|8@1+ (1.0,0) [0|252] "" IPB_App1

BO_ 710 TPDiagnosisFlash_FBD_VM_IPB: 64 FBD_VM
 SG_ TPDiagnosisFlashFBD_VMIPB_Byte00 : 0|8@1+ (1.0,0) [0|252] "" IPB_App1
 SG_ TPDiagnosisFlashFBD_VMIPB_Byte01 : 8|8@1+ (1.0,0) [0|252] "" IPB_App1
 SG_ TPDiagnosisFlashFBD_VMIPB_Byte02 : 16|8@1+ (1.0,0) [0|252] "" IPB_App1
 SG_ TPDiagnosisFlashFBD_VMIPB_Byte03 : 24|8@1+ (1.0,0) [0|252] "" IPB_App1
 SG_ TPDiagnosisFlashFBD_VMIPB_Byte04 : 32|8@1+ (1.0,0) [0|252] "" IPB_App1
 SG_ TPDiagnosisFlashFBD_VMIPB_Byte05 : 40|8@1+ (1.0,0) [0|252] "" IPB_App1
 SG_ TPDiagnosisFlashFBD_VMIPB_Byte06 : 48|8@1+ (1.0,0) [0|252] "" IPB_App1
 SG_ TPDiagnosisFlashFBD_VMIPB_Byte07 : 56|8@1+ (1.0,0) [0|252] "" IPB_App1
 SG_ TPDiagnosisFlashFBD_VMIPB_Byte08 : 64|8@1+ (1.0,0) [0|252] "" IPB_App1
 SG_ TPDiagnosisFlashFBD_VMIPB_Byte09 : 72|8@1+ (1.0,0) [0|252] "" IPB_App1
 SG_ TPDiagnosisFlashFBD_VMIPB_Byte10 : 80|8@1+ (1.0,0) [0|252] "" IPB_App1
 SG_ TPDiagnosisFlashFBD_VMIPB_Byte11 : 88|8@1+ (1.0,0) [0|252] "" IPB_App1
 SG_ TPDiagnosisFlashFBD_VMIPB_Byte12 : 96|8@1+ (1.0,0) [0|252] "" IPB_App1
 SG_ TPDiagnosisFlashFBD_VMIPB_Byte13 : 104|8@1+ (1.0,0) [0|252] "" IPB_App1
 SG_ TPDiagnosisFlashFBD_VMIPB_Byte14 : 112|8@1+ (1.0,0) [0|252] "" IPB_App1
 SG_ TPDiagnosisFlashFBD_VMIPB_Byte15 : 120|8@1+ (1.0,0) [0|252] "" IPB_App1
 SG_ TPDiagnosisFlashFBD_VMIPB_Byte16 : 128|8@1+ (1.0,0) [0|252] "" IPB_App1
 SG_ TPDiagnosisFlashFBD_VMIPB_Byte17 : 136|8@1+ (1.0,0) [0|252] "" IPB_App1
 SG_ TPDiagnosisFlashFBD_VMIPB_Byte18 : 144|8@1+ (1.0,0) [0|252] "" IPB_App1
 SG_ TPDiagnosisFlashFBD_VMIPB_Byte19 : 152|8@1+ (1.0,0) [0|252] "" IPB_App1
 SG_ TPDiagnosisFlashFBD_VMIPB_Byte20 : 160|8@1+ (1.0,0) [0|252] "" IPB_App1
 SG_ TPDiagnosisFlashFBD_VMIPB_Byte21 : 168|8@1+ (1.0,0) [0|252] "" IPB_App1
 SG_ TPDiagnosisFlashFBD_VMIPB_Byte22 : 176|8@1+ (1.0,0) [0|252] "" IPB_App1
 SG_ TPDiagnosisFlashFBD_VMIPB_Byte23 : 184|8@1+ (1.0,0) [0|252] "" IPB_App1
 SG_ TPDiagnosisFlashFBD_VMIPB_Byte24 : 192|8@1+ (1.0,0) [0|252] "" IPB_App1
 SG_ TPDiagnosisFlashFBD_VMIPB_Byte25 : 200|8@1+ (1.0,0) [0|252] "" IPB_App1
 SG_ TPDiagnosisFlashFBD_VMIPB_Byte26 : 208|8@1+ (1.0,0) [0|252] "" IPB_App1
 SG_ TPDiagnosisFlashFBD_VMIPB_Byte27 : 216|8@1+ (1.0,0) [0|252] "" IPB_App1
 SG_ TPDiagnosisFlashFBD_VMIPB_Byte28 : 224|8@1+ (1.0,0) [0|252] "" IPB_App1
 SG_ TPDiagnosisFlashFBD_VMIPB_Byte29 : 232|8@1+ (1.0,0) [0|252] "" IPB_App1
 SG_ TPDiagnosisFlashFBD_VMIPB_Byte30 : 240|8@1+ (1.0,0) [0|252] "" IPB_App1
 SG_ TPDiagnosisFlashFBD_VMIPB_Byte31 : 248|8@1+ (1.0,0) [0|252] "" IPB_App1
 SG_ TPDiagnosisFlashFBD_VMIPB_Byte32 : 256|8@1+ (1.0,0) [0|252] "" IPB_App1
 SG_ TPDiagnosisFlashFBD_VMIPB_Byte33 : 264|8@1+ (1.0,0) [0|252] "" IPB_App1
 SG_ TPDiagnosisFlashFBD_VMIPB_Byte34 : 272|8@1+ (1.0,0) [0|252] "" IPB_App1
 SG_ TPDiagnosisFlashFBD_VMIPB_Byte35 : 280|8@1+ (1.0,0) [0|252] "" IPB_App1
 SG_ TPDiagnosisFlashFBD_VMIPB_Byte36 : 288|8@1+ (1.0,0) [0|252] "" IPB_App1
 SG_ TPDiagnosisFlashFBD_VMIPB_Byte37 : 296|8@1+ (1.0,0) [0|252] "" IPB_App1
 SG_ TPDiagnosisFlashFBD_VMIPB_Byte38 : 304|8@1+ (1.0,0) [0|252] "" IPB_App1
 SG_ TPDiagnosisFlashFBD_VMIPB_Byte39 : 312|8@1+ (1.0,0) [0|252] "" IPB_App1
 SG_ TPDiagnosisFlashFBD_VMIPB_Byte40 : 320|8@1+ (1.0,0) [0|252] "" IPB_App1
 SG_ TPDiagnosisFlashFBD_VMIPB_Byte41 : 328|8@1+ (1.0,0) [0|252] "" IPB_App1
 SG_ TPDiagnosisFlashFBD_VMIPB_Byte42 : 336|8@1+ (1.0,0) [0|252] "" IPB_App1
 SG_ TPDiagnosisFlashFBD_VMIPB_Byte43 : 344|8@1+ (1.0,0) [0|252] "" IPB_App1
 SG_ TPDiagnosisFlashFBD_VMIPB_Byte44 : 352|8@1+ (1.0,0) [0|252] "" IPB_App1
 SG_ TPDiagnosisFlashFBD_VMIPB_Byte45 : 360|8@1+ (1.0,0) [0|252] "" IPB_App1
 SG_ TPDiagnosisFlashFBD_VMIPB_Byte46 : 368|8@1+ (1.0,0) [0|252] "" IPB_App1
 SG_ TPDiagnosisFlashFBD_VMIPB_Byte47 : 376|8@1+ (1.0,0) [0|252] "" IPB_App1
 SG_ TPDiagnosisFlashFBD_VMIPB_Byte48 : 384|8@1+ (1.0,0) [0|252] "" IPB_App1
 SG_ TPDiagnosisFlashFBD_VMIPB_Byte49 : 392|8@1+ (1.0,0) [0|252] "" IPB_App1
 SG_ TPDiagnosisFlashFBD_VMIPB_Byte50 : 400|8@1+ (1.0,0) [0|252] "" IPB_App1
 SG_ TPDiagnosisFlashFBD_VMIPB_Byte51 : 408|8@1+ (1.0,0) [0|252] "" IPB_App1
 SG_ TPDiagnosisFlashFBD_VMIPB_Byte52 : 416|8@1+ (1.0,0) [0|252] "" IPB_App1
 SG_ TPDiagnosisFlashFBD_VMIPB_Byte53 : 424|8@1+ (1.0,0) [0|252] "" IPB_App1
 SG_ TPDiagnosisFlashFBD_VMIPB_Byte54 : 432|8@1+ (1.0,0) [0|252] "" IPB_App1
 SG_ TPDiagnosisFlashFBD_VMIPB_Byte55 : 440|8@1+ (1.0,0) [0|252] "" IPB_App1
 SG_ TPDiagnosisFlashFBD_VMIPB_Byte56 : 448|8@1+ (1.0,0) [0|252] "" IPB_App1
 SG_ TPDiagnosisFlashFBD_VMIPB_Byte57 : 456|8@1+ (1.0,0) [0|252] "" IPB_App1
 SG_ TPDiagnosisFlashFBD_VMIPB_Byte58 : 464|8@1+ (1.0,0) [0|252] "" IPB_App1
 SG_ TPDiagnosisFlashFBD_VMIPB_Byte59 : 472|8@1+ (1.0,0) [0|252] "" IPB_App1
 SG_ TPDiagnosisFlashFBD_VMIPB_Byte60 : 480|8@1+ (1.0,0) [0|252] "" IPB_App1
 SG_ TPDiagnosisFlashFBD_VMIPB_Byte61 : 488|8@1+ (1.0,0) [0|252] "" IPB_App1
 SG_ TPDiagnosisFlashFBD_VMIPB_Byte62 : 496|8@1+ (1.0,0) [0|252] "" IPB_App1
 SG_ TPDiagnosisFlashFBD_VMIPB_Byte63 : 504|8@1+ (1.0,0) [0|252] "" IPB_App1

BO_ 715 TPDiagnosisFlash_FBD_VR_IPB: 64 FBD_VR
 SG_ TPDiagnosisFlashFBD_VRIPB_Byte00 : 0|8@1+ (1.0,0) [0|252] "" IPB_App1
 SG_ TPDiagnosisFlashFBD_VRIPB_Byte01 : 8|8@1+ (1.0,0) [0|252] "" IPB_App1
 SG_ TPDiagnosisFlashFBD_VRIPB_Byte02 : 16|8@1+ (1.0,0) [0|252] "" IPB_App1
 SG_ TPDiagnosisFlashFBD_VRIPB_Byte03 : 24|8@1+ (1.0,0) [0|252] "" IPB_App1
 SG_ TPDiagnosisFlashFBD_VRIPB_Byte04 : 32|8@1+ (1.0,0) [0|252] "" IPB_App1
 SG_ TPDiagnosisFlashFBD_VRIPB_Byte05 : 40|8@1+ (1.0,0) [0|252] "" IPB_App1
 SG_ TPDiagnosisFlashFBD_VRIPB_Byte06 : 48|8@1+ (1.0,0) [0|252] "" IPB_App1
 SG_ TPDiagnosisFlashFBD_VRIPB_Byte07 : 56|8@1+ (1.0,0) [0|252] "" IPB_App1
 SG_ TPDiagnosisFlashFBD_VRIPB_Byte08 : 64|8@1+ (1.0,0) [0|252] "" IPB_App1
 SG_ TPDiagnosisFlashFBD_VRIPB_Byte09 : 72|8@1+ (1.0,0) [0|252] "" IPB_App1
 SG_ TPDiagnosisFlashFBD_VRIPB_Byte10 : 80|8@1+ (1.0,0) [0|252] "" IPB_App1
 SG_ TPDiagnosisFlashFBD_VRIPB_Byte11 : 88|8@1+ (1.0,0) [0|252] "" IPB_App1
 SG_ TPDiagnosisFlashFBD_VRIPB_Byte12 : 96|8@1+ (1.0,0) [0|252] "" IPB_App1
 SG_ TPDiagnosisFlashFBD_VRIPB_Byte13 : 104|8@1+ (1.0,0) [0|252] "" IPB_App1
 SG_ TPDiagnosisFlashFBD_VRIPB_Byte14 : 112|8@1+ (1.0,0) [0|252] "" IPB_App1
 SG_ TPDiagnosisFlashFBD_VRIPB_Byte15 : 120|8@1+ (1.0,0) [0|252] "" IPB_App1
 SG_ TPDiagnosisFlashFBD_VRIPB_Byte16 : 128|8@1+ (1.0,0) [0|252] "" IPB_App1
 SG_ TPDiagnosisFlashFBD_VRIPB_Byte17 : 136|8@1+ (1.0,0) [0|252] "" IPB_App1
 SG_ TPDiagnosisFlashFBD_VRIPB_Byte18 : 144|8@1+ (1.0,0) [0|252] "" IPB_App1
 SG_ TPDiagnosisFlashFBD_VRIPB_Byte19 : 152|8@1+ (1.0,0) [0|252] "" IPB_App1
 SG_ TPDiagnosisFlashFBD_VRIPB_Byte20 : 160|8@1+ (1.0,0) [0|252] "" IPB_App1
 SG_ TPDiagnosisFlashFBD_VRIPB_Byte21 : 168|8@1+ (1.0,0) [0|252] "" IPB_App1
 SG_ TPDiagnosisFlashFBD_VRIPB_Byte22 : 176|8@1+ (1.0,0) [0|252] "" IPB_App1
 SG_ TPDiagnosisFlashFBD_VRIPB_Byte23 : 184|8@1+ (1.0,0) [0|252] "" IPB_App1
 SG_ TPDiagnosisFlashFBD_VRIPB_Byte24 : 192|8@1+ (1.0,0) [0|252] "" IPB_App1
 SG_ TPDiagnosisFlashFBD_VRIPB_Byte25 : 200|8@1+ (1.0,0) [0|252] "" IPB_App1
 SG_ TPDiagnosisFlashFBD_VRIPB_Byte26 : 208|8@1+ (1.0,0) [0|252] "" IPB_App1
 SG_ TPDiagnosisFlashFBD_VRIPB_Byte27 : 216|8@1+ (1.0,0) [0|252] "" IPB_App1
 SG_ TPDiagnosisFlashFBD_VRIPB_Byte28 : 224|8@1+ (1.0,0) [0|252] "" IPB_App1
 SG_ TPDiagnosisFlashFBD_VRIPB_Byte29 : 232|8@1+ (1.0,0) [0|252] "" IPB_App1
 SG_ TPDiagnosisFlashFBD_VRIPB_Byte30 : 240|8@1+ (1.0,0) [0|252] "" IPB_App1
 SG_ TPDiagnosisFlashFBD_VRIPB_Byte31 : 248|8@1+ (1.0,0) [0|252] "" IPB_App1
 SG_ TPDiagnosisFlashFBD_VRIPB_Byte32 : 256|8@1+ (1.0,0) [0|252] "" IPB_App1
 SG_ TPDiagnosisFlashFBD_VRIPB_Byte33 : 264|8@1+ (1.0,0) [0|252] "" IPB_App1
 SG_ TPDiagnosisFlashFBD_VRIPB_Byte34 : 272|8@1+ (1.0,0) [0|252] "" IPB_App1
 SG_ TPDiagnosisFlashFBD_VRIPB_Byte35 : 280|8@1+ (1.0,0) [0|252] "" IPB_App1
 SG_ TPDiagnosisFlashFBD_VRIPB_Byte36 : 288|8@1+ (1.0,0) [0|252] "" IPB_App1
 SG_ TPDiagnosisFlashFBD_VRIPB_Byte37 : 296|8@1+ (1.0,0) [0|252] "" IPB_App1
 SG_ TPDiagnosisFlashFBD_VRIPB_Byte38 : 304|8@1+ (1.0,0) [0|252] "" IPB_App1
 SG_ TPDiagnosisFlashFBD_VRIPB_Byte39 : 312|8@1+ (1.0,0) [0|252] "" IPB_App1
 SG_ TPDiagnosisFlashFBD_VRIPB_Byte40 : 320|8@1+ (1.0,0) [0|252] "" IPB_App1
 SG_ TPDiagnosisFlashFBD_VRIPB_Byte41 : 328|8@1+ (1.0,0) [0|252] "" IPB_App1
 SG_ TPDiagnosisFlashFBD_VRIPB_Byte42 : 336|8@1+ (1.0,0) [0|252] "" IPB_App1
 SG_ TPDiagnosisFlashFBD_VRIPB_Byte43 : 344|8@1+ (1.0,0) [0|252] "" IPB_App1
 SG_ TPDiagnosisFlashFBD_VRIPB_Byte44 : 352|8@1+ (1.0,0) [0|252] "" IPB_App1
 SG_ TPDiagnosisFlashFBD_VRIPB_Byte45 : 360|8@1+ (1.0,0) [0|252] "" IPB_App1
 SG_ TPDiagnosisFlashFBD_VRIPB_Byte46 : 368|8@1+ (1.0,0) [0|252] "" IPB_App1
 SG_ TPDiagnosisFlashFBD_VRIPB_Byte47 : 376|8@1+ (1.0,0) [0|252] "" IPB_App1
 SG_ TPDiagnosisFlashFBD_VRIPB_Byte48 : 384|8@1+ (1.0,0) [0|252] "" IPB_App1
 SG_ TPDiagnosisFlashFBD_VRIPB_Byte49 : 392|8@1+ (1.0,0) [0|252] "" IPB_App1
 SG_ TPDiagnosisFlashFBD_VRIPB_Byte50 : 400|8@1+ (1.0,0) [0|252] "" IPB_App1
 SG_ TPDiagnosisFlashFBD_VRIPB_Byte51 : 408|8@1+ (1.0,0) [0|252] "" IPB_App1
 SG_ TPDiagnosisFlashFBD_VRIPB_Byte52 : 416|8@1+ (1.0,0) [0|252] "" IPB_App1
 SG_ TPDiagnosisFlashFBD_VRIPB_Byte53 : 424|8@1+ (1.0,0) [0|252] "" IPB_App1
 SG_ TPDiagnosisFlashFBD_VRIPB_Byte54 : 432|8@1+ (1.0,0) [0|252] "" IPB_App1
 SG_ TPDiagnosisFlashFBD_VRIPB_Byte55 : 440|8@1+ (1.0,0) [0|252] "" IPB_App1
 SG_ TPDiagnosisFlashFBD_VRIPB_Byte56 : 448|8@1+ (1.0,0) [0|252] "" IPB_App1
 SG_ TPDiagnosisFlashFBD_VRIPB_Byte57 : 456|8@1+ (1.0,0) [0|252] "" IPB_App1
 SG_ TPDiagnosisFlashFBD_VRIPB_Byte58 : 464|8@1+ (1.0,0) [0|252] "" IPB_App1
 SG_ TPDiagnosisFlashFBD_VRIPB_Byte59 : 472|8@1+ (1.0,0) [0|252] "" IPB_App1
 SG_ TPDiagnosisFlashFBD_VRIPB_Byte60 : 480|8@1+ (1.0,0) [0|252] "" IPB_App1
 SG_ TPDiagnosisFlashFBD_VRIPB_Byte61 : 488|8@1+ (1.0,0) [0|252] "" IPB_App1
 SG_ TPDiagnosisFlashFBD_VRIPB_Byte62 : 496|8@1+ (1.0,0) [0|252] "" IPB_App1
 SG_ TPDiagnosisFlashFBD_VRIPB_Byte63 : 504|8@1+ (1.0,0) [0|252] "" IPB_App1

BO_ 706 TPDiagnosisFlash_IPB_FBD_HL: 64 IPB_App1
 SG_ TPDiagnosisFlashIPBFBD_HL_Byte00 : 0|8@1+ (1.0,0) [0|252] "" FBD_HL
 SG_ TPDiagnosisFlashIPBFBD_HL_Byte01 : 8|8@1+ (1.0,0) [0|252] "" FBD_HL
 SG_ TPDiagnosisFlashIPBFBD_HL_Byte02 : 16|8@1+ (1.0,0) [0|252] "" FBD_HL
 SG_ TPDiagnosisFlashIPBFBD_HL_Byte03 : 24|8@1+ (1.0,0) [0|252] "" FBD_HL
 SG_ TPDiagnosisFlashIPBFBD_HL_Byte04 : 32|8@1+ (1.0,0) [0|252] "" FBD_HL
 SG_ TPDiagnosisFlashIPBFBD_HL_Byte05 : 40|8@1+ (1.0,0) [0|252] "" FBD_HL
 SG_ TPDiagnosisFlashIPBFBD_HL_Byte06 : 48|8@1+ (1.0,0) [0|252] "" FBD_HL
 SG_ TPDiagnosisFlashIPBFBD_HL_Byte07 : 56|8@1+ (1.0,0) [0|252] "" FBD_HL
 SG_ TPDiagnosisFlashIPBFBD_HL_Byte08 : 64|8@1+ (1.0,0) [0|252] "" FBD_HL
 SG_ TPDiagnosisFlashIPBFBD_HL_Byte09 : 72|8@1+ (1.0,0) [0|252] "" FBD_HL
 SG_ TPDiagnosisFlashIPBFBD_HL_Byte10 : 80|8@1+ (1.0,0) [0|252] "" FBD_HL
 SG_ TPDiagnosisFlashIPBFBD_HL_Byte11 : 88|8@1+ (1.0,0) [0|252] "" FBD_HL
 SG_ TPDiagnosisFlashIPBFBD_HL_Byte12 : 96|8@1+ (1.0,0) [0|252] "" FBD_HL
 SG_ TPDiagnosisFlashIPBFBD_HL_Byte13 : 104|8@1+ (1.0,0) [0|252] "" FBD_HL
 SG_ TPDiagnosisFlashIPBFBD_HL_Byte14 : 112|8@1+ (1.0,0) [0|252] "" FBD_HL
 SG_ TPDiagnosisFlashIPBFBD_HL_Byte15 : 120|8@1+ (1.0,0) [0|252] "" FBD_HL
 SG_ TPDiagnosisFlashIPBFBD_HL_Byte16 : 128|8@1+ (1.0,0) [0|252] "" FBD_HL
 SG_ TPDiagnosisFlashIPBFBD_HL_Byte17 : 136|8@1+ (1.0,0) [0|252] "" FBD_HL
 SG_ TPDiagnosisFlashIPBFBD_HL_Byte18 : 144|8@1+ (1.0,0) [0|252] "" FBD_HL
 SG_ TPDiagnosisFlashIPBFBD_HL_Byte19 : 152|8@1+ (1.0,0) [0|252] "" FBD_HL
 SG_ TPDiagnosisFlashIPBFBD_HL_Byte20 : 160|8@1+ (1.0,0) [0|252] "" FBD_HL
 SG_ TPDiagnosisFlashIPBFBD_HL_Byte21 : 168|8@1+ (1.0,0) [0|252] "" FBD_HL
 SG_ TPDiagnosisFlashIPBFBD_HL_Byte22 : 176|8@1+ (1.0,0) [0|252] "" FBD_HL
 SG_ TPDiagnosisFlashIPBFBD_HL_Byte23 : 184|8@1+ (1.0,0) [0|252] "" FBD_HL
 SG_ TPDiagnosisFlashIPBFBD_HL_Byte24 : 192|8@1+ (1.0,0) [0|252] "" FBD_HL
 SG_ TPDiagnosisFlashIPBFBD_HL_Byte25 : 200|8@1+ (1.0,0) [0|252] "" FBD_HL
 SG_ TPDiagnosisFlashIPBFBD_HL_Byte26 : 208|8@1+ (1.0,0) [0|252] "" FBD_HL
 SG_ TPDiagnosisFlashIPBFBD_HL_Byte27 : 216|8@1+ (1.0,0) [0|252] "" FBD_HL
 SG_ TPDiagnosisFlashIPBFBD_HL_Byte28 : 224|8@1+ (1.0,0) [0|252] "" FBD_HL
 SG_ TPDiagnosisFlashIPBFBD_HL_Byte29 : 232|8@1+ (1.0,0) [0|252] "" FBD_HL
 SG_ TPDiagnosisFlashIPBFBD_HL_Byte30 : 240|8@1+ (1.0,0) [0|252] "" FBD_HL
 SG_ TPDiagnosisFlashIPBFBD_HL_Byte31 : 248|8@1+ (1.0,0) [0|252] "" FBD_HL
 SG_ TPDiagnosisFlashIPBFBD_HL_Byte32 : 256|8@1+ (1.0,0) [0|252] "" FBD_HL
 SG_ TPDiagnosisFlashIPBFBD_HL_Byte33 : 264|8@1+ (1.0,0) [0|252] "" FBD_HL
 SG_ TPDiagnosisFlashIPBFBD_HL_Byte34 : 272|8@1+ (1.0,0) [0|252] "" FBD_HL
 SG_ TPDiagnosisFlashIPBFBD_HL_Byte35 : 280|8@1+ (1.0,0) [0|252] "" FBD_HL
 SG_ TPDiagnosisFlashIPBFBD_HL_Byte36 : 288|8@1+ (1.0,0) [0|252] "" FBD_HL
 SG_ TPDiagnosisFlashIPBFBD_HL_Byte37 : 296|8@1+ (1.0,0) [0|252] "" FBD_HL
 SG_ TPDiagnosisFlashIPBFBD_HL_Byte38 : 304|8@1+ (1.0,0) [0|252] "" FBD_HL
 SG_ TPDiagnosisFlashIPBFBD_HL_Byte39 : 312|8@1+ (1.0,0) [0|252] "" FBD_HL
 SG_ TPDiagnosisFlashIPBFBD_HL_Byte40 : 320|8@1+ (1.0,0) [0|252] "" FBD_HL
 SG_ TPDiagnosisFlashIPBFBD_HL_Byte41 : 328|8@1+ (1.0,0) [0|252] "" FBD_HL
 SG_ TPDiagnosisFlashIPBFBD_HL_Byte42 : 336|8@1+ (1.0,0) [0|252] "" FBD_HL
 SG_ TPDiagnosisFlashIPBFBD_HL_Byte43 : 344|8@1+ (1.0,0) [0|252] "" FBD_HL
 SG_ TPDiagnosisFlashIPBFBD_HL_Byte44 : 352|8@1+ (1.0,0) [0|252] "" FBD_HL
 SG_ TPDiagnosisFlashIPBFBD_HL_Byte45 : 360|8@1+ (1.0,0) [0|252] "" FBD_HL
 SG_ TPDiagnosisFlashIPBFBD_HL_Byte46 : 368|8@1+ (1.0,0) [0|252] "" FBD_HL
 SG_ TPDiagnosisFlashIPBFBD_HL_Byte47 : 376|8@1+ (1.0,0) [0|252] "" FBD_HL
 SG_ TPDiagnosisFlashIPBFBD_HL_Byte48 : 384|8@1+ (1.0,0) [0|252] "" FBD_HL
 SG_ TPDiagnosisFlashIPBFBD_HL_Byte49 : 392|8@1+ (1.0,0) [0|252] "" FBD_HL
 SG_ TPDiagnosisFlashIPBFBD_HL_Byte50 : 400|8@1+ (1.0,0) [0|252] "" FBD_HL
 SG_ TPDiagnosisFlashIPBFBD_HL_Byte51 : 408|8@1+ (1.0,0) [0|252] "" FBD_HL
 SG_ TPDiagnosisFlashIPBFBD_HL_Byte52 : 416|8@1+ (1.0,0) [0|252] "" FBD_HL
 SG_ TPDiagnosisFlashIPBFBD_HL_Byte53 : 424|8@1+ (1.0,0) [0|252] "" FBD_HL
 SG_ TPDiagnosisFlashIPBFBD_HL_Byte54 : 432|8@1+ (1.0,0) [0|252] "" FBD_HL
 SG_ TPDiagnosisFlashIPBFBD_HL_Byte55 : 440|8@1+ (1.0,0) [0|252] "" FBD_HL
 SG_ TPDiagnosisFlashIPBFBD_HL_Byte56 : 448|8@1+ (1.0,0) [0|252] "" FBD_HL
 SG_ TPDiagnosisFlashIPBFBD_HL_Byte57 : 456|8@1+ (1.0,0) [0|252] "" FBD_HL
 SG_ TPDiagnosisFlashIPBFBD_HL_Byte58 : 464|8@1+ (1.0,0) [0|252] "" FBD_HL
 SG_ TPDiagnosisFlashIPBFBD_HL_Byte59 : 472|8@1+ (1.0,0) [0|252] "" FBD_HL
 SG_ TPDiagnosisFlashIPBFBD_HL_Byte60 : 480|8@1+ (1.0,0) [0|252] "" FBD_HL
 SG_ TPDiagnosisFlashIPBFBD_HL_Byte61 : 488|8@1+ (1.0,0) [0|252] "" FBD_HL
 SG_ TPDiagnosisFlashIPBFBD_HL_Byte62 : 496|8@1+ (1.0,0) [0|252] "" FBD_HL
 SG_ TPDiagnosisFlashIPBFBD_HL_Byte63 : 504|8@1+ (1.0,0) [0|252] "" FBD_HL

BO_ 701 TPDiagnosisFlash_IPB_FBD_HM: 64 IPB_App1
 SG_ TPDiagnosisFlashIPBFBD_HM_Byte00 : 0|8@1+ (1.0,0) [0|252] "" FBD_HM
 SG_ TPDiagnosisFlashIPBFBD_HM_Byte01 : 8|8@1+ (1.0,0) [0|252] "" FBD_HM
 SG_ TPDiagnosisFlashIPBFBD_HM_Byte02 : 16|8@1+ (1.0,0) [0|252] "" FBD_HM
 SG_ TPDiagnosisFlashIPBFBD_HM_Byte03 : 24|8@1+ (1.0,0) [0|252] "" FBD_HM
 SG_ TPDiagnosisFlashIPBFBD_HM_Byte04 : 32|8@1+ (1.0,0) [0|252] "" FBD_HM
 SG_ TPDiagnosisFlashIPBFBD_HM_Byte05 : 40|8@1+ (1.0,0) [0|252] "" FBD_HM
 SG_ TPDiagnosisFlashIPBFBD_HM_Byte06 : 48|8@1+ (1.0,0) [0|252] "" FBD_HM
 SG_ TPDiagnosisFlashIPBFBD_HM_Byte07 : 56|8@1+ (1.0,0) [0|252] "" FBD_HM
 SG_ TPDiagnosisFlashIPBFBD_HM_Byte08 : 64|8@1+ (1.0,0) [0|252] "" FBD_HM
 SG_ TPDiagnosisFlashIPBFBD_HM_Byte09 : 72|8@1+ (1.0,0) [0|252] "" FBD_HM
 SG_ TPDiagnosisFlashIPBFBD_HM_Byte10 : 80|8@1+ (1.0,0) [0|252] "" FBD_HM
 SG_ TPDiagnosisFlashIPBFBD_HM_Byte11 : 88|8@1+ (1.0,0) [0|252] "" FBD_HM
 SG_ TPDiagnosisFlashIPBFBD_HM_Byte12 : 96|8@1+ (1.0,0) [0|252] "" FBD_HM
 SG_ TPDiagnosisFlashIPBFBD_HM_Byte13 : 104|8@1+ (1.0,0) [0|252] "" FBD_HM
 SG_ TPDiagnosisFlashIPBFBD_HM_Byte14 : 112|8@1+ (1.0,0) [0|252] "" FBD_HM
 SG_ TPDiagnosisFlashIPBFBD_HM_Byte15 : 120|8@1+ (1.0,0) [0|252] "" FBD_HM
 SG_ TPDiagnosisFlashIPBFBD_HM_Byte16 : 128|8@1+ (1.0,0) [0|252] "" FBD_HM
 SG_ TPDiagnosisFlashIPBFBD_HM_Byte17 : 136|8@1+ (1.0,0) [0|252] "" FBD_HM
 SG_ TPDiagnosisFlashIPBFBD_HM_Byte18 : 144|8@1+ (1.0,0) [0|252] "" FBD_HM
 SG_ TPDiagnosisFlashIPBFBD_HM_Byte19 : 152|8@1+ (1.0,0) [0|252] "" FBD_HM
 SG_ TPDiagnosisFlashIPBFBD_HM_Byte20 : 160|8@1+ (1.0,0) [0|252] "" FBD_HM
 SG_ TPDiagnosisFlashIPBFBD_HM_Byte21 : 168|8@1+ (1.0,0) [0|252] "" FBD_HM
 SG_ TPDiagnosisFlashIPBFBD_HM_Byte22 : 176|8@1+ (1.0,0) [0|252] "" FBD_HM
 SG_ TPDiagnosisFlashIPBFBD_HM_Byte23 : 184|8@1+ (1.0,0) [0|252] "" FBD_HM
 SG_ TPDiagnosisFlashIPBFBD_HM_Byte24 : 192|8@1+ (1.0,0) [0|252] "" FBD_HM
 SG_ TPDiagnosisFlashIPBFBD_HM_Byte25 : 200|8@1+ (1.0,0) [0|252] "" FBD_HM
 SG_ TPDiagnosisFlashIPBFBD_HM_Byte26 : 208|8@1+ (1.0,0) [0|252] "" FBD_HM
 SG_ TPDiagnosisFlashIPBFBD_HM_Byte27 : 216|8@1+ (1.0,0) [0|252] "" FBD_HM
 SG_ TPDiagnosisFlashIPBFBD_HM_Byte28 : 224|8@1+ (1.0,0) [0|252] "" FBD_HM
 SG_ TPDiagnosisFlashIPBFBD_HM_Byte29 : 232|8@1+ (1.0,0) [0|252] "" FBD_HM
 SG_ TPDiagnosisFlashIPBFBD_HM_Byte30 : 240|8@1+ (1.0,0) [0|252] "" FBD_HM
 SG_ TPDiagnosisFlashIPBFBD_HM_Byte31 : 248|8@1+ (1.0,0) [0|252] "" FBD_HM
 SG_ TPDiagnosisFlashIPBFBD_HM_Byte32 : 256|8@1+ (1.0,0) [0|252] "" FBD_HM
 SG_ TPDiagnosisFlashIPBFBD_HM_Byte33 : 264|8@1+ (1.0,0) [0|252] "" FBD_HM
 SG_ TPDiagnosisFlashIPBFBD_HM_Byte34 : 272|8@1+ (1.0,0) [0|252] "" FBD_HM
 SG_ TPDiagnosisFlashIPBFBD_HM_Byte35 : 280|8@1+ (1.0,0) [0|252] "" FBD_HM
 SG_ TPDiagnosisFlashIPBFBD_HM_Byte36 : 288|8@1+ (1.0,0) [0|252] "" FBD_HM
 SG_ TPDiagnosisFlashIPBFBD_HM_Byte37 : 296|8@1+ (1.0,0) [0|252] "" FBD_HM
 SG_ TPDiagnosisFlashIPBFBD_HM_Byte38 : 304|8@1+ (1.0,0) [0|252] "" FBD_HM
 SG_ TPDiagnosisFlashIPBFBD_HM_Byte39 : 312|8@1+ (1.0,0) [0|252] "" FBD_HM
 SG_ TPDiagnosisFlashIPBFBD_HM_Byte40 : 320|8@1+ (1.0,0) [0|252] "" FBD_HM
 SG_ TPDiagnosisFlashIPBFBD_HM_Byte41 : 328|8@1+ (1.0,0) [0|252] "" FBD_HM
 SG_ TPDiagnosisFlashIPBFBD_HM_Byte42 : 336|8@1+ (1.0,0) [0|252] "" FBD_HM
 SG_ TPDiagnosisFlashIPBFBD_HM_Byte43 : 344|8@1+ (1.0,0) [0|252] "" FBD_HM
 SG_ TPDiagnosisFlashIPBFBD_HM_Byte44 : 352|8@1+ (1.0,0) [0|252] "" FBD_HM
 SG_ TPDiagnosisFlashIPBFBD_HM_Byte45 : 360|8@1+ (1.0,0) [0|252] "" FBD_HM
 SG_ TPDiagnosisFlashIPBFBD_HM_Byte46 : 368|8@1+ (1.0,0) [0|252] "" FBD_HM
 SG_ TPDiagnosisFlashIPBFBD_HM_Byte47 : 376|8@1+ (1.0,0) [0|252] "" FBD_HM
 SG_ TPDiagnosisFlashIPBFBD_HM_Byte48 : 384|8@1+ (1.0,0) [0|252] "" FBD_HM
 SG_ TPDiagnosisFlashIPBFBD_HM_Byte49 : 392|8@1+ (1.0,0) [0|252] "" FBD_HM
 SG_ TPDiagnosisFlashIPBFBD_HM_Byte50 : 400|8@1+ (1.0,0) [0|252] "" FBD_HM
 SG_ TPDiagnosisFlashIPBFBD_HM_Byte51 : 408|8@1+ (1.0,0) [0|252] "" FBD_HM
 SG_ TPDiagnosisFlashIPBFBD_HM_Byte52 : 416|8@1+ (1.0,0) [0|252] "" FBD_HM
 SG_ TPDiagnosisFlashIPBFBD_HM_Byte53 : 424|8@1+ (1.0,0) [0|252] "" FBD_HM
 SG_ TPDiagnosisFlashIPBFBD_HM_Byte54 : 432|8@1+ (1.0,0) [0|252] "" FBD_HM
 SG_ TPDiagnosisFlashIPBFBD_HM_Byte55 : 440|8@1+ (1.0,0) [0|252] "" FBD_HM
 SG_ TPDiagnosisFlashIPBFBD_HM_Byte56 : 448|8@1+ (1.0,0) [0|252] "" FBD_HM
 SG_ TPDiagnosisFlashIPBFBD_HM_Byte57 : 456|8@1+ (1.0,0) [0|252] "" FBD_HM
 SG_ TPDiagnosisFlashIPBFBD_HM_Byte58 : 464|8@1+ (1.0,0) [0|252] "" FBD_HM
 SG_ TPDiagnosisFlashIPBFBD_HM_Byte59 : 472|8@1+ (1.0,0) [0|252] "" FBD_HM
 SG_ TPDiagnosisFlashIPBFBD_HM_Byte60 : 480|8@1+ (1.0,0) [0|252] "" FBD_HM
 SG_ TPDiagnosisFlashIPBFBD_HM_Byte61 : 488|8@1+ (1.0,0) [0|252] "" FBD_HM
 SG_ TPDiagnosisFlashIPBFBD_HM_Byte62 : 496|8@1+ (1.0,0) [0|252] "" FBD_HM
 SG_ TPDiagnosisFlashIPBFBD_HM_Byte63 : 504|8@1+ (1.0,0) [0|252] "" FBD_HM

BO_ 707 TPDiagnosisFlash_IPB_FBD_HR: 64 IPB_App1
 SG_ TPDiagnosisFlashIPBFBD_HR_Byte00 : 0|8@1+ (1.0,0) [0|252] "" FBD_HR
 SG_ TPDiagnosisFlashIPBFBD_HR_Byte01 : 8|8@1+ (1.0,0) [0|252] "" FBD_HR
 SG_ TPDiagnosisFlashIPBFBD_HR_Byte02 : 16|8@1+ (1.0,0) [0|252] "" FBD_HR
 SG_ TPDiagnosisFlashIPBFBD_HR_Byte03 : 24|8@1+ (1.0,0) [0|252] "" FBD_HR
 SG_ TPDiagnosisFlashIPBFBD_HR_Byte04 : 32|8@1+ (1.0,0) [0|252] "" FBD_HR
 SG_ TPDiagnosisFlashIPBFBD_HR_Byte05 : 40|8@1+ (1.0,0) [0|252] "" FBD_HR
 SG_ TPDiagnosisFlashIPBFBD_HR_Byte06 : 48|8@1+ (1.0,0) [0|252] "" FBD_HR
 SG_ TPDiagnosisFlashIPBFBD_HR_Byte07 : 56|8@1+ (1.0,0) [0|252] "" FBD_HR
 SG_ TPDiagnosisFlashIPBFBD_HR_Byte08 : 64|8@1+ (1.0,0) [0|252] "" FBD_HR
 SG_ TPDiagnosisFlashIPBFBD_HR_Byte09 : 72|8@1+ (1.0,0) [0|252] "" FBD_HR
 SG_ TPDiagnosisFlashIPBFBD_HR_Byte10 : 80|8@1+ (1.0,0) [0|252] "" FBD_HR
 SG_ TPDiagnosisFlashIPBFBD_HR_Byte11 : 88|8@1+ (1.0,0) [0|252] "" FBD_HR
 SG_ TPDiagnosisFlashIPBFBD_HR_Byte12 : 96|8@1+ (1.0,0) [0|252] "" FBD_HR
 SG_ TPDiagnosisFlashIPBFBD_HR_Byte13 : 104|8@1+ (1.0,0) [0|252] "" FBD_HR
 SG_ TPDiagnosisFlashIPBFBD_HR_Byte14 : 112|8@1+ (1.0,0) [0|252] "" FBD_HR
 SG_ TPDiagnosisFlashIPBFBD_HR_Byte15 : 120|8@1+ (1.0,0) [0|252] "" FBD_HR
 SG_ TPDiagnosisFlashIPBFBD_HR_Byte16 : 128|8@1+ (1.0,0) [0|252] "" FBD_HR
 SG_ TPDiagnosisFlashIPBFBD_HR_Byte17 : 136|8@1+ (1.0,0) [0|252] "" FBD_HR
 SG_ TPDiagnosisFlashIPBFBD_HR_Byte18 : 144|8@1+ (1.0,0) [0|252] "" FBD_HR
 SG_ TPDiagnosisFlashIPBFBD_HR_Byte19 : 152|8@1+ (1.0,0) [0|252] "" FBD_HR
 SG_ TPDiagnosisFlashIPBFBD_HR_Byte20 : 160|8@1+ (1.0,0) [0|252] "" FBD_HR
 SG_ TPDiagnosisFlashIPBFBD_HR_Byte21 : 168|8@1+ (1.0,0) [0|252] "" FBD_HR
 SG_ TPDiagnosisFlashIPBFBD_HR_Byte22 : 176|8@1+ (1.0,0) [0|252] "" FBD_HR
 SG_ TPDiagnosisFlashIPBFBD_HR_Byte23 : 184|8@1+ (1.0,0) [0|252] "" FBD_HR
 SG_ TPDiagnosisFlashIPBFBD_HR_Byte24 : 192|8@1+ (1.0,0) [0|252] "" FBD_HR
 SG_ TPDiagnosisFlashIPBFBD_HR_Byte25 : 200|8@1+ (1.0,0) [0|252] "" FBD_HR
 SG_ TPDiagnosisFlashIPBFBD_HR_Byte26 : 208|8@1+ (1.0,0) [0|252] "" FBD_HR
 SG_ TPDiagnosisFlashIPBFBD_HR_Byte27 : 216|8@1+ (1.0,0) [0|252] "" FBD_HR
 SG_ TPDiagnosisFlashIPBFBD_HR_Byte28 : 224|8@1+ (1.0,0) [0|252] "" FBD_HR
 SG_ TPDiagnosisFlashIPBFBD_HR_Byte29 : 232|8@1+ (1.0,0) [0|252] "" FBD_HR
 SG_ TPDiagnosisFlashIPBFBD_HR_Byte30 : 240|8@1+ (1.0,0) [0|252] "" FBD_HR
 SG_ TPDiagnosisFlashIPBFBD_HR_Byte31 : 248|8@1+ (1.0,0) [0|252] "" FBD_HR
 SG_ TPDiagnosisFlashIPBFBD_HR_Byte32 : 256|8@1+ (1.0,0) [0|252] "" FBD_HR
 SG_ TPDiagnosisFlashIPBFBD_HR_Byte33 : 264|8@1+ (1.0,0) [0|252] "" FBD_HR
 SG_ TPDiagnosisFlashIPBFBD_HR_Byte34 : 272|8@1+ (1.0,0) [0|252] "" FBD_HR
 SG_ TPDiagnosisFlashIPBFBD_HR_Byte35 : 280|8@1+ (1.0,0) [0|252] "" FBD_HR
 SG_ TPDiagnosisFlashIPBFBD_HR_Byte36 : 288|8@1+ (1.0,0) [0|252] "" FBD_HR
 SG_ TPDiagnosisFlashIPBFBD_HR_Byte37 : 296|8@1+ (1.0,0) [0|252] "" FBD_HR
 SG_ TPDiagnosisFlashIPBFBD_HR_Byte38 : 304|8@1+ (1.0,0) [0|252] "" FBD_HR
 SG_ TPDiagnosisFlashIPBFBD_HR_Byte39 : 312|8@1+ (1.0,0) [0|252] "" FBD_HR
 SG_ TPDiagnosisFlashIPBFBD_HR_Byte40 : 320|8@1+ (1.0,0) [0|252] "" FBD_HR
 SG_ TPDiagnosisFlashIPBFBD_HR_Byte41 : 328|8@1+ (1.0,0) [0|252] "" FBD_HR
 SG_ TPDiagnosisFlashIPBFBD_HR_Byte42 : 336|8@1+ (1.0,0) [0|252] "" FBD_HR
 SG_ TPDiagnosisFlashIPBFBD_HR_Byte43 : 344|8@1+ (1.0,0) [0|252] "" FBD_HR
 SG_ TPDiagnosisFlashIPBFBD_HR_Byte44 : 352|8@1+ (1.0,0) [0|252] "" FBD_HR
 SG_ TPDiagnosisFlashIPBFBD_HR_Byte45 : 360|8@1+ (1.0,0) [0|252] "" FBD_HR
 SG_ TPDiagnosisFlashIPBFBD_HR_Byte46 : 368|8@1+ (1.0,0) [0|252] "" FBD_HR
 SG_ TPDiagnosisFlashIPBFBD_HR_Byte47 : 376|8@1+ (1.0,0) [0|252] "" FBD_HR
 SG_ TPDiagnosisFlashIPBFBD_HR_Byte48 : 384|8@1+ (1.0,0) [0|252] "" FBD_HR
 SG_ TPDiagnosisFlashIPBFBD_HR_Byte49 : 392|8@1+ (1.0,0) [0|252] "" FBD_HR
 SG_ TPDiagnosisFlashIPBFBD_HR_Byte50 : 400|8@1+ (1.0,0) [0|252] "" FBD_HR
 SG_ TPDiagnosisFlashIPBFBD_HR_Byte51 : 408|8@1+ (1.0,0) [0|252] "" FBD_HR
 SG_ TPDiagnosisFlashIPBFBD_HR_Byte52 : 416|8@1+ (1.0,0) [0|252] "" FBD_HR
 SG_ TPDiagnosisFlashIPBFBD_HR_Byte53 : 424|8@1+ (1.0,0) [0|252] "" FBD_HR
 SG_ TPDiagnosisFlashIPBFBD_HR_Byte54 : 432|8@1+ (1.0,0) [0|252] "" FBD_HR
 SG_ TPDiagnosisFlashIPBFBD_HR_Byte55 : 440|8@1+ (1.0,0) [0|252] "" FBD_HR
 SG_ TPDiagnosisFlashIPBFBD_HR_Byte56 : 448|8@1+ (1.0,0) [0|252] "" FBD_HR
 SG_ TPDiagnosisFlashIPBFBD_HR_Byte57 : 456|8@1+ (1.0,0) [0|252] "" FBD_HR
 SG_ TPDiagnosisFlashIPBFBD_HR_Byte58 : 464|8@1+ (1.0,0) [0|252] "" FBD_HR
 SG_ TPDiagnosisFlashIPBFBD_HR_Byte59 : 472|8@1+ (1.0,0) [0|252] "" FBD_HR
 SG_ TPDiagnosisFlashIPBFBD_HR_Byte60 : 480|8@1+ (1.0,0) [0|252] "" FBD_HR
 SG_ TPDiagnosisFlashIPBFBD_HR_Byte61 : 488|8@1+ (1.0,0) [0|252] "" FBD_HR
 SG_ TPDiagnosisFlashIPBFBD_HR_Byte62 : 496|8@1+ (1.0,0) [0|252] "" FBD_HR
 SG_ TPDiagnosisFlashIPBFBD_HR_Byte63 : 504|8@1+ (1.0,0) [0|252] "" FBD_HR

BO_ 702 TPDiagnosisFlash_IPB_FBD_Miko: 64 IPB_App1
 SG_ TPDiagnosisFlashIPBFBD_Miko_Byte : 0|8@1+ (1.0,0) [0|252] "" FBD_Miko
 SG_ TPDiagnosisFlashIPBFBD_Miko_By_2 : 8|8@1+ (1.0,0) [0|252] "" FBD_Miko
 SG_ TPDiagnosisFlashIPBFBD_Miko_By_3 : 16|8@1+ (1.0,0) [0|252] "" FBD_Miko
 SG_ TPDiagnosisFlashIPBFBD_Miko_By_4 : 24|8@1+ (1.0,0) [0|252] "" FBD_Miko
 SG_ TPDiagnosisFlashIPBFBD_Miko_By_5 : 32|8@1+ (1.0,0) [0|252] "" FBD_Miko
 SG_ TPDiagnosisFlashIPBFBD_Miko_By_6 : 40|8@1+ (1.0,0) [0|252] "" FBD_Miko
 SG_ TPDiagnosisFlashIPBFBD_Miko_By_7 : 48|8@1+ (1.0,0) [0|252] "" FBD_Miko
 SG_ TPDiagnosisFlashIPBFBD_Miko_By_8 : 56|8@1+ (1.0,0) [0|252] "" FBD_Miko
 SG_ TPDiagnosisFlashIPBFBD_Miko_By_9 : 64|8@1+ (1.0,0) [0|252] "" FBD_Miko
 SG_ TPDiagnosisFlashIPBFBD_Miko_B_10 : 72|8@1+ (1.0,0) [0|252] "" FBD_Miko
 SG_ TPDiagnosisFlashIPBFBD_Miko_B_11 : 80|8@1+ (1.0,0) [0|252] "" FBD_Miko
 SG_ TPDiagnosisFlashIPBFBD_Miko_B_12 : 88|8@1+ (1.0,0) [0|252] "" FBD_Miko
 SG_ TPDiagnosisFlashIPBFBD_Miko_B_13 : 96|8@1+ (1.0,0) [0|252] "" FBD_Miko
 SG_ TPDiagnosisFlashIPBFBD_Miko_B_14 : 104|8@1+ (1.0,0) [0|252] "" FBD_Miko
 SG_ TPDiagnosisFlashIPBFBD_Miko_B_15 : 112|8@1+ (1.0,0) [0|252] "" FBD_Miko
 SG_ TPDiagnosisFlashIPBFBD_Miko_B_16 : 120|8@1+ (1.0,0) [0|252] "" FBD_Miko
 SG_ TPDiagnosisFlashIPBFBD_Miko_B_17 : 128|8@1+ (1.0,0) [0|252] "" FBD_Miko
 SG_ TPDiagnosisFlashIPBFBD_Miko_B_18 : 136|8@1+ (1.0,0) [0|252] "" FBD_Miko
 SG_ TPDiagnosisFlashIPBFBD_Miko_B_19 : 144|8@1+ (1.0,0) [0|252] "" FBD_Miko
 SG_ TPDiagnosisFlashIPBFBD_Miko_B_20 : 152|8@1+ (1.0,0) [0|252] "" FBD_Miko
 SG_ TPDiagnosisFlashIPBFBD_Miko_B_21 : 160|8@1+ (1.0,0) [0|252] "" FBD_Miko
 SG_ TPDiagnosisFlashIPBFBD_Miko_B_22 : 168|8@1+ (1.0,0) [0|252] "" FBD_Miko
 SG_ TPDiagnosisFlashIPBFBD_Miko_B_23 : 176|8@1+ (1.0,0) [0|252] "" FBD_Miko
 SG_ TPDiagnosisFlashIPBFBD_Miko_B_24 : 184|8@1+ (1.0,0) [0|252] "" FBD_Miko
 SG_ TPDiagnosisFlashIPBFBD_Miko_B_25 : 192|8@1+ (1.0,0) [0|252] "" FBD_Miko
 SG_ TPDiagnosisFlashIPBFBD_Miko_B_26 : 200|8@1+ (1.0,0) [0|252] "" FBD_Miko
 SG_ TPDiagnosisFlashIPBFBD_Miko_B_27 : 208|8@1+ (1.0,0) [0|252] "" FBD_Miko
 SG_ TPDiagnosisFlashIPBFBD_Miko_B_28 : 216|8@1+ (1.0,0) [0|252] "" FBD_Miko
 SG_ TPDiagnosisFlashIPBFBD_Miko_B_29 : 224|8@1+ (1.0,0) [0|252] "" FBD_Miko
 SG_ TPDiagnosisFlashIPBFBD_Miko_B_30 : 232|8@1+ (1.0,0) [0|252] "" FBD_Miko
 SG_ TPDiagnosisFlashIPBFBD_Miko_B_31 : 240|8@1+ (1.0,0) [0|252] "" FBD_Miko
 SG_ TPDiagnosisFlashIPBFBD_Miko_B_32 : 248|8@1+ (1.0,0) [0|252] "" FBD_Miko
 SG_ TPDiagnosisFlashIPBFBD_Miko_B_33 : 256|8@1+ (1.0,0) [0|252] "" FBD_Miko
 SG_ TPDiagnosisFlashIPBFBD_Miko_B_34 : 264|8@1+ (1.0,0) [0|252] "" FBD_Miko
 SG_ TPDiagnosisFlashIPBFBD_Miko_B_35 : 272|8@1+ (1.0,0) [0|252] "" FBD_Miko
 SG_ TPDiagnosisFlashIPBFBD_Miko_B_36 : 280|8@1+ (1.0,0) [0|252] "" FBD_Miko
 SG_ TPDiagnosisFlashIPBFBD_Miko_B_37 : 288|8@1+ (1.0,0) [0|252] "" FBD_Miko
 SG_ TPDiagnosisFlashIPBFBD_Miko_B_38 : 296|8@1+ (1.0,0) [0|252] "" FBD_Miko
 SG_ TPDiagnosisFlashIPBFBD_Miko_B_39 : 304|8@1+ (1.0,0) [0|252] "" FBD_Miko
 SG_ TPDiagnosisFlashIPBFBD_Miko_B_40 : 312|8@1+ (1.0,0) [0|252] "" FBD_Miko
 SG_ TPDiagnosisFlashIPBFBD_Miko_B_41 : 320|8@1+ (1.0,0) [0|252] "" FBD_Miko
 SG_ TPDiagnosisFlashIPBFBD_Miko_B_42 : 328|8@1+ (1.0,0) [0|252] "" FBD_Miko
 SG_ TPDiagnosisFlashIPBFBD_Miko_B_43 : 336|8@1+ (1.0,0) [0|252] "" FBD_Miko
 SG_ TPDiagnosisFlashIPBFBD_Miko_B_44 : 344|8@1+ (1.0,0) [0|252] "" FBD_Miko
 SG_ TPDiagnosisFlashIPBFBD_Miko_B_45 : 352|8@1+ (1.0,0) [0|252] "" FBD_Miko
 SG_ TPDiagnosisFlashIPBFBD_Miko_B_46 : 360|8@1+ (1.0,0) [0|252] "" FBD_Miko
 SG_ TPDiagnosisFlashIPBFBD_Miko_B_47 : 368|8@1+ (1.0,0) [0|252] "" FBD_Miko
 SG_ TPDiagnosisFlashIPBFBD_Miko_B_48 : 376|8@1+ (1.0,0) [0|252] "" FBD_Miko
 SG_ TPDiagnosisFlashIPBFBD_Miko_B_49 : 384|8@1+ (1.0,0) [0|252] "" FBD_Miko
 SG_ TPDiagnosisFlashIPBFBD_Miko_B_50 : 392|8@1+ (1.0,0) [0|252] "" FBD_Miko
 SG_ TPDiagnosisFlashIPBFBD_Miko_B_51 : 400|8@1+ (1.0,0) [0|252] "" FBD_Miko
 SG_ TPDiagnosisFlashIPBFBD_Miko_B_52 : 408|8@1+ (1.0,0) [0|252] "" FBD_Miko
 SG_ TPDiagnosisFlashIPBFBD_Miko_B_53 : 416|8@1+ (1.0,0) [0|252] "" FBD_Miko
 SG_ TPDiagnosisFlashIPBFBD_Miko_B_54 : 424|8@1+ (1.0,0) [0|252] "" FBD_Miko
 SG_ TPDiagnosisFlashIPBFBD_Miko_B_55 : 432|8@1+ (1.0,0) [0|252] "" FBD_Miko
 SG_ TPDiagnosisFlashIPBFBD_Miko_B_56 : 440|8@1+ (1.0,0) [0|252] "" FBD_Miko
 SG_ TPDiagnosisFlashIPBFBD_Miko_B_57 : 448|8@1+ (1.0,0) [0|252] "" FBD_Miko
 SG_ TPDiagnosisFlashIPBFBD_Miko_B_58 : 456|8@1+ (1.0,0) [0|252] "" FBD_Miko
 SG_ TPDiagnosisFlashIPBFBD_Miko_B_59 : 464|8@1+ (1.0,0) [0|252] "" FBD_Miko
 SG_ TPDiagnosisFlashIPBFBD_Miko_B_60 : 472|8@1+ (1.0,0) [0|252] "" FBD_Miko
 SG_ TPDiagnosisFlashIPBFBD_Miko_B_61 : 480|8@1+ (1.0,0) [0|252] "" FBD_Miko
 SG_ TPDiagnosisFlashIPBFBD_Miko_B_62 : 488|8@1+ (1.0,0) [0|252] "" FBD_Miko
 SG_ TPDiagnosisFlashIPBFBD_Miko_B_63 : 496|8@1+ (1.0,0) [0|252] "" FBD_Miko
 SG_ TPDiagnosisFlashIPBFBD_Miko_B_64 : 504|8@1+ (1.0,0) [0|252] "" FBD_Miko

BO_ 871 TPDiagnosisFlash_IPB_FBD_MM: 64 IPB_App1
 SG_ TPDiagnosisFlashIPBFBD_MM_Byte00 : 0|8@1+ (1.0,0) [0|252] "" FBD_MM
 SG_ TPDiagnosisFlashIPBFBD_MM_Byte01 : 8|8@1+ (1.0,0) [0|252] "" FBD_MM
 SG_ TPDiagnosisFlashIPBFBD_MM_Byte02 : 16|8@1+ (1.0,0) [0|252] "" FBD_MM
 SG_ TPDiagnosisFlashIPBFBD_MM_Byte03 : 24|8@1+ (1.0,0) [0|252] "" FBD_MM
 SG_ TPDiagnosisFlashIPBFBD_MM_Byte04 : 32|8@1+ (1.0,0) [0|252] "" FBD_MM
 SG_ TPDiagnosisFlashIPBFBD_MM_Byte05 : 40|8@1+ (1.0,0) [0|252] "" FBD_MM
 SG_ TPDiagnosisFlashIPBFBD_MM_Byte06 : 48|8@1+ (1.0,0) [0|252] "" FBD_MM
 SG_ TPDiagnosisFlashIPBFBD_MM_Byte07 : 56|8@1+ (1.0,0) [0|252] "" FBD_MM
 SG_ TPDiagnosisFlashIPBFBD_MM_Byte08 : 64|8@1+ (1.0,0) [0|252] "" FBD_MM
 SG_ TPDiagnosisFlashIPBFBD_MM_Byte09 : 72|8@1+ (1.0,0) [0|252] "" FBD_MM
 SG_ TPDiagnosisFlashIPBFBD_MM_Byte10 : 80|8@1+ (1.0,0) [0|252] "" FBD_MM
 SG_ TPDiagnosisFlashIPBFBD_MM_Byte11 : 88|8@1+ (1.0,0) [0|252] "" FBD_MM
 SG_ TPDiagnosisFlashIPBFBD_MM_Byte12 : 96|8@1+ (1.0,0) [0|252] "" FBD_MM
 SG_ TPDiagnosisFlashIPBFBD_MM_Byte13 : 104|8@1+ (1.0,0) [0|252] "" FBD_MM
 SG_ TPDiagnosisFlashIPBFBD_MM_Byte14 : 112|8@1+ (1.0,0) [0|252] "" FBD_MM
 SG_ TPDiagnosisFlashIPBFBD_MM_Byte15 : 120|8@1+ (1.0,0) [0|252] "" FBD_MM
 SG_ TPDiagnosisFlashIPBFBD_MM_Byte16 : 128|8@1+ (1.0,0) [0|252] "" FBD_MM
 SG_ TPDiagnosisFlashIPBFBD_MM_Byte17 : 136|8@1+ (1.0,0) [0|252] "" FBD_MM
 SG_ TPDiagnosisFlashIPBFBD_MM_Byte18 : 144|8@1+ (1.0,0) [0|252] "" FBD_MM
 SG_ TPDiagnosisFlashIPBFBD_MM_Byte19 : 152|8@1+ (1.0,0) [0|252] "" FBD_MM
 SG_ TPDiagnosisFlashIPBFBD_MM_Byte20 : 160|8@1+ (1.0,0) [0|252] "" FBD_MM
 SG_ TPDiagnosisFlashIPBFBD_MM_Byte21 : 168|8@1+ (1.0,0) [0|252] "" FBD_MM
 SG_ TPDiagnosisFlashIPBFBD_MM_Byte22 : 176|8@1+ (1.0,0) [0|252] "" FBD_MM
 SG_ TPDiagnosisFlashIPBFBD_MM_Byte23 : 184|8@1+ (1.0,0) [0|252] "" FBD_MM
 SG_ TPDiagnosisFlashIPBFBD_MM_Byte24 : 192|8@1+ (1.0,0) [0|252] "" FBD_MM
 SG_ TPDiagnosisFlashIPBFBD_MM_Byte25 : 200|8@1+ (1.0,0) [0|252] "" FBD_MM
 SG_ TPDiagnosisFlashIPBFBD_MM_Byte26 : 208|8@1+ (1.0,0) [0|252] "" FBD_MM
 SG_ TPDiagnosisFlashIPBFBD_MM_Byte27 : 216|8@1+ (1.0,0) [0|252] "" FBD_MM
 SG_ TPDiagnosisFlashIPBFBD_MM_Byte28 : 224|8@1+ (1.0,0) [0|252] "" FBD_MM
 SG_ TPDiagnosisFlashIPBFBD_MM_Byte29 : 232|8@1+ (1.0,0) [0|252] "" FBD_MM
 SG_ TPDiagnosisFlashIPBFBD_MM_Byte30 : 240|8@1+ (1.0,0) [0|252] "" FBD_MM
 SG_ TPDiagnosisFlashIPBFBD_MM_Byte31 : 248|8@1+ (1.0,0) [0|252] "" FBD_MM
 SG_ TPDiagnosisFlashIPBFBD_MM_Byte32 : 256|8@1+ (1.0,0) [0|252] "" FBD_MM
 SG_ TPDiagnosisFlashIPBFBD_MM_Byte33 : 264|8@1+ (1.0,0) [0|252] "" FBD_MM
 SG_ TPDiagnosisFlashIPBFBD_MM_Byte34 : 272|8@1+ (1.0,0) [0|252] "" FBD_MM
 SG_ TPDiagnosisFlashIPBFBD_MM_Byte35 : 280|8@1+ (1.0,0) [0|252] "" FBD_MM
 SG_ TPDiagnosisFlashIPBFBD_MM_Byte36 : 288|8@1+ (1.0,0) [0|252] "" FBD_MM
 SG_ TPDiagnosisFlashIPBFBD_MM_Byte37 : 296|8@1+ (1.0,0) [0|252] "" FBD_MM
 SG_ TPDiagnosisFlashIPBFBD_MM_Byte38 : 304|8@1+ (1.0,0) [0|252] "" FBD_MM
 SG_ TPDiagnosisFlashIPBFBD_MM_Byte39 : 312|8@1+ (1.0,0) [0|252] "" FBD_MM
 SG_ TPDiagnosisFlashIPBFBD_MM_Byte40 : 320|8@1+ (1.0,0) [0|252] "" FBD_MM
 SG_ TPDiagnosisFlashIPBFBD_MM_Byte41 : 328|8@1+ (1.0,0) [0|252] "" FBD_MM
 SG_ TPDiagnosisFlashIPBFBD_MM_Byte42 : 336|8@1+ (1.0,0) [0|252] "" FBD_MM
 SG_ TPDiagnosisFlashIPBFBD_MM_Byte43 : 344|8@1+ (1.0,0) [0|252] "" FBD_MM
 SG_ TPDiagnosisFlashIPBFBD_MM_Byte44 : 352|8@1+ (1.0,0) [0|252] "" FBD_MM
 SG_ TPDiagnosisFlashIPBFBD_MM_Byte45 : 360|8@1+ (1.0,0) [0|252] "" FBD_MM
 SG_ TPDiagnosisFlashIPBFBD_MM_Byte46 : 368|8@1+ (1.0,0) [0|252] "" FBD_MM
 SG_ TPDiagnosisFlashIPBFBD_MM_Byte47 : 376|8@1+ (1.0,0) [0|252] "" FBD_MM
 SG_ TPDiagnosisFlashIPBFBD_MM_Byte48 : 384|8@1+ (1.0,0) [0|252] "" FBD_MM
 SG_ TPDiagnosisFlashIPBFBD_MM_Byte49 : 392|8@1+ (1.0,0) [0|252] "" FBD_MM
 SG_ TPDiagnosisFlashIPBFBD_MM_Byte50 : 400|8@1+ (1.0,0) [0|252] "" FBD_MM
 SG_ TPDiagnosisFlashIPBFBD_MM_Byte51 : 408|8@1+ (1.0,0) [0|252] "" FBD_MM
 SG_ TPDiagnosisFlashIPBFBD_MM_Byte52 : 416|8@1+ (1.0,0) [0|252] "" FBD_MM
 SG_ TPDiagnosisFlashIPBFBD_MM_Byte53 : 424|8@1+ (1.0,0) [0|252] "" FBD_MM
 SG_ TPDiagnosisFlashIPBFBD_MM_Byte54 : 432|8@1+ (1.0,0) [0|252] "" FBD_MM
 SG_ TPDiagnosisFlashIPBFBD_MM_Byte55 : 440|8@1+ (1.0,0) [0|252] "" FBD_MM
 SG_ TPDiagnosisFlashIPBFBD_MM_Byte56 : 448|8@1+ (1.0,0) [0|252] "" FBD_MM
 SG_ TPDiagnosisFlashIPBFBD_MM_Byte57 : 456|8@1+ (1.0,0) [0|252] "" FBD_MM
 SG_ TPDiagnosisFlashIPBFBD_MM_Byte58 : 464|8@1+ (1.0,0) [0|252] "" FBD_MM
 SG_ TPDiagnosisFlashIPBFBD_MM_Byte59 : 472|8@1+ (1.0,0) [0|252] "" FBD_MM
 SG_ TPDiagnosisFlashIPBFBD_MM_Byte60 : 480|8@1+ (1.0,0) [0|252] "" FBD_MM
 SG_ TPDiagnosisFlashIPBFBD_MM_Byte61 : 488|8@1+ (1.0,0) [0|252] "" FBD_MM
 SG_ TPDiagnosisFlashIPBFBD_MM_Byte62 : 496|8@1+ (1.0,0) [0|252] "" FBD_MM
 SG_ TPDiagnosisFlashIPBFBD_MM_Byte63 : 504|8@1+ (1.0,0) [0|252] "" FBD_MM

BO_ 703 TPDiagnosisFlash_IPB_FBD_Trunk: 64 IPB_App1
 SG_ TPDiagnosisFlashIPBFBD_Trunk_Byt : 0|8@1+ (1.0,0) [0|252] "" FBD_Trunk
 SG_ TPDiagnosisFlashIPBFBD_Trunk_B_2 : 8|8@1+ (1.0,0) [0|252] "" FBD_Trunk
 SG_ TPDiagnosisFlashIPBFBD_Trunk_B_3 : 16|8@1+ (1.0,0) [0|252] "" FBD_Trunk
 SG_ TPDiagnosisFlashIPBFBD_Trunk_B_4 : 24|8@1+ (1.0,0) [0|252] "" FBD_Trunk
 SG_ TPDiagnosisFlashIPBFBD_Trunk_B_5 : 32|8@1+ (1.0,0) [0|252] "" FBD_Trunk
 SG_ TPDiagnosisFlashIPBFBD_Trunk_B_6 : 40|8@1+ (1.0,0) [0|252] "" FBD_Trunk
 SG_ TPDiagnosisFlashIPBFBD_Trunk_B_7 : 48|8@1+ (1.0,0) [0|252] "" FBD_Trunk
 SG_ TPDiagnosisFlashIPBFBD_Trunk_B_8 : 56|8@1+ (1.0,0) [0|252] "" FBD_Trunk
 SG_ TPDiagnosisFlashIPBFBD_Trunk_B_9 : 64|8@1+ (1.0,0) [0|252] "" FBD_Trunk
 SG_ TPDiagnosisFlashIPBFBD_Trunk__10 : 72|8@1+ (1.0,0) [0|252] "" FBD_Trunk
 SG_ TPDiagnosisFlashIPBFBD_Trunk__11 : 80|8@1+ (1.0,0) [0|252] "" FBD_Trunk
 SG_ TPDiagnosisFlashIPBFBD_Trunk__12 : 88|8@1+ (1.0,0) [0|252] "" FBD_Trunk
 SG_ TPDiagnosisFlashIPBFBD_Trunk__13 : 96|8@1+ (1.0,0) [0|252] "" FBD_Trunk
 SG_ TPDiagnosisFlashIPBFBD_Trunk__14 : 104|8@1+ (1.0,0) [0|252] "" FBD_Trunk
 SG_ TPDiagnosisFlashIPBFBD_Trunk__15 : 112|8@1+ (1.0,0) [0|252] "" FBD_Trunk
 SG_ TPDiagnosisFlashIPBFBD_Trunk__16 : 120|8@1+ (1.0,0) [0|252] "" FBD_Trunk
 SG_ TPDiagnosisFlashIPBFBD_Trunk__17 : 128|8@1+ (1.0,0) [0|252] "" FBD_Trunk
 SG_ TPDiagnosisFlashIPBFBD_Trunk__18 : 136|8@1+ (1.0,0) [0|252] "" FBD_Trunk
 SG_ TPDiagnosisFlashIPBFBD_Trunk__19 : 144|8@1+ (1.0,0) [0|252] "" FBD_Trunk
 SG_ TPDiagnosisFlashIPBFBD_Trunk__20 : 152|8@1+ (1.0,0) [0|252] "" FBD_Trunk
 SG_ TPDiagnosisFlashIPBFBD_Trunk__21 : 160|8@1+ (1.0,0) [0|252] "" FBD_Trunk
 SG_ TPDiagnosisFlashIPBFBD_Trunk__22 : 168|8@1+ (1.0,0) [0|252] "" FBD_Trunk
 SG_ TPDiagnosisFlashIPBFBD_Trunk__23 : 176|8@1+ (1.0,0) [0|252] "" FBD_Trunk
 SG_ TPDiagnosisFlashIPBFBD_Trunk__24 : 184|8@1+ (1.0,0) [0|252] "" FBD_Trunk
 SG_ TPDiagnosisFlashIPBFBD_Trunk__25 : 192|8@1+ (1.0,0) [0|252] "" FBD_Trunk
 SG_ TPDiagnosisFlashIPBFBD_Trunk__26 : 200|8@1+ (1.0,0) [0|252] "" FBD_Trunk
 SG_ TPDiagnosisFlashIPBFBD_Trunk__27 : 208|8@1+ (1.0,0) [0|252] "" FBD_Trunk
 SG_ TPDiagnosisFlashIPBFBD_Trunk__28 : 216|8@1+ (1.0,0) [0|252] "" FBD_Trunk
 SG_ TPDiagnosisFlashIPBFBD_Trunk__29 : 224|8@1+ (1.0,0) [0|252] "" FBD_Trunk
 SG_ TPDiagnosisFlashIPBFBD_Trunk__30 : 232|8@1+ (1.0,0) [0|252] "" FBD_Trunk
 SG_ TPDiagnosisFlashIPBFBD_Trunk__31 : 240|8@1+ (1.0,0) [0|252] "" FBD_Trunk
 SG_ TPDiagnosisFlashIPBFBD_Trunk__32 : 248|8@1+ (1.0,0) [0|252] "" FBD_Trunk
 SG_ TPDiagnosisFlashIPBFBD_Trunk__33 : 256|8@1+ (1.0,0) [0|252] "" FBD_Trunk
 SG_ TPDiagnosisFlashIPBFBD_Trunk__34 : 264|8@1+ (1.0,0) [0|252] "" FBD_Trunk
 SG_ TPDiagnosisFlashIPBFBD_Trunk__35 : 272|8@1+ (1.0,0) [0|252] "" FBD_Trunk
 SG_ TPDiagnosisFlashIPBFBD_Trunk__36 : 280|8@1+ (1.0,0) [0|252] "" FBD_Trunk
 SG_ TPDiagnosisFlashIPBFBD_Trunk__37 : 288|8@1+ (1.0,0) [0|252] "" FBD_Trunk
 SG_ TPDiagnosisFlashIPBFBD_Trunk__38 : 296|8@1+ (1.0,0) [0|252] "" FBD_Trunk
 SG_ TPDiagnosisFlashIPBFBD_Trunk__39 : 304|8@1+ (1.0,0) [0|252] "" FBD_Trunk
 SG_ TPDiagnosisFlashIPBFBD_Trunk__40 : 312|8@1+ (1.0,0) [0|252] "" FBD_Trunk
 SG_ TPDiagnosisFlashIPBFBD_Trunk__41 : 320|8@1+ (1.0,0) [0|252] "" FBD_Trunk
 SG_ TPDiagnosisFlashIPBFBD_Trunk__42 : 328|8@1+ (1.0,0) [0|252] "" FBD_Trunk
 SG_ TPDiagnosisFlashIPBFBD_Trunk__43 : 336|8@1+ (1.0,0) [0|252] "" FBD_Trunk
 SG_ TPDiagnosisFlashIPBFBD_Trunk__44 : 344|8@1+ (1.0,0) [0|252] "" FBD_Trunk
 SG_ TPDiagnosisFlashIPBFBD_Trunk__45 : 352|8@1+ (1.0,0) [0|252] "" FBD_Trunk
 SG_ TPDiagnosisFlashIPBFBD_Trunk__46 : 360|8@1+ (1.0,0) [0|252] "" FBD_Trunk
 SG_ TPDiagnosisFlashIPBFBD_Trunk__47 : 368|8@1+ (1.0,0) [0|252] "" FBD_Trunk
 SG_ TPDiagnosisFlashIPBFBD_Trunk__48 : 376|8@1+ (1.0,0) [0|252] "" FBD_Trunk
 SG_ TPDiagnosisFlashIPBFBD_Trunk__49 : 384|8@1+ (1.0,0) [0|252] "" FBD_Trunk
 SG_ TPDiagnosisFlashIPBFBD_Trunk__50 : 392|8@1+ (1.0,0) [0|252] "" FBD_Trunk
 SG_ TPDiagnosisFlashIPBFBD_Trunk__51 : 400|8@1+ (1.0,0) [0|252] "" FBD_Trunk
 SG_ TPDiagnosisFlashIPBFBD_Trunk__52 : 408|8@1+ (1.0,0) [0|252] "" FBD_Trunk
 SG_ TPDiagnosisFlashIPBFBD_Trunk__53 : 416|8@1+ (1.0,0) [0|252] "" FBD_Trunk
 SG_ TPDiagnosisFlashIPBFBD_Trunk__54 : 424|8@1+ (1.0,0) [0|252] "" FBD_Trunk
 SG_ TPDiagnosisFlashIPBFBD_Trunk__55 : 432|8@1+ (1.0,0) [0|252] "" FBD_Trunk
 SG_ TPDiagnosisFlashIPBFBD_Trunk__56 : 440|8@1+ (1.0,0) [0|252] "" FBD_Trunk
 SG_ TPDiagnosisFlashIPBFBD_Trunk__57 : 448|8@1+ (1.0,0) [0|252] "" FBD_Trunk
 SG_ TPDiagnosisFlashIPBFBD_Trunk__58 : 456|8@1+ (1.0,0) [0|252] "" FBD_Trunk
 SG_ TPDiagnosisFlashIPBFBD_Trunk__59 : 464|8@1+ (1.0,0) [0|252] "" FBD_Trunk
 SG_ TPDiagnosisFlashIPBFBD_Trunk__60 : 472|8@1+ (1.0,0) [0|252] "" FBD_Trunk
 SG_ TPDiagnosisFlashIPBFBD_Trunk__61 : 480|8@1+ (1.0,0) [0|252] "" FBD_Trunk
 SG_ TPDiagnosisFlashIPBFBD_Trunk__62 : 488|8@1+ (1.0,0) [0|252] "" FBD_Trunk
 SG_ TPDiagnosisFlashIPBFBD_Trunk__63 : 496|8@1+ (1.0,0) [0|252] "" FBD_Trunk
 SG_ TPDiagnosisFlashIPBFBD_Trunk__64 : 504|8@1+ (1.0,0) [0|252] "" FBD_Trunk

BO_ 704 TPDiagnosisFlash_IPB_FBD_VL: 64 IPB_App1
 SG_ TPDiagnosisFlashIPBFBD_VL_Byte00 : 0|8@1+ (1.0,0) [0|252] "" FBD_VL
 SG_ TPDiagnosisFlashIPBFBD_VL_Byte01 : 8|8@1+ (1.0,0) [0|252] "" FBD_VL
 SG_ TPDiagnosisFlashIPBFBD_VL_Byte02 : 16|8@1+ (1.0,0) [0|252] "" FBD_VL
 SG_ TPDiagnosisFlashIPBFBD_VL_Byte03 : 24|8@1+ (1.0,0) [0|252] "" FBD_VL
 SG_ TPDiagnosisFlashIPBFBD_VL_Byte04 : 32|8@1+ (1.0,0) [0|252] "" FBD_VL
 SG_ TPDiagnosisFlashIPBFBD_VL_Byte05 : 40|8@1+ (1.0,0) [0|252] "" FBD_VL
 SG_ TPDiagnosisFlashIPBFBD_VL_Byte06 : 48|8@1+ (1.0,0) [0|252] "" FBD_VL
 SG_ TPDiagnosisFlashIPBFBD_VL_Byte07 : 56|8@1+ (1.0,0) [0|252] "" FBD_VL
 SG_ TPDiagnosisFlashIPBFBD_VL_Byte08 : 64|8@1+ (1.0,0) [0|252] "" FBD_VL
 SG_ TPDiagnosisFlashIPBFBD_VL_Byte09 : 72|8@1+ (1.0,0) [0|252] "" FBD_VL
 SG_ TPDiagnosisFlashIPBFBD_VL_Byte10 : 80|8@1+ (1.0,0) [0|252] "" FBD_VL
 SG_ TPDiagnosisFlashIPBFBD_VL_Byte11 : 88|8@1+ (1.0,0) [0|252] "" FBD_VL
 SG_ TPDiagnosisFlashIPBFBD_VL_Byte12 : 96|8@1+ (1.0,0) [0|252] "" FBD_VL
 SG_ TPDiagnosisFlashIPBFBD_VL_Byte13 : 104|8@1+ (1.0,0) [0|252] "" FBD_VL
 SG_ TPDiagnosisFlashIPBFBD_VL_Byte14 : 112|8@1+ (1.0,0) [0|252] "" FBD_VL
 SG_ TPDiagnosisFlashIPBFBD_VL_Byte15 : 120|8@1+ (1.0,0) [0|252] "" FBD_VL
 SG_ TPDiagnosisFlashIPBFBD_VL_Byte16 : 128|8@1+ (1.0,0) [0|252] "" FBD_VL
 SG_ TPDiagnosisFlashIPBFBD_VL_Byte17 : 136|8@1+ (1.0,0) [0|252] "" FBD_VL
 SG_ TPDiagnosisFlashIPBFBD_VL_Byte18 : 144|8@1+ (1.0,0) [0|252] "" FBD_VL
 SG_ TPDiagnosisFlashIPBFBD_VL_Byte19 : 152|8@1+ (1.0,0) [0|252] "" FBD_VL
 SG_ TPDiagnosisFlashIPBFBD_VL_Byte20 : 160|8@1+ (1.0,0) [0|252] "" FBD_VL
 SG_ TPDiagnosisFlashIPBFBD_VL_Byte21 : 168|8@1+ (1.0,0) [0|252] "" FBD_VL
 SG_ TPDiagnosisFlashIPBFBD_VL_Byte22 : 176|8@1+ (1.0,0) [0|252] "" FBD_VL
 SG_ TPDiagnosisFlashIPBFBD_VL_Byte23 : 184|8@1+ (1.0,0) [0|252] "" FBD_VL
 SG_ TPDiagnosisFlashIPBFBD_VL_Byte24 : 192|8@1+ (1.0,0) [0|252] "" FBD_VL
 SG_ TPDiagnosisFlashIPBFBD_VL_Byte25 : 200|8@1+ (1.0,0) [0|252] "" FBD_VL
 SG_ TPDiagnosisFlashIPBFBD_VL_Byte26 : 208|8@1+ (1.0,0) [0|252] "" FBD_VL
 SG_ TPDiagnosisFlashIPBFBD_VL_Byte27 : 216|8@1+ (1.0,0) [0|252] "" FBD_VL
 SG_ TPDiagnosisFlashIPBFBD_VL_Byte28 : 224|8@1+ (1.0,0) [0|252] "" FBD_VL
 SG_ TPDiagnosisFlashIPBFBD_VL_Byte29 : 232|8@1+ (1.0,0) [0|252] "" FBD_VL
 SG_ TPDiagnosisFlashIPBFBD_VL_Byte30 : 240|8@1+ (1.0,0) [0|252] "" FBD_VL
 SG_ TPDiagnosisFlashIPBFBD_VL_Byte31 : 248|8@1+ (1.0,0) [0|252] "" FBD_VL
 SG_ TPDiagnosisFlashIPBFBD_VL_Byte32 : 256|8@1+ (1.0,0) [0|252] "" FBD_VL
 SG_ TPDiagnosisFlashIPBFBD_VL_Byte33 : 264|8@1+ (1.0,0) [0|252] "" FBD_VL
 SG_ TPDiagnosisFlashIPBFBD_VL_Byte34 : 272|8@1+ (1.0,0) [0|252] "" FBD_VL
 SG_ TPDiagnosisFlashIPBFBD_VL_Byte35 : 280|8@1+ (1.0,0) [0|252] "" FBD_VL
 SG_ TPDiagnosisFlashIPBFBD_VL_Byte36 : 288|8@1+ (1.0,0) [0|252] "" FBD_VL
 SG_ TPDiagnosisFlashIPBFBD_VL_Byte37 : 296|8@1+ (1.0,0) [0|252] "" FBD_VL
 SG_ TPDiagnosisFlashIPBFBD_VL_Byte38 : 304|8@1+ (1.0,0) [0|252] "" FBD_VL
 SG_ TPDiagnosisFlashIPBFBD_VL_Byte39 : 312|8@1+ (1.0,0) [0|252] "" FBD_VL
 SG_ TPDiagnosisFlashIPBFBD_VL_Byte40 : 320|8@1+ (1.0,0) [0|252] "" FBD_VL
 SG_ TPDiagnosisFlashIPBFBD_VL_Byte41 : 328|8@1+ (1.0,0) [0|252] "" FBD_VL
 SG_ TPDiagnosisFlashIPBFBD_VL_Byte42 : 336|8@1+ (1.0,0) [0|252] "" FBD_VL
 SG_ TPDiagnosisFlashIPBFBD_VL_Byte43 : 344|8@1+ (1.0,0) [0|252] "" FBD_VL
 SG_ TPDiagnosisFlashIPBFBD_VL_Byte44 : 352|8@1+ (1.0,0) [0|252] "" FBD_VL
 SG_ TPDiagnosisFlashIPBFBD_VL_Byte45 : 360|8@1+ (1.0,0) [0|252] "" FBD_VL
 SG_ TPDiagnosisFlashIPBFBD_VL_Byte46 : 368|8@1+ (1.0,0) [0|252] "" FBD_VL
 SG_ TPDiagnosisFlashIPBFBD_VL_Byte47 : 376|8@1+ (1.0,0) [0|252] "" FBD_VL
 SG_ TPDiagnosisFlashIPBFBD_VL_Byte48 : 384|8@1+ (1.0,0) [0|252] "" FBD_VL
 SG_ TPDiagnosisFlashIPBFBD_VL_Byte49 : 392|8@1+ (1.0,0) [0|252] "" FBD_VL
 SG_ TPDiagnosisFlashIPBFBD_VL_Byte50 : 400|8@1+ (1.0,0) [0|252] "" FBD_VL
 SG_ TPDiagnosisFlashIPBFBD_VL_Byte51 : 408|8@1+ (1.0,0) [0|252] "" FBD_VL
 SG_ TPDiagnosisFlashIPBFBD_VL_Byte52 : 416|8@1+ (1.0,0) [0|252] "" FBD_VL
 SG_ TPDiagnosisFlashIPBFBD_VL_Byte53 : 424|8@1+ (1.0,0) [0|252] "" FBD_VL
 SG_ TPDiagnosisFlashIPBFBD_VL_Byte54 : 432|8@1+ (1.0,0) [0|252] "" FBD_VL
 SG_ TPDiagnosisFlashIPBFBD_VL_Byte55 : 440|8@1+ (1.0,0) [0|252] "" FBD_VL
 SG_ TPDiagnosisFlashIPBFBD_VL_Byte56 : 448|8@1+ (1.0,0) [0|252] "" FBD_VL
 SG_ TPDiagnosisFlashIPBFBD_VL_Byte57 : 456|8@1+ (1.0,0) [0|252] "" FBD_VL
 SG_ TPDiagnosisFlashIPBFBD_VL_Byte58 : 464|8@1+ (1.0,0) [0|252] "" FBD_VL
 SG_ TPDiagnosisFlashIPBFBD_VL_Byte59 : 472|8@1+ (1.0,0) [0|252] "" FBD_VL
 SG_ TPDiagnosisFlashIPBFBD_VL_Byte60 : 480|8@1+ (1.0,0) [0|252] "" FBD_VL
 SG_ TPDiagnosisFlashIPBFBD_VL_Byte61 : 488|8@1+ (1.0,0) [0|252] "" FBD_VL
 SG_ TPDiagnosisFlashIPBFBD_VL_Byte62 : 496|8@1+ (1.0,0) [0|252] "" FBD_VL
 SG_ TPDiagnosisFlashIPBFBD_VL_Byte63 : 504|8@1+ (1.0,0) [0|252] "" FBD_VL

BO_ 700 TPDiagnosisFlash_IPB_FBD_VM: 64 IPB_App1
 SG_ TPDiagnosisFlashIPBFBD_VM_Byte00 : 0|8@1+ (1.0,0) [0|252] "" FBD_VM
 SG_ TPDiagnosisFlashIPBFBD_VM_Byte01 : 8|8@1+ (1.0,0) [0|252] "" FBD_VM
 SG_ TPDiagnosisFlashIPBFBD_VM_Byte02 : 16|8@1+ (1.0,0) [0|252] "" FBD_VM
 SG_ TPDiagnosisFlashIPBFBD_VM_Byte03 : 24|8@1+ (1.0,0) [0|252] "" FBD_VM
 SG_ TPDiagnosisFlashIPBFBD_VM_Byte04 : 32|8@1+ (1.0,0) [0|252] "" FBD_VM
 SG_ TPDiagnosisFlashIPBFBD_VM_Byte05 : 40|8@1+ (1.0,0) [0|252] "" FBD_VM
 SG_ TPDiagnosisFlashIPBFBD_VM_Byte06 : 48|8@1+ (1.0,0) [0|252] "" FBD_VM
 SG_ TPDiagnosisFlashIPBFBD_VM_Byte07 : 56|8@1+ (1.0,0) [0|252] "" FBD_VM
 SG_ TPDiagnosisFlashIPBFBD_VM_Byte08 : 64|8@1+ (1.0,0) [0|252] "" FBD_VM
 SG_ TPDiagnosisFlashIPBFBD_VM_Byte09 : 72|8@1+ (1.0,0) [0|252] "" FBD_VM
 SG_ TPDiagnosisFlashIPBFBD_VM_Byte10 : 80|8@1+ (1.0,0) [0|252] "" FBD_VM
 SG_ TPDiagnosisFlashIPBFBD_VM_Byte11 : 88|8@1+ (1.0,0) [0|252] "" FBD_VM
 SG_ TPDiagnosisFlashIPBFBD_VM_Byte12 : 96|8@1+ (1.0,0) [0|252] "" FBD_VM
 SG_ TPDiagnosisFlashIPBFBD_VM_Byte13 : 104|8@1+ (1.0,0) [0|252] "" FBD_VM
 SG_ TPDiagnosisFlashIPBFBD_VM_Byte14 : 112|8@1+ (1.0,0) [0|252] "" FBD_VM
 SG_ TPDiagnosisFlashIPBFBD_VM_Byte15 : 120|8@1+ (1.0,0) [0|252] "" FBD_VM
 SG_ TPDiagnosisFlashIPBFBD_VM_Byte16 : 128|8@1+ (1.0,0) [0|252] "" FBD_VM
 SG_ TPDiagnosisFlashIPBFBD_VM_Byte17 : 136|8@1+ (1.0,0) [0|252] "" FBD_VM
 SG_ TPDiagnosisFlashIPBFBD_VM_Byte18 : 144|8@1+ (1.0,0) [0|252] "" FBD_VM
 SG_ TPDiagnosisFlashIPBFBD_VM_Byte19 : 152|8@1+ (1.0,0) [0|252] "" FBD_VM
 SG_ TPDiagnosisFlashIPBFBD_VM_Byte20 : 160|8@1+ (1.0,0) [0|252] "" FBD_VM
 SG_ TPDiagnosisFlashIPBFBD_VM_Byte21 : 168|8@1+ (1.0,0) [0|252] "" FBD_VM
 SG_ TPDiagnosisFlashIPBFBD_VM_Byte22 : 176|8@1+ (1.0,0) [0|252] "" FBD_VM
 SG_ TPDiagnosisFlashIPBFBD_VM_Byte23 : 184|8@1+ (1.0,0) [0|252] "" FBD_VM
 SG_ TPDiagnosisFlashIPBFBD_VM_Byte24 : 192|8@1+ (1.0,0) [0|252] "" FBD_VM
 SG_ TPDiagnosisFlashIPBFBD_VM_Byte25 : 200|8@1+ (1.0,0) [0|252] "" FBD_VM
 SG_ TPDiagnosisFlashIPBFBD_VM_Byte26 : 208|8@1+ (1.0,0) [0|252] "" FBD_VM
 SG_ TPDiagnosisFlashIPBFBD_VM_Byte27 : 216|8@1+ (1.0,0) [0|252] "" FBD_VM
 SG_ TPDiagnosisFlashIPBFBD_VM_Byte28 : 224|8@1+ (1.0,0) [0|252] "" FBD_VM
 SG_ TPDiagnosisFlashIPBFBD_VM_Byte29 : 232|8@1+ (1.0,0) [0|252] "" FBD_VM
 SG_ TPDiagnosisFlashIPBFBD_VM_Byte30 : 240|8@1+ (1.0,0) [0|252] "" FBD_VM
 SG_ TPDiagnosisFlashIPBFBD_VM_Byte31 : 248|8@1+ (1.0,0) [0|252] "" FBD_VM
 SG_ TPDiagnosisFlashIPBFBD_VM_Byte32 : 256|8@1+ (1.0,0) [0|252] "" FBD_VM
 SG_ TPDiagnosisFlashIPBFBD_VM_Byte33 : 264|8@1+ (1.0,0) [0|252] "" FBD_VM
 SG_ TPDiagnosisFlashIPBFBD_VM_Byte34 : 272|8@1+ (1.0,0) [0|252] "" FBD_VM
 SG_ TPDiagnosisFlashIPBFBD_VM_Byte35 : 280|8@1+ (1.0,0) [0|252] "" FBD_VM
 SG_ TPDiagnosisFlashIPBFBD_VM_Byte36 : 288|8@1+ (1.0,0) [0|252] "" FBD_VM
 SG_ TPDiagnosisFlashIPBFBD_VM_Byte37 : 296|8@1+ (1.0,0) [0|252] "" FBD_VM
 SG_ TPDiagnosisFlashIPBFBD_VM_Byte38 : 304|8@1+ (1.0,0) [0|252] "" FBD_VM
 SG_ TPDiagnosisFlashIPBFBD_VM_Byte39 : 312|8@1+ (1.0,0) [0|252] "" FBD_VM
 SG_ TPDiagnosisFlashIPBFBD_VM_Byte40 : 320|8@1+ (1.0,0) [0|252] "" FBD_VM
 SG_ TPDiagnosisFlashIPBFBD_VM_Byte41 : 328|8@1+ (1.0,0) [0|252] "" FBD_VM
 SG_ TPDiagnosisFlashIPBFBD_VM_Byte42 : 336|8@1+ (1.0,0) [0|252] "" FBD_VM
 SG_ TPDiagnosisFlashIPBFBD_VM_Byte43 : 344|8@1+ (1.0,0) [0|252] "" FBD_VM
 SG_ TPDiagnosisFlashIPBFBD_VM_Byte44 : 352|8@1+ (1.0,0) [0|252] "" FBD_VM
 SG_ TPDiagnosisFlashIPBFBD_VM_Byte45 : 360|8@1+ (1.0,0) [0|252] "" FBD_VM
 SG_ TPDiagnosisFlashIPBFBD_VM_Byte46 : 368|8@1+ (1.0,0) [0|252] "" FBD_VM
 SG_ TPDiagnosisFlashIPBFBD_VM_Byte47 : 376|8@1+ (1.0,0) [0|252] "" FBD_VM
 SG_ TPDiagnosisFlashIPBFBD_VM_Byte48 : 384|8@1+ (1.0,0) [0|252] "" FBD_VM
 SG_ TPDiagnosisFlashIPBFBD_VM_Byte49 : 392|8@1+ (1.0,0) [0|252] "" FBD_VM
 SG_ TPDiagnosisFlashIPBFBD_VM_Byte50 : 400|8@1+ (1.0,0) [0|252] "" FBD_VM
 SG_ TPDiagnosisFlashIPBFBD_VM_Byte51 : 408|8@1+ (1.0,0) [0|252] "" FBD_VM
 SG_ TPDiagnosisFlashIPBFBD_VM_Byte52 : 416|8@1+ (1.0,0) [0|252] "" FBD_VM
 SG_ TPDiagnosisFlashIPBFBD_VM_Byte53 : 424|8@1+ (1.0,0) [0|252] "" FBD_VM
 SG_ TPDiagnosisFlashIPBFBD_VM_Byte54 : 432|8@1+ (1.0,0) [0|252] "" FBD_VM
 SG_ TPDiagnosisFlashIPBFBD_VM_Byte55 : 440|8@1+ (1.0,0) [0|252] "" FBD_VM
 SG_ TPDiagnosisFlashIPBFBD_VM_Byte56 : 448|8@1+ (1.0,0) [0|252] "" FBD_VM
 SG_ TPDiagnosisFlashIPBFBD_VM_Byte57 : 456|8@1+ (1.0,0) [0|252] "" FBD_VM
 SG_ TPDiagnosisFlashIPBFBD_VM_Byte58 : 464|8@1+ (1.0,0) [0|252] "" FBD_VM
 SG_ TPDiagnosisFlashIPBFBD_VM_Byte59 : 472|8@1+ (1.0,0) [0|252] "" FBD_VM
 SG_ TPDiagnosisFlashIPBFBD_VM_Byte60 : 480|8@1+ (1.0,0) [0|252] "" FBD_VM
 SG_ TPDiagnosisFlashIPBFBD_VM_Byte61 : 488|8@1+ (1.0,0) [0|252] "" FBD_VM
 SG_ TPDiagnosisFlashIPBFBD_VM_Byte62 : 496|8@1+ (1.0,0) [0|252] "" FBD_VM
 SG_ TPDiagnosisFlashIPBFBD_VM_Byte63 : 504|8@1+ (1.0,0) [0|252] "" FBD_VM

BO_ 705 TPDiagnosisFlash_IPB_FBD_VR: 64 IPB_App1
 SG_ TPDiagnosisFlashIPBFBD_VR_Byte00 : 0|8@1+ (1.0,0) [0|252] "" FBD_VR
 SG_ TPDiagnosisFlashIPBFBD_VR_Byte01 : 8|8@1+ (1.0,0) [0|252] "" FBD_VR
 SG_ TPDiagnosisFlashIPBFBD_VR_Byte02 : 16|8@1+ (1.0,0) [0|252] "" FBD_VR
 SG_ TPDiagnosisFlashIPBFBD_VR_Byte03 : 24|8@1+ (1.0,0) [0|252] "" FBD_VR
 SG_ TPDiagnosisFlashIPBFBD_VR_Byte04 : 32|8@1+ (1.0,0) [0|252] "" FBD_VR
 SG_ TPDiagnosisFlashIPBFBD_VR_Byte05 : 40|8@1+ (1.0,0) [0|252] "" FBD_VR
 SG_ TPDiagnosisFlashIPBFBD_VR_Byte06 : 48|8@1+ (1.0,0) [0|252] "" FBD_VR
 SG_ TPDiagnosisFlashIPBFBD_VR_Byte07 : 56|8@1+ (1.0,0) [0|252] "" FBD_VR
 SG_ TPDiagnosisFlashIPBFBD_VR_Byte08 : 64|8@1+ (1.0,0) [0|252] "" FBD_VR
 SG_ TPDiagnosisFlashIPBFBD_VR_Byte09 : 72|8@1+ (1.0,0) [0|252] "" FBD_VR
 SG_ TPDiagnosisFlashIPBFBD_VR_Byte10 : 80|8@1+ (1.0,0) [0|252] "" FBD_VR
 SG_ TPDiagnosisFlashIPBFBD_VR_Byte11 : 88|8@1+ (1.0,0) [0|252] "" FBD_VR
 SG_ TPDiagnosisFlashIPBFBD_VR_Byte12 : 96|8@1+ (1.0,0) [0|252] "" FBD_VR
 SG_ TPDiagnosisFlashIPBFBD_VR_Byte13 : 104|8@1+ (1.0,0) [0|252] "" FBD_VR
 SG_ TPDiagnosisFlashIPBFBD_VR_Byte14 : 112|8@1+ (1.0,0) [0|252] "" FBD_VR
 SG_ TPDiagnosisFlashIPBFBD_VR_Byte15 : 120|8@1+ (1.0,0) [0|252] "" FBD_VR
 SG_ TPDiagnosisFlashIPBFBD_VR_Byte16 : 128|8@1+ (1.0,0) [0|252] "" FBD_VR
 SG_ TPDiagnosisFlashIPBFBD_VR_Byte17 : 136|8@1+ (1.0,0) [0|252] "" FBD_VR
 SG_ TPDiagnosisFlashIPBFBD_VR_Byte18 : 144|8@1+ (1.0,0) [0|252] "" FBD_VR
 SG_ TPDiagnosisFlashIPBFBD_VR_Byte19 : 152|8@1+ (1.0,0) [0|252] "" FBD_VR
 SG_ TPDiagnosisFlashIPBFBD_VR_Byte20 : 160|8@1+ (1.0,0) [0|252] "" FBD_VR
 SG_ TPDiagnosisFlashIPBFBD_VR_Byte21 : 168|8@1+ (1.0,0) [0|252] "" FBD_VR
 SG_ TPDiagnosisFlashIPBFBD_VR_Byte22 : 176|8@1+ (1.0,0) [0|252] "" FBD_VR
 SG_ TPDiagnosisFlashIPBFBD_VR_Byte23 : 184|8@1+ (1.0,0) [0|252] "" FBD_VR
 SG_ TPDiagnosisFlashIPBFBD_VR_Byte24 : 192|8@1+ (1.0,0) [0|252] "" FBD_VR
 SG_ TPDiagnosisFlashIPBFBD_VR_Byte25 : 200|8@1+ (1.0,0) [0|252] "" FBD_VR
 SG_ TPDiagnosisFlashIPBFBD_VR_Byte26 : 208|8@1+ (1.0,0) [0|252] "" FBD_VR
 SG_ TPDiagnosisFlashIPBFBD_VR_Byte27 : 216|8@1+ (1.0,0) [0|252] "" FBD_VR
 SG_ TPDiagnosisFlashIPBFBD_VR_Byte28 : 224|8@1+ (1.0,0) [0|252] "" FBD_VR
 SG_ TPDiagnosisFlashIPBFBD_VR_Byte29 : 232|8@1+ (1.0,0) [0|252] "" FBD_VR
 SG_ TPDiagnosisFlashIPBFBD_VR_Byte30 : 240|8@1+ (1.0,0) [0|252] "" FBD_VR
 SG_ TPDiagnosisFlashIPBFBD_VR_Byte31 : 248|8@1+ (1.0,0) [0|252] "" FBD_VR
 SG_ TPDiagnosisFlashIPBFBD_VR_Byte32 : 256|8@1+ (1.0,0) [0|252] "" FBD_VR
 SG_ TPDiagnosisFlashIPBFBD_VR_Byte33 : 264|8@1+ (1.0,0) [0|252] "" FBD_VR
 SG_ TPDiagnosisFlashIPBFBD_VR_Byte34 : 272|8@1+ (1.0,0) [0|252] "" FBD_VR
 SG_ TPDiagnosisFlashIPBFBD_VR_Byte35 : 280|8@1+ (1.0,0) [0|252] "" FBD_VR
 SG_ TPDiagnosisFlashIPBFBD_VR_Byte36 : 288|8@1+ (1.0,0) [0|252] "" FBD_VR
 SG_ TPDiagnosisFlashIPBFBD_VR_Byte37 : 296|8@1+ (1.0,0) [0|252] "" FBD_VR
 SG_ TPDiagnosisFlashIPBFBD_VR_Byte38 : 304|8@1+ (1.0,0) [0|252] "" FBD_VR
 SG_ TPDiagnosisFlashIPBFBD_VR_Byte39 : 312|8@1+ (1.0,0) [0|252] "" FBD_VR
 SG_ TPDiagnosisFlashIPBFBD_VR_Byte40 : 320|8@1+ (1.0,0) [0|252] "" FBD_VR
 SG_ TPDiagnosisFlashIPBFBD_VR_Byte41 : 328|8@1+ (1.0,0) [0|252] "" FBD_VR
 SG_ TPDiagnosisFlashIPBFBD_VR_Byte42 : 336|8@1+ (1.0,0) [0|252] "" FBD_VR
 SG_ TPDiagnosisFlashIPBFBD_VR_Byte43 : 344|8@1+ (1.0,0) [0|252] "" FBD_VR
 SG_ TPDiagnosisFlashIPBFBD_VR_Byte44 : 352|8@1+ (1.0,0) [0|252] "" FBD_VR
 SG_ TPDiagnosisFlashIPBFBD_VR_Byte45 : 360|8@1+ (1.0,0) [0|252] "" FBD_VR
 SG_ TPDiagnosisFlashIPBFBD_VR_Byte46 : 368|8@1+ (1.0,0) [0|252] "" FBD_VR
 SG_ TPDiagnosisFlashIPBFBD_VR_Byte47 : 376|8@1+ (1.0,0) [0|252] "" FBD_VR
 SG_ TPDiagnosisFlashIPBFBD_VR_Byte48 : 384|8@1+ (1.0,0) [0|252] "" FBD_VR
 SG_ TPDiagnosisFlashIPBFBD_VR_Byte49 : 392|8@1+ (1.0,0) [0|252] "" FBD_VR
 SG_ TPDiagnosisFlashIPBFBD_VR_Byte50 : 400|8@1+ (1.0,0) [0|252] "" FBD_VR
 SG_ TPDiagnosisFlashIPBFBD_VR_Byte51 : 408|8@1+ (1.0,0) [0|252] "" FBD_VR
 SG_ TPDiagnosisFlashIPBFBD_VR_Byte52 : 416|8@1+ (1.0,0) [0|252] "" FBD_VR
 SG_ TPDiagnosisFlashIPBFBD_VR_Byte53 : 424|8@1+ (1.0,0) [0|252] "" FBD_VR
 SG_ TPDiagnosisFlashIPBFBD_VR_Byte54 : 432|8@1+ (1.0,0) [0|252] "" FBD_VR
 SG_ TPDiagnosisFlashIPBFBD_VR_Byte55 : 440|8@1+ (1.0,0) [0|252] "" FBD_VR
 SG_ TPDiagnosisFlashIPBFBD_VR_Byte56 : 448|8@1+ (1.0,0) [0|252] "" FBD_VR
 SG_ TPDiagnosisFlashIPBFBD_VR_Byte57 : 456|8@1+ (1.0,0) [0|252] "" FBD_VR
 SG_ TPDiagnosisFlashIPBFBD_VR_Byte58 : 464|8@1+ (1.0,0) [0|252] "" FBD_VR
 SG_ TPDiagnosisFlashIPBFBD_VR_Byte59 : 472|8@1+ (1.0,0) [0|252] "" FBD_VR
 SG_ TPDiagnosisFlashIPBFBD_VR_Byte60 : 480|8@1+ (1.0,0) [0|252] "" FBD_VR
 SG_ TPDiagnosisFlashIPBFBD_VR_Byte61 : 488|8@1+ (1.0,0) [0|252] "" FBD_VR
 SG_ TPDiagnosisFlashIPBFBD_VR_Byte62 : 496|8@1+ (1.0,0) [0|252] "" FBD_VR
 SG_ TPDiagnosisFlashIPBFBD_VR_Byte63 : 504|8@1+ (1.0,0) [0|252] "" FBD_VR

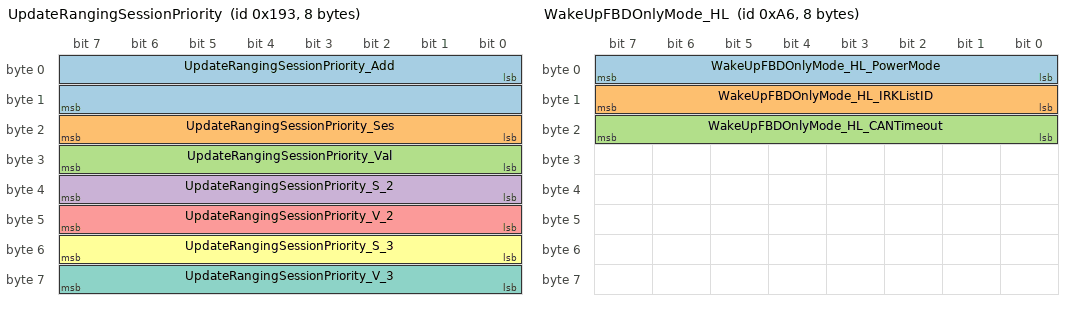
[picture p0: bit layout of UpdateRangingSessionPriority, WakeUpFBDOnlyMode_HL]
BO_ 403 UpdateRangingSessionPriority: 8 IPB_App1
 SG_ UpdateRangingSessionPriority_Add : 0|16@1+ (1,0) [0|0] "" FBD_HL,FBD_HM,FBD_HR,FBD_MM,FBD_Miko,FBD_Trunk,FBD_VL,FBD_VM,FBD_VR
 SG_ UpdateRangingSessionPriority_Ses : 16|8@1+ (1.0,0) [0|252] "" FBD_HL,FBD_HM,FBD_HR,FBD_MM,FBD_Miko,FBD_Trunk,FBD_VL,FBD_VM,FBD_VR
 SG_ UpdateRangingSessionPriority_Val : 24|8@1+ (1.0,0) [0|252] "" FBD_HL,FBD_HM,FBD_HR,FBD_MM,FBD_Miko,FBD_Trunk,FBD_VL,FBD_VM,FBD_VR
 SG_ UpdateRangingSessionPriority_S_2 : 32|8@1+ (1.0,0) [0|252] "" FBD_HL,FBD_HM,FBD_HR,FBD_MM,FBD_Miko,FBD_Trunk,FBD_VL,FBD_VM,FBD_VR
 SG_ UpdateRangingSessionPriority_V_2 : 40|8@1+ (1.0,0) [0|252] "" FBD_HL,FBD_HM,FBD_HR,FBD_MM,FBD_Miko,FBD_Trunk,FBD_VL,FBD_VM,FBD_VR
 SG_ UpdateRangingSessionPriority_S_3 : 48|8@1+ (1.0,0) [0|252] "" FBD_HL,FBD_HM,FBD_HR,FBD_MM,FBD_Miko,FBD_Trunk,FBD_VL,FBD_VM,FBD_VR
 SG_ UpdateRangingSessionPriority_V_3 : 56|8@1+ (1.0,0) [0|252] "" FBD_HL,FBD_HM,FBD_HR,FBD_MM,FBD_Miko,FBD_Trunk,FBD_VL,FBD_VM,FBD_VR

BO_ 166 WakeUpFBDOnlyMode_HL: 8 FBD_HL
 SG_ WakeUpFBDOnlyMode_HL_PowerMode : 0|8@1+ (1,0) [0|0] "" FBD_HM,FBD_HR,FBD_MM,FBD_Miko,FBD_Trunk,FBD_VL,FBD_VM,FBD_VR,IPB_App1
 SG_ WakeUpFBDOnlyMode_HL_IRKListID : 8|8@1+ (1.0,0) [0|252] "" FBD_HM,FBD_HR,FBD_MM,FBD_Miko,FBD_Trunk,FBD_VL,FBD_VM,FBD_VR,IPB_App1
 SG_ WakeUpFBDOnlyMode_HL_CANTimeout : 16|8@1+ (1.0,0) [0|252] "" FBD_HM,FBD_HR,FBD_MM,FBD_Miko,FBD_Trunk,FBD_VL,FBD_VM,FBD_VR,IPB_App1

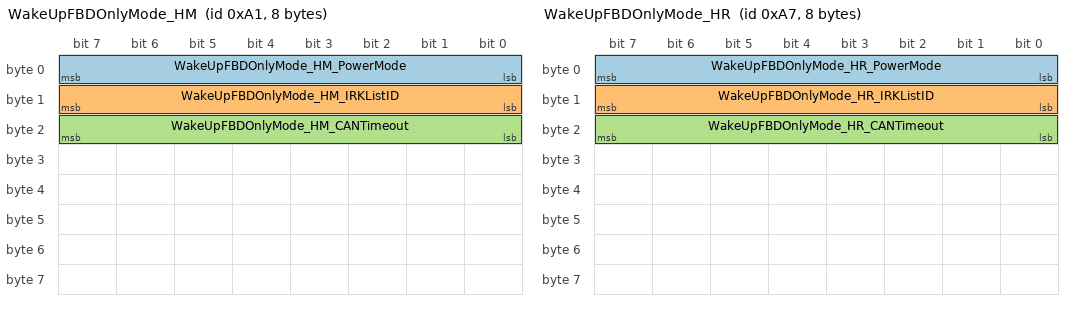
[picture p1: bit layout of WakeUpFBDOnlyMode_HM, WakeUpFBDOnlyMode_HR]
BO_ 161 WakeUpFBDOnlyMode_HM: 8 FBD_HM
 SG_ WakeUpFBDOnlyMode_HM_PowerMode : 0|8@1+ (1,0) [0|0] "" FBD_HL,FBD_HR,FBD_MM,FBD_Miko,FBD_Trunk,FBD_VL,FBD_VM,FBD_VR,IPB_App1
 SG_ WakeUpFBDOnlyMode_HM_IRKListID : 8|8@1+ (1.0,0) [0|252] "" FBD_HL,FBD_HR,FBD_MM,FBD_Miko,FBD_Trunk,FBD_VL,FBD_VM,FBD_VR,IPB_App1
 SG_ WakeUpFBDOnlyMode_HM_CANTimeout : 16|8@1+ (1.0,0) [0|252] "" FBD_HL,FBD_HR,FBD_MM,FBD_Miko,FBD_Trunk,FBD_VL,FBD_VM,FBD_VR,IPB_App1

BO_ 167 WakeUpFBDOnlyMode_HR: 8 FBD_HR
 SG_ WakeUpFBDOnlyMode_HR_PowerMode : 0|8@1+ (1,0) [0|0] "" FBD_HL,FBD_HM,FBD_MM,FBD_Miko,FBD_Trunk,FBD_VL,FBD_VM,FBD_VR,IPB_App1
 SG_ WakeUpFBDOnlyMode_HR_IRKListID : 8|8@1+ (1.0,0) [0|252] "" FBD_HL,FBD_HM,FBD_MM,FBD_Miko,FBD_Trunk,FBD_VL,FBD_VM,FBD_VR,IPB_App1
 SG_ WakeUpFBDOnlyMode_HR_CANTimeout : 16|8@1+ (1.0,0) [0|252] "" FBD_HL,FBD_HM,FBD_MM,FBD_Miko,FBD_Trunk,FBD_VL,FBD_VM,FBD_VR,IPB_App1

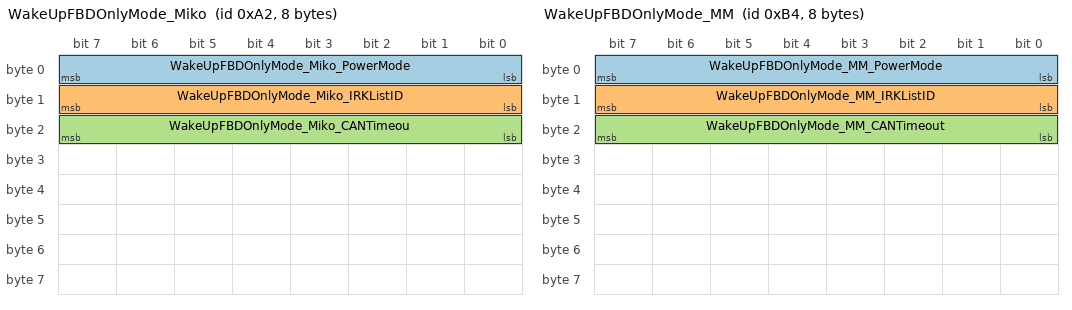
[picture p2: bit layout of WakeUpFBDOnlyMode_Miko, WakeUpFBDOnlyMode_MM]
BO_ 162 WakeUpFBDOnlyMode_Miko: 8 FBD_Miko
 SG_ WakeUpFBDOnlyMode_Miko_PowerMode : 0|8@1+ (1,0) [0|0] "" FBD_HL,FBD_HM,FBD_HR,FBD_MM,FBD_Trunk,FBD_VL,FBD_VM,FBD_VR,IPB_App1
 SG_ WakeUpFBDOnlyMode_Miko_IRKListID : 8|8@1+ (1.0,0) [0|252] "" FBD_HL,FBD_HM,FBD_HR,FBD_MM,FBD_Trunk,FBD_VL,FBD_VM,FBD_VR,IPB_App1
 SG_ WakeUpFBDOnlyMode_Miko_CANTimeou : 16|8@1+ (1.0,0) [0|252] "" FBD_HL,FBD_HM,FBD_HR,FBD_MM,FBD_Trunk,FBD_VL,FBD_VM,FBD_VR,IPB_App1

BO_ 180 WakeUpFBDOnlyMode_MM: 8 FBD_MM
 SG_ WakeUpFBDOnlyMode_MM_PowerMode : 0|8@1+ (1,0) [0|0] "" FBD_HL,FBD_HM,FBD_HR,FBD_Miko,FBD_Trunk,FBD_VL,FBD_VM,FBD_VR,IPB_App1
 SG_ WakeUpFBDOnlyMode_MM_IRKListID : 8|8@1+ (1.0,0) [0|252] "" FBD_HL,FBD_HM,FBD_HR,FBD_Miko,FBD_Trunk,FBD_VL,FBD_VM,FBD_VR,IPB_App1
 SG_ WakeUpFBDOnlyMode_MM_CANTimeout : 16|8@1+ (1.0,0) [0|252] "" FBD_HL,FBD_HM,FBD_HR,FBD_Miko,FBD_Trunk,FBD_VL,FBD_VM,FBD_VR,IPB_App1

BO_ 168 WakeUpFBDOnlyMode_SML: 8 IPB_App1
 SG_ WakeUpFBDOnlyMode_SML_PowerMode : 0|8@1+ (1,0) [0|0] "" FBD_HL,FBD_HM,FBD_HR,FBD_MM,FBD_Miko,FBD_Trunk,FBD_VL,FBD_VM,FBD_VR
 SG_ WakeUpFBDOnlyMode_SML_SessionIDS : 8|8@1+ (1.0,0) [0|252] "" FBD_HL,FBD_HM,FBD_HR,FBD_MM,FBD_Miko,FBD_Trunk,FBD_VL,FBD_VM,FBD_VR

BO_ 169 WakeUpFBDOnlyMode_SMR: 8 IPB_App1
 SG_ WakeUpFBDOnlyMode_SMR_PowerMode : 0|8@1+ (1,0) [0|0] "" FBD_HL,FBD_HM,FBD_HR,FBD_MM,FBD_Miko,FBD_Trunk,FBD_VL,FBD_VM,FBD_VR
 SG_ WakeUpFBDOnlyMode_SMR_SessionIDS : 8|8@1+ (1.0,0) [0|252] "" FBD_HL,FBD_HM,FBD_HR,FBD_MM,FBD_Miko,FBD_Trunk,FBD_VL,FBD_VM,FBD_VR

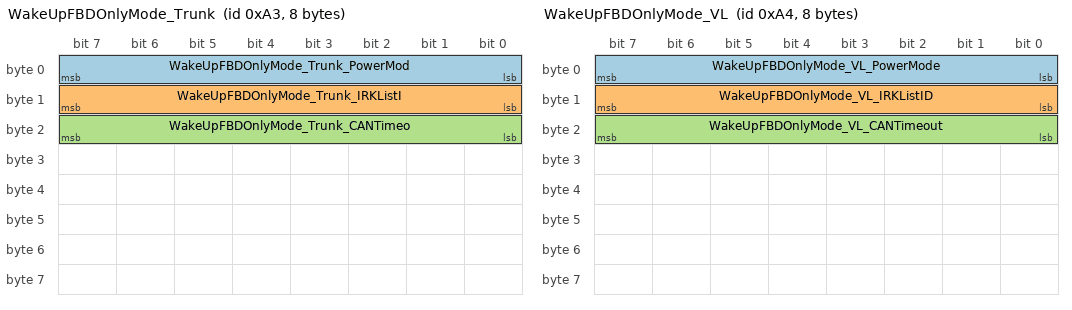
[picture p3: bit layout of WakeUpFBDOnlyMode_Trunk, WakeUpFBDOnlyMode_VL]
BO_ 163 WakeUpFBDOnlyMode_Trunk: 8 FBD_Trunk
 SG_ WakeUpFBDOnlyMode_Trunk_PowerMod : 0|8@1+ (1,0) [0|0] "" FBD_HL,FBD_HM,FBD_HR,FBD_MM,FBD_Miko,FBD_VL,FBD_VM,FBD_VR,IPB_App1
 SG_ WakeUpFBDOnlyMode_Trunk_IRKListI : 8|8@1+ (1.0,0) [0|252] "" FBD_HL,FBD_HM,FBD_HR,FBD_MM,FBD_Miko,FBD_VL,FBD_VM,FBD_VR,IPB_App1
 SG_ WakeUpFBDOnlyMode_Trunk_CANTimeo : 16|8@1+ (1.0,0) [0|252] "" FBD_HL,FBD_HM,FBD_HR,FBD_MM,FBD_Miko,FBD_VL,FBD_VM,FBD_VR,IPB_App1

BO_ 164 WakeUpFBDOnlyMode_VL: 8 FBD_VL
 SG_ WakeUpFBDOnlyMode_VL_PowerMode : 0|8@1+ (1,0) [0|0] "" FBD_HL,FBD_HM,FBD_HR,FBD_MM,FBD_Miko,FBD_Trunk,FBD_VM,FBD_VR,IPB_App1
 SG_ WakeUpFBDOnlyMode_VL_IRKListID : 8|8@1+ (1.0,0) [0|252] "" FBD_HL,FBD_HM,FBD_HR,FBD_MM,FBD_Miko,FBD_Trunk,FBD_VM,FBD_VR,IPB_App1
 SG_ WakeUpFBDOnlyMode_VL_CANTimeout : 16|8@1+ (1.0,0) [0|252] "" FBD_HL,FBD_HM,FBD_HR,FBD_MM,FBD_Miko,FBD_Trunk,FBD_VM,FBD_VR,IPB_App1

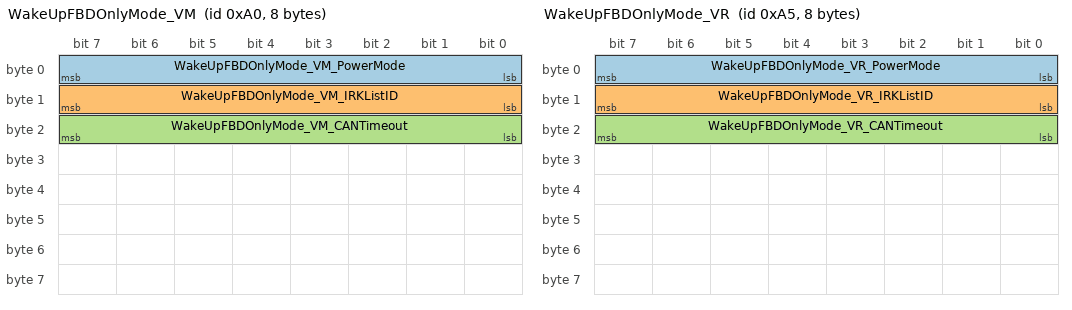
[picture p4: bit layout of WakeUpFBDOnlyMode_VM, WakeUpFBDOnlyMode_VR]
BO_ 160 WakeUpFBDOnlyMode_VM: 8 FBD_VM
 SG_ WakeUpFBDOnlyMode_VM_PowerMode : 0|8@1+ (1,0) [0|0] "" FBD_HL,FBD_HM,FBD_HR,FBD_MM,FBD_Miko,FBD_Trunk,FBD_VL,FBD_VR,IPB_App1
 SG_ WakeUpFBDOnlyMode_VM_IRKListID : 8|8@1+ (1.0,0) [0|252] "" FBD_HL,FBD_HM,FBD_HR,FBD_MM,FBD_Miko,FBD_Trunk,FBD_VL,FBD_VR,IPB_App1
 SG_ WakeUpFBDOnlyMode_VM_CANTimeout : 16|8@1+ (1.0,0) [0|252] "" FBD_HL,FBD_HM,FBD_HR,FBD_MM,FBD_Miko,FBD_Trunk,FBD_VL,FBD_VR,IPB_App1

BO_ 165 WakeUpFBDOnlyMode_VR: 8 FBD_VR
 SG_ WakeUpFBDOnlyMode_VR_PowerMode : 0|8@1+ (1,0) [0|0] "" FBD_HL,FBD_HM,FBD_HR,FBD_MM,FBD_Miko,FBD_Trunk,FBD_VL,FBD_VM,IPB_App1
 SG_ WakeUpFBDOnlyMode_VR_IRKListID : 8|8@1+ (1.0,0) [0|252] "" FBD_HL,FBD_HM,FBD_HR,FBD_MM,FBD_Miko,FBD_Trunk,FBD_VL,FBD_VM,IPB_App1
 SG_ WakeUpFBDOnlyMode_VR_CANTimeout : 16|8@1+ (1.0,0) [0|252] "" FBD_HL,FBD_HM,FBD_HR,FBD_MM,FBD_Miko,FBD_Trunk,FBD_VL,FBD_VM,IPB_App1

CM_ SG_ 903 TPBLEParameter_FBD_VM_FBD_Trunk_ "Signal contains parameters";
CM_ SG_ 903 TPBLEParameter_FBD_VM_FBD_Trun_2 "Signal contains parameters";
CM_ SG_ 903 TPBLEParameter_FBD_VM_FBD_Trun_3 "Signal contains parameters";
CM_ SG_ 903 TPBLEParameter_FBD_VM_FBD_Trun_4 "Signal contains parameters";
CM_ SG_ 903 TPBLEParameter_FBD_VM_FBD_Trun_5 "Signal contains parameters";
CM_ SG_ 903 TPBLEParameter_FBD_VM_FBD_Trun_6 "Signal contains parameters";
CM_ SG_ 903 TPBLEParameter_FBD_VM_FBD_Trun_7 "Signal contains parameters";
CM_ SG_ 903 TPBLEParameter_FBD_VM_FBD_Trun_8 "Signal contains parameters";
CM_ SG_ 903 TPBLEParameter_FBD_VM_FBD_Trun_9 "Signal contains parameters";
CM_ SG_ 903 TPBLEParameter_FBD_VM_FBD_Tru_10 "Signal contains parameters";
CM_ SG_ 903 TPBLEParameter_FBD_VM_FBD_Tru_11 "Signal contains parameters";
CM_ SG_ 903 TPBLEParameter_FBD_VM_FBD_Tru_12 "Signal contains parameters";
CM_ SG_ 903 TPBLEParameter_FBD_VM_FBD_Tru_13 "Signal contains parameters";
CM_ SG_ 903 TPBLEParameter_FBD_VM_FBD_Tru_14 "Signal contains parameters";
CM_ SG_ 903 TPBLEParameter_FBD_VM_FBD_Tru_15 "Signal contains parameters";
CM_ SG_ 903 TPBLEParameter_FBD_VM_FBD_Tru_16 "Signal contains parameters";
CM_ SG_ 903 TPBLEParameter_FBD_VM_FBD_Tru_17 "Signal contains parameters";
CM_ SG_ 903 TPBLEParameter_FBD_VM_FBD_Tru_18 "Signal contains parameters";
CM_ SG_ 903 TPBLEParameter_FBD_VM_FBD_Tru_19 "Signal contains parameters";
CM_ SG_ 903 TPBLEParameter_FBD_VM_FBD_Tru_20 "Signal contains parameters";
CM_ SG_ 903 TPBLEParameter_FBD_VM_FBD_Tru_21 "Signal contains parameters";
CM_ SG_ 903 TPBLEParameter_FBD_VM_FBD_Tru_22 "Signal contains parameters";
CM_ SG_ 903 TPBLEParameter_FBD_VM_FBD_Tru_23 "Signal contains parameters";
CM_ SG_ 903 TPBLEParameter_FBD_VM_FBD_Tru_24 "Signal contains parameters";
CM_ SG_ 903 TPBLEParameter_FBD_VM_FBD_Tru_25 "Signal contains parameters";
CM_ SG_ 903 TPBLEParameter_FBD_VM_FBD_Tru_26 "Signal contains parameters";
CM_ SG_ 903 TPBLEParameter_FBD_VM_FBD_Tru_27 "Signal contains parameters";
CM_ SG_ 903 TPBLEParameter_FBD_VM_FBD_Tru_28 "Signal contains parameters";
CM_ SG_ 903 TPBLEParameter_FBD_VM_FBD_Tru_29 "Signal contains parameters";
CM_ SG_ 903 TPBLEParameter_FBD_VM_FBD_Tru_30 "Signal contains parameters";
CM_ SG_ 903 TPBLEParameter_FBD_VM_FBD_Tru_31 "Signal contains parameters";
CM_ SG_ 903 TPBLEParameter_FBD_VM_FBD_Tru_32 "Signal contains parameters";
CM_ SG_ 903 TPBLEParameter_FBD_VM_FBD_Tru_33 "Signal contains parameters";
CM_ SG_ 903 TPBLEParameter_FBD_VM_FBD_Tru_34 "Signal contains parameters";
CM_ SG_ 903 TPBLEParameter_FBD_VM_FBD_Tru_35 "Signal contains parameters";
CM_ SG_ 903 TPBLEParameter_FBD_VM_FBD_Tru_36 "Signal contains parameters";
CM_ SG_ 903 TPBLEParameter_FBD_VM_FBD_Tru_37 "Signal contains parameters";
CM_ SG_ 903 TPBLEParameter_FBD_VM_FBD_Tru_38 "Signal contains parameters";
CM_ SG_ 903 TPBLEParameter_FBD_VM_FBD_Tru_39 "Signal contains parameters";
CM_ SG_ 903 TPBLEParameter_FBD_VM_FBD_Tru_40 "Signal contains parameters";
CM_ SG_ 903 TPBLEParameter_FBD_VM_FBD_Tru_41 "Signal contains parameters";
CM_ SG_ 903 TPBLEParameter_FBD_VM_FBD_Tru_42 "Signal contains parameters";
CM_ SG_ 903 TPBLEParameter_FBD_VM_FBD_Tru_43 "Signal contains parameters";
CM_ SG_ 903 TPBLEParameter_FBD_VM_FBD_Tru_44 "Signal contains parameters";
CM_ SG_ 903 TPBLEParameter_FBD_VM_FBD_Tru_45 "Signal contains parameters";
CM_ SG_ 903 TPBLEParameter_FBD_VM_FBD_Tru_46 "Signal contains parameters";
CM_ SG_ 903 TPBLEParameter_FBD_VM_FBD_Tru_47 "Signal contains parameters";
CM_ SG_ 903 TPBLEParameter_FBD_VM_FBD_Tru_48 "Signal contains parameters";
CM_ SG_ 903 TPBLEParameter_FBD_VM_FBD_Tru_49 "Signal contains parameters";
CM_ SG_ 903 TPBLEParameter_FBD_VM_FBD_Tru_50 "Signal contains parameters";
CM_ SG_ 903 TPBLEParameter_FBD_VM_FBD_Tru_51 "Signal contains parameters";
CM_ SG_ 903 TPBLEParameter_FBD_VM_FBD_Tru_52 "Signal contains parameters";
CM_ SG_ 903 TPBLEParameter_FBD_VM_FBD_Tru_53 "Signal contains parameters";
CM_ SG_ 903 TPBLEParameter_FBD_VM_FBD_Tru_54 "Signal contains parameters";
CM_ SG_ 903 TPBLEParameter_FBD_VM_FBD_Tru_55 "Signal contains parameters";
CM_ SG_ 903 TPBLEParameter_FBD_VM_FBD_Tru_56 "Signal contains parameters";
CM_ SG_ 903 TPBLEParameter_FBD_VM_FBD_Tru_57 "Signal contains parameters";
CM_ SG_ 903 TPBLEParameter_FBD_VM_FBD_Tru_58 "Signal contains parameters";
CM_ SG_ 903 TPBLEParameter_FBD_VM_FBD_Tru_59 "Signal contains parameters";
CM_ SG_ 903 TPBLEParameter_FBD_VM_FBD_Tru_60 "Signal contains parameters";
CM_ SG_ 903 TPBLEParameter_FBD_VM_FBD_Tru_61 "Signal contains parameters";
CM_ SG_ 903 TPBLEParameter_FBD_VM_FBD_Tru_62 "Signal contains parameters";
CM_ SG_ 903 TPBLEParameter_FBD_VM_FBD_Tru_63 "Signal contains parameters";
CM_ SG_ 903 TPBLEParameter_FBD_VM_FBD_Tru_64 "Signal contains parameters";
CM_ SG_ 904 TPBLEParameter_FBD_VM_FBD_VL_Byt "Signal contains parameters";
CM_ SG_ 904 TPBLEParameter_FBD_VM_FBD_VL_B_2 "Signal contains parameters";
CM_ SG_ 904 TPBLEParameter_FBD_VM_FBD_VL_B_3 "Signal contains parameters";
CM_ SG_ 904 TPBLEParameter_FBD_VM_FBD_VL_B_4 "Signal contains parameters";
CM_ SG_ 904 TPBLEParameter_FBD_VM_FBD_VL_B_5 "Signal contains parameters";
CM_ SG_ 904 TPBLEParameter_FBD_VM_FBD_VL_B_6 "Signal contains parameters";
CM_ SG_ 904 TPBLEParameter_FBD_VM_FBD_VL_B_7 "Signal contains parameters";
CM_ SG_ 904 TPBLEParameter_FBD_VM_FBD_VL_B_8 "Signal contains parameters";
CM_ SG_ 904 TPBLEParameter_FBD_VM_FBD_VL_B_9 "Signal contains parameters";
CM_ SG_ 904 TPBLEParameter_FBD_VM_FBD_VL__10 "Signal contains parameters";
CM_ SG_ 904 TPBLEParameter_FBD_VM_FBD_VL__11 "Signal contains parameters";
CM_ SG_ 904 TPBLEParameter_FBD_VM_FBD_VL__12 "Signal contains parameters";
CM_ SG_ 904 TPBLEParameter_FBD_VM_FBD_VL__13 "Signal contains parameters";
CM_ SG_ 904 TPBLEParameter_FBD_VM_FBD_VL__14 "Signal contains parameters";
CM_ SG_ 904 TPBLEParameter_FBD_VM_FBD_VL__15 "Signal contains parameters";
CM_ SG_ 904 TPBLEParameter_FBD_VM_FBD_VL__16 "Signal contains parameters";
CM_ SG_ 904 TPBLEParameter_FBD_VM_FBD_VL__17 "Signal contains parameters";
CM_ SG_ 904 TPBLEParameter_FBD_VM_FBD_VL__18 "Signal contains parameters";
CM_ SG_ 904 TPBLEParameter_FBD_VM_FBD_VL__19 "Signal contains parameters";
CM_ SG_ 904 TPBLEParameter_FBD_VM_FBD_VL__20 "Signal contains parameters";
CM_ SG_ 904 TPBLEParameter_FBD_VM_FBD_VL__21 "Signal contains parameters";
CM_ SG_ 904 TPBLEParameter_FBD_VM_FBD_VL__22 "Signal contains parameters";
CM_ SG_ 904 TPBLEParameter_FBD_VM_FBD_VL__23 "Signal contains parameters";
CM_ SG_ 904 TPBLEParameter_FBD_VM_FBD_VL__24 "Signal contains parameters";
CM_ SG_ 904 TPBLEParameter_FBD_VM_FBD_VL__25 "Signal contains parameters";
CM_ SG_ 904 TPBLEParameter_FBD_VM_FBD_VL__26 "Signal contains parameters";
CM_ SG_ 904 TPBLEParameter_FBD_VM_FBD_VL__27 "Signal contains parameters";
CM_ SG_ 904 TPBLEParameter_FBD_VM_FBD_VL__28 "Signal contains parameters";
CM_ SG_ 904 TPBLEParameter_FBD_VM_FBD_VL__29 "Signal contains parameters";
CM_ SG_ 904 TPBLEParameter_FBD_VM_FBD_VL__30 "Signal contains parameters";
CM_ SG_ 904 TPBLEParameter_FBD_VM_FBD_VL__31 "Signal contains parameters";
CM_ SG_ 904 TPBLEParameter_FBD_VM_FBD_VL__32 "Signal contains parameters";
CM_ SG_ 904 TPBLEParameter_FBD_VM_FBD_VL__33 "Signal contains parameters";
CM_ SG_ 904 TPBLEParameter_FBD_VM_FBD_VL__34 "Signal contains parameters";
CM_ SG_ 904 TPBLEParameter_FBD_VM_FBD_VL__35 "Signal contains parameters";
CM_ SG_ 904 TPBLEParameter_FBD_VM_FBD_VL__36 "Signal contains parameters";
CM_ SG_ 904 TPBLEParameter_FBD_VM_FBD_VL__37 "Signal contains parameters";
CM_ SG_ 904 TPBLEParameter_FBD_VM_FBD_VL__38 "Signal contains parameters";
CM_ SG_ 904 TPBLEParameter_FBD_VM_FBD_VL__39 "Signal contains parameters";
CM_ SG_ 904 TPBLEParameter_FBD_VM_FBD_VL__40 "Signal contains parameters";
CM_ SG_ 904 TPBLEParameter_FBD_VM_FBD_VL__41 "Signal contains parameters";
CM_ SG_ 904 TPBLEParameter_FBD_VM_FBD_VL__42 "Signal contains parameters";
CM_ SG_ 904 TPBLEParameter_FBD_VM_FBD_VL__43 "Signal contains parameters";
CM_ SG_ 904 TPBLEParameter_FBD_VM_FBD_VL__44 "Signal contains parameters";
CM_ SG_ 904 TPBLEParameter_FBD_VM_FBD_VL__45 "Signal contains parameters";
CM_ SG_ 904 TPBLEParameter_FBD_VM_FBD_VL__46 "Signal contains parameters";
CM_ SG_ 904 TPBLEParameter_FBD_VM_FBD_VL__47 "Signal contains parameters";
CM_ SG_ 904 TPBLEParameter_FBD_VM_FBD_VL__48 "Signal contains parameters";
CM_ SG_ 904 TPBLEParameter_FBD_VM_FBD_VL__49 "Signal contains parameters";
CM_ SG_ 904 TPBLEParameter_FBD_VM_FBD_VL__50 "Signal contains parameters";
CM_ SG_ 904 TPBLEParameter_FBD_VM_FBD_VL__51 "Signal contains parameters";
CM_ SG_ 904 TPBLEParameter_FBD_VM_FBD_VL__52 "Signal contains parameters";
CM_ SG_ 904 TPBLEParameter_FBD_VM_FBD_VL__53 "Signal contains parameters";
CM_ SG_ 904 TPBLEParameter_FBD_VM_FBD_VL__54 "Signal contains parameters";
CM_ SG_ 904 TPBLEParameter_FBD_VM_FBD_VL__55 "Signal contains parameters";
CM_ SG_ 904 TPBLEParameter_FBD_VM_FBD_VL__56 "Signal contains parameters";
CM_ SG_ 904 TPBLEParameter_FBD_VM_FBD_VL__57 "Signal contains parameters";
CM_ SG_ 904 TPBLEParameter_FBD_VM_FBD_VL__58 "Signal contains parameters";
CM_ SG_ 904 TPBLEParameter_FBD_VM_FBD_VL__59 "Signal contains parameters";
CM_ SG_ 904 TPBLEParameter_FBD_VM_FBD_VL__60 "Signal contains parameters";
CM_ SG_ 904 TPBLEParameter_FBD_VM_FBD_VL__61 "Signal contains parameters";
CM_ SG_ 904 TPBLEParameter_FBD_VM_FBD_VL__62 "Signal contains parameters";
CM_ SG_ 904 TPBLEParameter_FBD_VM_FBD_VL__63 "Signal contains parameters";
CM_ SG_ 904 TPBLEParameter_FBD_VM_FBD_VL__64 "Signal contains parameters";
CM_ SG_ 905 TPBLEParameter_FBD_VM_FBD_VR_Byt "Signal contains parameters";
CM_ SG_ 905 TPBLEParameter_FBD_VM_FBD_VR_B_2 "Signal contains parameters";
CM_ SG_ 905 TPBLEParameter_FBD_VM_FBD_VR_B_3 "Signal contains parameters";
CM_ SG_ 905 TPBLEParameter_FBD_VM_FBD_VR_B_4 "Signal contains parameters";
CM_ SG_ 905 TPBLEParameter_FBD_VM_FBD_VR_B_5 "Signal contains parameters";
CM_ SG_ 905 TPBLEParameter_FBD_VM_FBD_VR_B_6 "Signal contains parameters";
CM_ SG_ 905 TPBLEParameter_FBD_VM_FBD_VR_B_7 "Signal contains parameters";
CM_ SG_ 905 TPBLEParameter_FBD_VM_FBD_VR_B_8 "Signal contains parameters";
CM_ SG_ 905 TPBLEParameter_FBD_VM_FBD_VR_B_9 "Signal contains parameters";
CM_ SG_ 905 TPBLEParameter_FBD_VM_FBD_VR__10 "Signal contains parameters";
CM_ SG_ 905 TPBLEParameter_FBD_VM_FBD_VR__11 "Signal contains parameters";
CM_ SG_ 905 TPBLEParameter_FBD_VM_FBD_VR__12 "Signal contains parameters";
CM_ SG_ 905 TPBLEParameter_FBD_VM_FBD_VR__13 "Signal contains parameters";
CM_ SG_ 905 TPBLEParameter_FBD_VM_FBD_VR__14 "Signal contains parameters";
CM_ SG_ 905 TPBLEParameter_FBD_VM_FBD_VR__15 "Signal contains parameters";
CM_ SG_ 905 TPBLEParameter_FBD_VM_FBD_VR__16 "Signal contains parameters";
CM_ SG_ 905 TPBLEParameter_FBD_VM_FBD_VR__17 "Signal contains parameters";
CM_ SG_ 905 TPBLEParameter_FBD_VM_FBD_VR__18 "Signal contains parameters";
CM_ SG_ 905 TPBLEParameter_FBD_VM_FBD_VR__19 "Signal contains parameters";
CM_ SG_ 905 TPBLEParameter_FBD_VM_FBD_VR__20 "Signal contains parameters";
CM_ SG_ 905 TPBLEParameter_FBD_VM_FBD_VR__21 "Signal contains parameters";
CM_ SG_ 905 TPBLEParameter_FBD_VM_FBD_VR__22 "Signal contains parameters";
CM_ SG_ 905 TPBLEParameter_FBD_VM_FBD_VR__23 "Signal contains parameters";
CM_ SG_ 905 TPBLEParameter_FBD_VM_FBD_VR__24 "Signal contains parameters";
CM_ SG_ 905 TPBLEParameter_FBD_VM_FBD_VR__25 "Signal contains parameters";
CM_ SG_ 905 TPBLEParameter_FBD_VM_FBD_VR__26 "Signal contains parameters";
CM_ SG_ 905 TPBLEParameter_FBD_VM_FBD_VR__27 "Signal contains parameters";
CM_ SG_ 905 TPBLEParameter_FBD_VM_FBD_VR__28 "Signal contains parameters";
CM_ SG_ 905 TPBLEParameter_FBD_VM_FBD_VR__29 "Signal contains parameters";
CM_ SG_ 905 TPBLEParameter_FBD_VM_FBD_VR__30 "Signal contains parameters";
CM_ SG_ 905 TPBLEParameter_FBD_VM_FBD_VR__31 "Signal contains parameters";
CM_ SG_ 905 TPBLEParameter_FBD_VM_FBD_VR__32 "Signal contains parameters";
CM_ SG_ 905 TPBLEParameter_FBD_VM_FBD_VR__33 "Signal contains parameters";
CM_ SG_ 905 TPBLEParameter_FBD_VM_FBD_VR__34 "Signal contains parameters";
CM_ SG_ 905 TPBLEParameter_FBD_VM_FBD_VR__35 "Signal contains parameters";
CM_ SG_ 905 TPBLEParameter_FBD_VM_FBD_VR__36 "Signal contains parameters";
CM_ SG_ 905 TPBLEParameter_FBD_VM_FBD_VR__37 "Signal contains parameters";
CM_ SG_ 905 TPBLEParameter_FBD_VM_FBD_VR__38 "Signal contains parameters";
CM_ SG_ 905 TPBLEParameter_FBD_VM_FBD_VR__39 "Signal contains parameters";
CM_ SG_ 905 TPBLEParameter_FBD_VM_FBD_VR__40 "Signal contains parameters";
CM_ SG_ 905 TPBLEParameter_FBD_VM_FBD_VR__41 "Signal contains parameters";
CM_ SG_ 905 TPBLEParameter_FBD_VM_FBD_VR__42 "Signal contains parameters";
CM_ SG_ 905 TPBLEParameter_FBD_VM_FBD_VR__43 "Signal contains parameters";
CM_ SG_ 905 TPBLEParameter_FBD_VM_FBD_VR__44 "Signal contains parameters";
CM_ SG_ 905 TPBLEParameter_FBD_VM_FBD_VR__45 "Signal contains parameters";
CM_ SG_ 905 TPBLEParameter_FBD_VM_FBD_VR__46 "Signal contains parameters";
CM_ SG_ 905 TPBLEParameter_FBD_VM_FBD_VR__47 "Signal contains parameters";
CM_ SG_ 905 TPBLEParameter_FBD_VM_FBD_VR__48 "Signal contains parameters";
CM_ SG_ 905 TPBLEParameter_FBD_VM_FBD_VR__49 "Signal contains parameters";
CM_ SG_ 905 TPBLEParameter_FBD_VM_FBD_VR__50 "Signal contains parameters";
CM_ SG_ 905 TPBLEParameter_FBD_VM_FBD_VR__51 "Signal contains parameters";
CM_ SG_ 905 TPBLEParameter_FBD_VM_FBD_VR__52 "Signal contains parameters";
CM_ SG_ 905 TPBLEParameter_FBD_VM_FBD_VR__53 "Signal contains parameters";
CM_ SG_ 905 TPBLEParameter_FBD_VM_FBD_VR__54 "Signal contains parameters";
CM_ SG_ 905 TPBLEParameter_FBD_VM_FBD_VR__55 "Signal contains parameters";
CM_ SG_ 905 TPBLEParameter_FBD_VM_FBD_VR__56 "Signal contains parameters";
CM_ SG_ 905 TPBLEParameter_FBD_VM_FBD_VR__57 "Signal contains parameters";
CM_ SG_ 905 TPBLEParameter_FBD_VM_FBD_VR__58 "Signal contains parameters";
CM_ SG_ 905 TPBLEParameter_FBD_VM_FBD_VR__59 "Signal contains parameters";
CM_ SG_ 905 TPBLEParameter_FBD_VM_FBD_VR__60 "Signal contains parameters";
CM_ SG_ 905 TPBLEParameter_FBD_VM_FBD_VR__61 "Signal contains parameters";
CM_ SG_ 905 TPBLEParameter_FBD_VM_FBD_VR__62 "Signal contains parameters";
CM_ SG_ 905 TPBLEParameter_FBD_VM_FBD_VR__63 "Signal contains parameters";
CM_ SG_ 905 TPBLEParameter_FBD_VM_FBD_VR__64 "Signal contains parameters";
CM_ SG_ 915 TPBLEParameter_FBD_VR_FBD_VM_Byt "Signal contains parameters";
CM_ SG_ 915 TPBLEParameter_FBD_VR_FBD_VM_B_2 "Signal contains parameters";
CM_ SG_ 915 TPBLEParameter_FBD_VR_FBD_VM_B_3 "Signal contains parameters";
CM_ SG_ 915 TPBLEParameter_FBD_VR_FBD_VM_B_4 "Signal contains parameters";
CM_ SG_ 915 TPBLEParameter_FBD_VR_FBD_VM_B_5 "Signal contains parameters";
CM_ SG_ 915 TPBLEParameter_FBD_VR_FBD_VM_B_6 "Signal contains parameters";
CM_ SG_ 915 TPBLEParameter_FBD_VR_FBD_VM_B_7 "Signal contains parameters";
CM_ SG_ 915 TPBLEParameter_FBD_VR_FBD_VM_B_8 "Signal contains parameters";
CM_ SG_ 915 TPBLEParameter_FBD_VR_FBD_VM_B_9 "Signal contains parameters";
CM_ SG_ 915 TPBLEParameter_FBD_VR_FBD_VM__10 "Signal contains parameters";
CM_ SG_ 915 TPBLEParameter_FBD_VR_FBD_VM__11 "Signal contains parameters";
CM_ SG_ 915 TPBLEParameter_FBD_VR_FBD_VM__12 "Signal contains parameters";
CM_ SG_ 915 TPBLEParameter_FBD_VR_FBD_VM__13 "Signal contains parameters";
CM_ SG_ 915 TPBLEParameter_FBD_VR_FBD_VM__14 "Signal contains parameters";
CM_ SG_ 915 TPBLEParameter_FBD_VR_FBD_VM__15 "Signal contains parameters";
CM_ SG_ 915 TPBLEParameter_FBD_VR_FBD_VM__16 "Signal contains parameters";
CM_ SG_ 915 TPBLEParameter_FBD_VR_FBD_VM__17 "Signal contains parameters";
CM_ SG_ 915 TPBLEParameter_FBD_VR_FBD_VM__18 "Signal contains parameters";
CM_ SG_ 915 TPBLEParameter_FBD_VR_FBD_VM__19 "Signal contains parameters";
CM_ SG_ 915 TPBLEParameter_FBD_VR_FBD_VM__20 "Signal contains parameters";
CM_ SG_ 915 TPBLEParameter_FBD_VR_FBD_VM__21 "Signal contains parameters";
CM_ SG_ 915 TPBLEParameter_FBD_VR_FBD_VM__22 "Signal contains parameters";
CM_ SG_ 915 TPBLEParameter_FBD_VR_FBD_VM__23 "Signal contains parameters";
CM_ SG_ 915 TPBLEParameter_FBD_VR_FBD_VM__24 "Signal contains parameters";
CM_ SG_ 915 TPBLEParameter_FBD_VR_FBD_VM__25 "Signal contains parameters";
CM_ SG_ 915 TPBLEParameter_FBD_VR_FBD_VM__26 "Signal contains parameters";
CM_ SG_ 915 TPBLEParameter_FBD_VR_FBD_VM__27 "Signal contains parameters";
CM_ SG_ 915 TPBLEParameter_FBD_VR_FBD_VM__28 "Signal contains parameters";
CM_ SG_ 915 TPBLEParameter_FBD_VR_FBD_VM__29 "Signal contains parameters";
CM_ SG_ 915 TPBLEParameter_FBD_VR_FBD_VM__30 "Signal contains parameters";
CM_ SG_ 915 TPBLEParameter_FBD_VR_FBD_VM__31 "Signal contains parameters";
CM_ SG_ 915 TPBLEParameter_FBD_VR_FBD_VM__32 "Signal contains parameters";
CM_ SG_ 915 TPBLEParameter_FBD_VR_FBD_VM__33 "Signal contains parameters";
CM_ SG_ 915 TPBLEParameter_FBD_VR_FBD_VM__34 "Signal contains parameters";
CM_ SG_ 915 TPBLEParameter_FBD_VR_FBD_VM__35 "Signal contains parameters";
CM_ SG_ 915 TPBLEParameter_FBD_VR_FBD_VM__36 "Signal contains parameters";
CM_ SG_ 915 TPBLEParameter_FBD_VR_FBD_VM__37 "Signal contains parameters";
CM_ SG_ 915 TPBLEParameter_FBD_VR_FBD_VM__38 "Signal contains parameters";
CM_ SG_ 915 TPBLEParameter_FBD_VR_FBD_VM__39 "Signal contains parameters";
CM_ SG_ 915 TPBLEParameter_FBD_VR_FBD_VM__40 "Signal contains parameters";
CM_ SG_ 915 TPBLEParameter_FBD_VR_FBD_VM__41 "Signal contains parameters";
CM_ SG_ 915 TPBLEParameter_FBD_VR_FBD_VM__42 "Signal contains parameters";
CM_ SG_ 915 TPBLEParameter_FBD_VR_FBD_VM__43 "Signal contains parameters";
CM_ SG_ 915 TPBLEParameter_FBD_VR_FBD_VM__44 "Signal contains parameters";
CM_ SG_ 915 TPBLEParameter_FBD_VR_FBD_VM__45 "Signal contains parameters";
CM_ SG_ 915 TPBLEParameter_FBD_VR_FBD_VM__46 "Signal contains parameters";
CM_ SG_ 915 TPBLEParameter_FBD_VR_FBD_VM__47 "Signal contains parameters";
CM_ SG_ 915 TPBLEParameter_FBD_VR_FBD_VM__48 "Signal contains parameters";
CM_ SG_ 915 TPBLEParameter_FBD_VR_FBD_VM__49 "Signal contains parameters";
CM_ SG_ 915 TPBLEParameter_FBD_VR_FBD_VM__50 "Signal contains parameters";
CM_ SG_ 915 TPBLEParameter_FBD_VR_FBD_VM__51 "Signal contains parameters";
CM_ SG_ 915 TPBLEParameter_FBD_VR_FBD_VM__52 "Signal contains parameters";
CM_ SG_ 915 TPBLEParameter_FBD_VR_FBD_VM__53 "Signal contains parameters";
CM_ SG_ 915 TPBLEParameter_FBD_VR_FBD_VM__54 "Signal contains parameters";
CM_ SG_ 915 TPBLEParameter_FBD_VR_FBD_VM__55 "Signal contains parameters";
CM_ SG_ 915 TPBLEParameter_FBD_VR_FBD_VM__56 "Signal contains parameters";
CM_ SG_ 915 TPBLEParameter_FBD_VR_FBD_VM__57 "Signal contains parameters";
CM_ SG_ 915 TPBLEParameter_FBD_VR_FBD_VM__58 "Signal contains parameters";
CM_ SG_ 915 TPBLEParameter_FBD_VR_FBD_VM__59 "Signal contains parameters";
CM_ SG_ 915 TPBLEParameter_FBD_VR_FBD_VM__60 "Signal contains parameters";
CM_ SG_ 915 TPBLEParameter_FBD_VR_FBD_VM__61 "Signal contains parameters";
CM_ SG_ 915 TPBLEParameter_FBD_VR_FBD_VM__62 "Signal contains parameters";
CM_ SG_ 915 TPBLEParameter_FBD_VR_FBD_VM__63 "Signal contains parameters";
CM_ SG_ 915 TPBLEParameter_FBD_VR_FBD_VM__64 "Signal contains parameters";
CM_ SG_ 403 UpdateRangingSessionPriority_Add "addressing of the UWB anchors";
CM_ SG_ 403 UpdateRangingSessionPriority_Ses "definition of Session-ID 1";
CM_ SG_ 403 UpdateRangingSessionPriority_Val "level of priority of Session-ID 1";
CM_ SG_ 403 UpdateRangingSessionPriority_S_2 "definition of Session-ID 2";
CM_ SG_ 403 UpdateRangingSessionPriority_V_2 "level of priority of Session-ID 2";
CM_ SG_ 403 UpdateRangingSessionPriority_S_3 "definition of Session-ID 3";
CM_ SG_ 403 UpdateRangingSessionPriority_V_3 "level of priority of Session-ID 3";
CM_ SG_ 166 WakeUpFBDOnlyMode_HL_PowerMode "set power mode of FBD";
CM_ SG_ 161 WakeUpFBDOnlyMode_HM_PowerMode "set power mode of FBD";
CM_ SG_ 167 WakeUpFBDOnlyMode_HR_PowerMode "set power mode of FBD";
CM_ SG_ 162 WakeUpFBDOnlyMode_Miko_PowerMode "set power mode of FBD";
CM_ SG_ 180 WakeUpFBDOnlyMode_MM_PowerMode "set power mode of FBD";
CM_ SG_ 180 WakeUpFBDOnlyMode_MM_IRKListID "contains Session-ID";
CM_ SG_ 168 WakeUpFBDOnlyMode_SML_PowerMode "set power mode of FBD";
CM_ SG_ 169 WakeUpFBDOnlyMode_SMR_PowerMode "set power mode of FBD";
CM_ SG_ 163 WakeUpFBDOnlyMode_Trunk_PowerMod "set power mode of FBD";
CM_ SG_ 164 WakeUpFBDOnlyMode_VL_PowerMode "set power mode of FBD";
CM_ SG_ 160 WakeUpFBDOnlyMode_VM_PowerMode "set power mode of FBD";
CM_ SG_ 165 WakeUpFBDOnlyMode_VR_PowerMode "set power mode of FBD";

BA_DEF_ BO_ "VFrameFormat" ENUM "StandardCAN","ExtendedCAN","reserved","J1939PG","reserved","reserved","reserved","reserved","reserved","reserved","reserved","reserved","reserved","reserved","StandardCAN_FD","ExtendedCAN_FD";
BA_DEF_DEF_ "VFrameFormat" "StandardCAN";
BA_ "VFrameFormat" BO_ 900 14;
BA_ "VFrameFormat" BO_ 903 14;
BA_ "VFrameFormat" BO_ 904 14;
BA_ "VFrameFormat" BO_ 905 14;
BA_ "VFrameFormat" BO_ 915 14;
BA_ "VFrameFormat" BO_ 716 14;
BA_ "VFrameFormat" BO_ 711 14;
BA_ "VFrameFormat" BO_ 717 14;
BA_ "VFrameFormat" BO_ 712 14;
BA_ "VFrameFormat" BO_ 870 14;
BA_ "VFrameFormat" BO_ 713 14;
BA_ "VFrameFormat" BO_ 714 14;
BA_ "VFrameFormat" BO_ 710 14;
BA_ "VFrameFormat" BO_ 715 14;
BA_ "VFrameFormat" BO_ 706 14;
BA_ "VFrameFormat" BO_ 701 14;
BA_ "VFrameFormat" BO_ 707 14;
BA_ "VFrameFormat" BO_ 702 14;
BA_ "VFrameFormat" BO_ 871 14;
BA_ "VFrameFormat" BO_ 703 14;
BA_ "VFrameFormat" BO_ 704 14;
BA_ "VFrameFormat" BO_ 700 14;
BA_ "VFrameFormat" BO_ 705 14;
